VERSION "dbc-export 1 2025.20.8"

NS_ :

BS_:

BU_: ADSP APB APP APS APSB BB BMS CC CMP CMPD CP DAS DI DIF DIR DPB EPAS3P EPAS3S EPASTP EPASTS EPBL EPBR ESP EVSE FC GTW HCML HCMR HVP IBST ICR IDB LS OCS1P ODIN PARK PCS PLG PM PMF PMR PNCD PTC RADC RCM RCM2 RCM3 RCU SCCM SCM SCS SDCR TAS TCU TPMS TRCM UDS UI UIS UMC USM VC VCFRONT VCLEFT VCRIGHT VCSEC VEH

BO_ 1471 RCU_alertLog: 8 RCU
 SG_ RCU_alertID M : 0|6@1+ (1,0) [0|63] "" Vector__XXX
 SG_ RCU_alertState : 15|1@1+ (1,0) [0|1] "" Vector__XXX
 SG_ RCU_a010_sensorPowerSupply m10 : 16|1@1+ (1,0) [0|1] "" Vector__XXX
 SG_ RCU_a010_sensorHardware m10 : 17|1@1+ (1,0) [0|1] "" Vector__XXX
 SG_ RCU_a010_sensorSignal m10 : 18|1@1+ (1,0) [0|1] "" Vector__XXX
 SG_ RCU_a023_validityOnChassisBus m23 : 16|1@1+ (1,0) [0|1] "" Vector__XXX
 SG_ RCU_a023_validityOnPartyBus m23 : 17|1@1+ (1,0) [0|1] "" Vector__XXX
 SG_ RCU_a024_validityOnChassisBus m24 : 16|1@1+ (1,0) [0|1] "" Vector__XXX
 SG_ RCU_a024_validityOnPartyBus m24 : 17|1@1+ (1,0) [0|1] "" Vector__XXX
 SG_ RCU_a025_validityOnChassisBus m25 : 16|1@1+ (1,0) [0|1] "" Vector__XXX
 SG_ RCU_a025_validityOnPartyBus m25 : 17|1@1+ (1,0) [0|1] "" Vector__XXX
 SG_ RCU_a035_validityOnChassisBus m35 : 16|1@1+ (1,0) [0|1] "" Vector__XXX
 SG_ RCU_a035_validityOnPartyBus m35 : 17|1@1+ (1,0) [0|1] "" Vector__XXX
 SG_ RCU_a036_validityOnChassisBus m36 : 16|1@1+ (1,0) [0|1] "" Vector__XXX
 SG_ RCU_a036_validityOnPartyBus m36 : 17|1@1+ (1,0) [0|1] "" Vector__XXX

BO_ 998 RCU_alertMatrix: 8 RCU
 SG_ RCU_matrixIndex M : 0|4@1+ (1,0) [0|15] "" Vector__XXX
 SG_ RCU_a001_valveDriverFault m0 : 4|1@1+ (1,0) [0|1] "" Vector__XXX
 SG_ RCU_a002_solenoidValveFault m0 : 5|1@1+ (1,0) [0|1] "" Vector__XXX
 SG_ RCU_a003_pumpMotorFault m0 : 6|1@1+ (1,0) [0|1] "" Vector__XXX
 SG_ RCU_a004_supplyOvervoltage m0 : 7|1@1+ (1,0) [0|1] "" Vector__XXX
 SG_ RCU_a005_supplyUndervoltage m0 : 8|1@1+ (1,0) [0|1] "" Vector__XXX
 SG_ RCU_a006_wakeLineOpen m0 : 9|1@1+ (1,0) [0|1] "" Vector__XXX
 SG_ RCU_a007_pressureSensorFault m0 : 10|1@1+ (1,0) [0|1] "" Vector__XXX
 SG_ RCU_a008_pressureNotCalibrated m0 : 11|1@1+ (1,0) [0|1] "" Vector__XXX
 SG_ RCU_a009_brakeFluidLow m0 : 12|1@1+ (1,0) [0|1] "" Vector__XXX
 SG_ RCU_a010_pedalSensorFault m0 : 13|1@1+ (1,0) [0|1] "" Vector__XXX
 SG_ RCU_a011_idbPedalTravelMismatch m0 : 14|1@1+ (1,0) [0|1] "" Vector__XXX
 SG_ RCU_a012_pedalSensorNotCal m0 : 15|1@1+ (1,0) [0|1] "" Vector__XXX
 SG_ RCU_a013_mcuGenericFault m0 : 16|1@1+ (1,0) [0|1] "" Vector__XXX
 SG_ RCU_a014_asicTempHigh m0 : 17|1@1+ (1,0) [0|1] "" Vector__XXX
 SG_ RCU_a015_fluidLeakDetected m0 : 18|1@1+ (1,0) [0|1] "" Vector__XXX
 SG_ RCU_a016_partyBusOff m0 : 19|1@1+ (1,0) [0|1] "" Vector__XXX
 SG_ RCU_a017_chassisBusOff m0 : 20|1@1+ (1,0) [0|1] "" Vector__XXX
 SG_ RCU_a018_DItorquePathFaulted m0 : 21|1@1+ (1,0) [0|1] "" Vector__XXX
 SG_ RCU_a019_DItorquePathActive m0 : 22|1@1+ (1,0) [0|1] "" Vector__XXX
 SG_ RCU_a020_BBstatusDLC m0 : 23|1@1+ (1,0) [0|1] "" Vector__XXX
 SG_ RCU_a021_BBstatusChecksum m0 : 24|1@1+ (1,0) [0|1] "" Vector__XXX
 SG_ RCU_a022_BBstatusCounter m0 : 25|1@1+ (1,0) [0|1] "" Vector__XXX
 SG_ RCU_a023_IDBstatusDLC m0 : 26|1@1+ (1,0) [0|1] "" Vector__XXX
 SG_ RCU_a024_IDBstatusChecksum m0 : 27|1@1+ (1,0) [0|1] "" Vector__XXX
 SG_ RCU_a025_IDBstatusCounter m0 : 28|1@1+ (1,0) [0|1] "" Vector__XXX
 SG_ RCU_a026_DIchassisControlDLC m0 : 29|1@1+ (1,0) [0|1] "" Vector__XXX
 SG_ RCU_a027_DIchassisCtrlChecksum m0 : 30|1@1+ (1,0) [0|1] "" Vector__XXX
 SG_ RCU_a028_DIchassisControlCounter m0 : 31|1@1+ (1,0) [0|1] "" Vector__XXX
 SG_ RCU_a029_PMstate2DLC m0 : 32|1@1+ (1,0) [0|1] "" Vector__XXX
 SG_ RCU_a030_PMstate2Checksum m0 : 33|1@1+ (1,0) [0|1] "" Vector__XXX
 SG_ RCU_a031_PMstate2Counter m0 : 34|1@1+ (1,0) [0|1] "" Vector__XXX
 SG_ RCU_a032_VCFRONTLVPowerStateDLC m0 : 35|1@1+ (1,0) [0|1] "" Vector__XXX
 SG_ RCU_a033_VCFRONTLVPowerStateChec m0 : 36|1@1+ (1,0) [0|1] "" Vector__XXX
 SG_ RCU_a034_VCFRONTLVPowerStateCoun m0 : 37|1@1+ (1,0) [0|1] "" Vector__XXX
 SG_ RCU_a035_IDBpcpInvalid m0 : 38|1@1+ (1,0) [0|1] "" Vector__XXX
 SG_ RCU_a036_IDBpspInvalid m0 : 39|1@1+ (1,0) [0|1] "" Vector__XXX
 SG_ RCU_a037_IDBinputRodStrokeInvali m0 : 40|1@1+ (1,0) [0|1] "" Vector__XXX
 SG_ RCU_a038_DIsystemStatusDLC m0 : 41|1@1+ (1,0) [0|1] "" Vector__XXX
 SG_ RCU_a039_DIaccelPosInvalid m0 : 42|1@1+ (1,0) [0|1] "" Vector__XXX
 SG_ RCU_a040_DIgearInvalid m0 : 43|1@1+ (1,0) [0|1] "" Vector__XXX
 SG_ RCU_a041_DIsystemStatusCounter m0 : 44|1@1+ (1,0) [0|1] "" Vector__XXX
 SG_ RCU_a042_DIsystemStatusChecksum m0 : 45|1@1+ (1,0) [0|1] "" Vector__XXX
 SG_ RCU_a043_VCFRONTiBoosterLvStateI m0 : 46|1@1+ (1,0) [0|1] "" Vector__XXX
 SG_ RCU_a044_VCFRONTsensorsMIA m0 : 47|1@1+ (1,0) [0|1] "" Vector__XXX
 SG_ RCU_a045_VCFRONTtempInvalid m0 : 48|1@1+ (1,0) [0|1] "" Vector__XXX
 SG_ RCU_a046_brakeFluidLevelSNA m0 : 49|1@1+ (1,0) [0|1] "" Vector__XXX
 SG_ RCU_a047_ESPwheelSpeedsDLC m0 : 50|1@1+ (1,0) [0|1] "" Vector__XXX
 SG_ RCU_a048_ESPFrLWSSLInvalid m0 : 51|1@1+ (1,0) [0|1] "" Vector__XXX
 SG_ RCU_a049_ESPFrRWSSLInvalid m0 : 52|1@1+ (1,0) [0|1] "" Vector__XXX
 SG_ RCU_a050_ESPReLWSSLInvalid m0 : 53|1@1+ (1,0) [0|1] "" Vector__XXX
 SG_ RCU_a051_ESPReRWSSLInvalid m0 : 54|1@1+ (1,0) [0|1] "" Vector__XXX
 SG_ RCU_a052_ESPwheelSpeedsCounter m0 : 55|1@1+ (1,0) [0|1] "" Vector__XXX
 SG_ RCU_a053_ESPwheelSpeedsChecksum m0 : 56|1@1+ (1,0) [0|1] "" Vector__XXX
 SG_ RCU_a054_IDBcircuitPressFaulted m0 : 57|1@1+ (1,0) [0|1] "" Vector__XXX
 SG_ RCU_a055_IDBsimulatorPressFaulte m0 : 58|1@1+ (1,0) [0|1] "" Vector__XXX
 SG_ RCU_a056_redundantControllerIsMa m0 : 59|1@1+ (1,0) [0|1] "" Vector__XXX
 SG_ RCU_a057_PMebrCmdStateInvalid m0 : 60|1@1+ (1,0) [0|1] "" Vector__XXX
 SG_ RCU_a058_DIbrakeTorqueCommandAnd m0 : 61|1@1+ (1,0) [0|1] "" Vector__XXX

BO_ 831 RCU_info: 8 RCU
 SG_ RCU_infoIndex M : 0|8@1+ (1,0) [0|255] "" Vector__XXX
 SG_ RCU_infoPcbaID m11 : 16|8@1+ (1,0) [0|255] "" Vector__XXX
 SG_ RCU_infoAssemblyID m11 : 24|8@1+ (1,0) [0|255] "" Vector__XXX
 SG_ RCU_infoUsageID m11 : 32|16@1+ (1,0) [0|65535] "" Vector__XXX
 SG_ RCU_infoSubUsageID m11 : 48|16@1+ (1,0) [0|65535] "" Vector__XXX

BO_ 1344 SCCM_alertLog: 8 SCCM
 SG_ SCCM_alertID M : 0|15@1+ (1,0) [0|32767] "" Vector__XXX
 SG_ SCCM_alertState : 15|1@1+ (1,0) [0|1] "" Vector__XXX
 SG_ SCCM_a003_debouncePosition m3 : 16|8@1+ (1,0) [0|255] "-" Vector__XXX
 SG_ SCCM_a003_rawPosition m3 : 24|8@1+ (1,0) [0|255] "-" Vector__XXX
 SG_ SCCM_a003_errorPosition m3 : 32|8@1+ (1,0) [0|255] "-" Vector__XXX
 SG_ SCCM_a003_adcValue m3 : 40|8@1+ (1,0) [0|255] "-" Vector__XXX
 SG_ SCCM_a004_debouncePosition m4 : 16|8@1+ (1,0) [0|255] "-" Vector__XXX
 SG_ SCCM_a004_rawPosition m4 : 24|8@1+ (1,0) [0|255] "-" Vector__XXX
 SG_ SCCM_a004_errorPosition m4 : 32|8@1+ (1,0) [0|255] "-" Vector__XXX
 SG_ SCCM_a004_adcValue m4 : 40|8@1+ (1,0) [0|255] "-" Vector__XXX
 SG_ SCCM_a005_debouncePosition m5 : 16|8@1+ (1,0) [0|255] "-" Vector__XXX
 SG_ SCCM_a005_rawPosition m5 : 24|8@1+ (1,0) [0|255] "-" Vector__XXX
 SG_ SCCM_a005_errorPosition m5 : 32|8@1+ (1,0) [0|255] "-" Vector__XXX
 SG_ SCCM_a005_adcValue m5 : 40|8@1+ (1,0) [0|255] "-" Vector__XXX
 SG_ SCCM_a006_debouncePosition m6 : 16|8@1+ (1,0) [0|255] "-" Vector__XXX
 SG_ SCCM_a006_rawPosition m6 : 24|8@1+ (1,0) [0|255] "-" Vector__XXX
 SG_ SCCM_a006_errorPosition m6 : 32|8@1+ (1,0) [0|255] "-" Vector__XXX
 SG_ SCCM_a006_adcValue m6 : 40|8@1+ (1,0) [0|255] "-" Vector__XXX
 SG_ SCCM_a007_debouncePosition m7 : 16|8@1+ (1,0) [0|255] "-" Vector__XXX
 SG_ SCCM_a007_rawPosition m7 : 24|8@1+ (1,0) [0|255] "-" Vector__XXX
 SG_ SCCM_a007_errorPosition m7 : 32|8@1+ (1,0) [0|255] "-" Vector__XXX
 SG_ SCCM_a007_adcValue1 m7 : 40|8@1+ (1,0) [0|255] "-" Vector__XXX
 SG_ SCCM_a007_adcValue2 m7 : 48|8@1+ (1,0) [0|255] "-" Vector__XXX
 SG_ SCCM_a008_debouncePosition m8 : 16|8@1+ (1,0) [0|255] "-" Vector__XXX
 SG_ SCCM_a008_rawPosition m8 : 24|8@1+ (1,0) [0|255] "-" Vector__XXX
 SG_ SCCM_a008_errorPosition m8 : 32|8@1+ (1,0) [0|255] "-" Vector__XXX
 SG_ SCCM_a008_adcValue1 m8 : 40|8@1+ (1,0) [0|255] "-" Vector__XXX
 SG_ SCCM_a008_adcValue2 m8 : 48|8@1+ (1,0) [0|255] "-" Vector__XXX
 SG_ SCCM_a009_debouncePosition m9 : 16|8@1+ (1,0) [0|255] "-" Vector__XXX
 SG_ SCCM_a009_rawPosition m9 : 24|8@1+ (1,0) [0|255] "-" Vector__XXX
 SG_ SCCM_a009_errorPosition m9 : 32|8@1+ (1,0) [0|255] "-" Vector__XXX
 SG_ SCCM_a009_adcValue1 m9 : 40|8@1+ (1,0) [0|255] "-" Vector__XXX
 SG_ SCCM_a009_adcValue2 m9 : 48|8@1+ (1,0) [0|255] "-" Vector__XXX
 SG_ SCCM_a010_debouncePosition m10 : 16|8@1+ (1,0) [0|255] "-" Vector__XXX
 SG_ SCCM_a010_rawPosition m10 : 24|8@1+ (1,0) [0|255] "-" Vector__XXX
 SG_ SCCM_a010_errorPosition m10 : 32|8@1+ (1,0) [0|255] "-" Vector__XXX
 SG_ SCCM_a010_adcValue1 m10 : 40|8@1+ (1,0) [0|255] "-" Vector__XXX
 SG_ SCCM_a010_adcValue2 m10 : 48|8@1+ (1,0) [0|255] "-" Vector__XXX
 SG_ SCCM_a011_debouncePosition m11 : 16|8@1+ (1,0) [0|255] "-" Vector__XXX
 SG_ SCCM_a011_rawPosition m11 : 24|8@1+ (1,0) [0|255] "-" Vector__XXX
 SG_ SCCM_a011_errorPosition m11 : 32|8@1+ (1,0) [0|255] "-" Vector__XXX
 SG_ SCCM_a011_adcValue1 m11 : 40|8@1+ (1,0) [0|255] "-" Vector__XXX
 SG_ SCCM_a011_adcValue2 m11 : 48|8@1+ (1,0) [0|255] "-" Vector__XXX
 SG_ SCCM_a012_debouncePosition m12 : 16|8@1+ (1,0) [0|255] "-" Vector__XXX
 SG_ SCCM_a012_rawPosition m12 : 24|8@1+ (1,0) [0|255] "-" Vector__XXX
 SG_ SCCM_a012_errorPosition m12 : 32|8@1+ (1,0) [0|255] "-" Vector__XXX
 SG_ SCCM_a012_adcValue1 m12 : 40|8@1+ (1,0) [0|255] "-" Vector__XXX
 SG_ SCCM_a012_adcValue2 m12 : 48|8@1+ (1,0) [0|255] "-" Vector__XXX
 SG_ SCCM_a013_voltage m13 : 16|8@1+ (1,0) [0|255] "-" Vector__XXX
 SG_ SCCM_a014_voltage m14 : 16|8@1+ (1,0) [0|255] "-" Vector__XXX
 SG_ SCCM_a015_intMainIndex m15 : 16|8@1+ (1,0) [0|255] "-" Vector__XXX
 SG_ SCCM_a015_intSubIndex m15 : 24|8@1+ (1,0) [0|255] "-" Vector__XXX
 SG_ SCCM_a015_intMemIndex m15 : 32|8@1+ (1,0) [0|255] "-" Vector__XXX
 SG_ SCCM_a016_mainAdcTest m16 : 16|4@1+ (1,0) [0|15] "-" Vector__XXX
 SG_ SCCM_a016_mainCpuTest m16 : 20|4@1+ (1,0) [0|15] "-" Vector__XXX
 SG_ SCCM_a016_wdtTest m16 : 24|4@1+ (1,0) [0|15] "-" Vector__XXX
 SG_ SCCM_a016_subCpuTest m16 : 28|4@1+ (1,0) [0|15] "-" Vector__XXX
 SG_ SCCM_a016_subAdcTest m16 : 32|4@1+ (1,0) [0|15] "-" Vector__XXX
 SG_ SCCM_a017_mainRamTest m17 : 16|4@1+ (1,0) [0|15] "-" Vector__XXX
 SG_ SCCM_a017_mainRomTest m17 : 20|4@1+ (1,0) [0|15] "-" Vector__XXX
 SG_ SCCM_a017_stackHardLimitTest m17 : 24|4@1+ (1,0) [0|15] "-" Vector__XXX
 SG_ SCCM_a017_mainDataFlashTest m17 : 28|4@1+ (1,0) [0|15] "-" Vector__XXX
 SG_ SCCM_a017_subRamTest m17 : 32|4@1+ (1,0) [0|15] "-" Vector__XXX
 SG_ SCCM_a017_subRomTest m17 : 36|4@1+ (1,0) [0|15] "-" Vector__XXX
 SG_ SCCM_a017_subStackHardLimitTest m17 : 40|4@1+ (1,0) [0|15] "-" Vector__XXX
 SG_ SCCM_a017_svError m17 : 44|16@1+ (1,0) [0|65535] "-" Vector__XXX
 SG_ SCCM_a018_internalSASState m18 : 16|8@1+ (1,0) [0|255] "-" Vector__XXX
 SG_ SCCM_a019_internalSASState m19 : 16|8@1+ (1,0) [0|255] "-" Vector__XXX
 SG_ SCCM_a020_internalSASState m20 : 16|8@1+ (1,0) [0|255] "-" Vector__XXX
 SG_ SCCM_a021_adcValue1 m21 : 16|8@1+ (1,0) [0|255] "-" Vector__XXX
 SG_ SCCM_a021_adcValue2 m21 : 24|8@1+ (1,0) [0|255] "-" Vector__XXX
 SG_ SCCM_a021_adcValue3 m21 : 32|8@1+ (1,0) [0|255] "-" Vector__XXX
 SG_ SCCM_a021_adcValue4 m21 : 40|8@1+ (1,0) [0|255] "-" Vector__XXX
 SG_ SCCM_a021_adcValue5 m21 : 48|8@1+ (1,0) [0|255] "-" Vector__XXX
 SG_ SCCM_a021_adcValue6 m21 : 56|8@1+ (1,0) [0|255] "-" Vector__XXX
 SG_ SCCM_a022_adcValue1 m22 : 16|8@1+ (1,0) [0|255] "-" Vector__XXX
 SG_ SCCM_a022_adcValue2 m22 : 24|8@1+ (1,0) [0|255] "-" Vector__XXX
 SG_ SCCM_a022_adcValue3 m22 : 32|8@1+ (1,0) [0|255] "-" Vector__XXX
 SG_ SCCM_a022_adcValue4 m22 : 40|8@1+ (1,0) [0|255] "-" Vector__XXX
 SG_ SCCM_a022_adcValue5 m22 : 48|8@1+ (1,0) [0|255] "-" Vector__XXX
 SG_ SCCM_a022_adcValue6 m22 : 56|8@1+ (1,0) [0|255] "-" Vector__XXX
 SG_ SCCM_a023_adcValue1 m23 : 16|8@1+ (1,0) [0|255] "-" Vector__XXX
 SG_ SCCM_a023_adcValue2 m23 : 24|8@1+ (1,0) [0|255] "-" Vector__XXX
 SG_ SCCM_a023_adcValue3 m23 : 32|8@1+ (1,0) [0|255] "-" Vector__XXX
 SG_ SCCM_a023_adcValue4 m23 : 40|8@1+ (1,0) [0|255] "-" Vector__XXX
 SG_ SCCM_a023_adcValue5 m23 : 48|8@1+ (1,0) [0|255] "-" Vector__XXX
 SG_ SCCM_a023_adcValue6 m23 : 56|8@1+ (1,0) [0|255] "-" Vector__XXX
 SG_ SCCM_a024_adcValue1 m24 : 16|8@1+ (1,0) [0|255] "-" Vector__XXX
 SG_ SCCM_a024_adcValue2 m24 : 24|8@1+ (1,0) [0|255] "-" Vector__XXX
 SG_ SCCM_a024_adcValue3 m24 : 32|8@1+ (1,0) [0|255] "-" Vector__XXX
 SG_ SCCM_a024_adcValue4 m24 : 40|8@1+ (1,0) [0|255] "-" Vector__XXX
 SG_ SCCM_a024_adcValue5 m24 : 48|8@1+ (1,0) [0|255] "-" Vector__XXX
 SG_ SCCM_a024_adcValue6 m24 : 56|8@1+ (1,0) [0|255] "-" Vector__XXX
 SG_ SCCM_a025_taskState m25 : 16|16@1+ (1,0) [0|65535] "-" Vector__XXX
 SG_ SCCM_a026_debouncePosition m26 : 16|8@1+ (1,0) [0|255] "-" Vector__XXX
 SG_ SCCM_a026_rawPosition m26 : 24|8@1+ (1,0) [0|255] "-" Vector__XXX
 SG_ SCCM_a026_errorPosition m26 : 32|8@1+ (1,0) [0|255] "-" Vector__XXX
 SG_ SCCM_a026_adcValue1 m26 : 40|8@1+ (1,0) [0|255] "-" Vector__XXX
 SG_ SCCM_a026_adcValue2 m26 : 48|8@1+ (1,0) [0|255] "-" Vector__XXX
 SG_ SCCM_a027_debouncePosition m27 : 16|8@1+ (1,0) [0|255] "-" Vector__XXX
 SG_ SCCM_a027_rawPosition m27 : 24|8@1+ (1,0) [0|255] "-" Vector__XXX
 SG_ SCCM_a027_errorPosition m27 : 32|8@1+ (1,0) [0|255] "-" Vector__XXX
 SG_ SCCM_a027_adcValue1 m27 : 40|8@1+ (1,0) [0|255] "-" Vector__XXX
 SG_ SCCM_a027_adcValue2 m27 : 48|8@1+ (1,0) [0|255] "-" Vector__XXX
 SG_ SCCM_a028_debouncePosition m28 : 16|8@1+ (1,0) [0|255] "-" Vector__XXX
 SG_ SCCM_a028_rawPosition m28 : 24|8@1+ (1,0) [0|255] "-" Vector__XXX
 SG_ SCCM_a028_errorPosition m28 : 32|8@1+ (1,0) [0|255] "-" Vector__XXX
 SG_ SCCM_a028_adcValue1 m28 : 40|8@1+ (1,0) [0|255] "-" Vector__XXX
 SG_ SCCM_a028_adcValue2 m28 : 48|8@1+ (1,0) [0|255] "-" Vector__XXX
 SG_ SCCM_a029_debouncePosition m29 : 16|8@1+ (1,0) [0|255] "-" Vector__XXX
 SG_ SCCM_a029_rawPosition m29 : 24|8@1+ (1,0) [0|255] "-" Vector__XXX
 SG_ SCCM_a029_errorPosition m29 : 32|8@1+ (1,0) [0|255] "-" Vector__XXX
 SG_ SCCM_a029_adcValue1 m29 : 40|8@1+ (1,0) [0|255] "-" Vector__XXX
 SG_ SCCM_a029_adcValue2 m29 : 48|8@1+ (1,0) [0|255] "-" Vector__XXX
 SG_ SCCM_a061_voltage m61 : 16|8@1+ (0.1,0) [0|25.5] "V" Vector__XXX
 SG_ SCCM_a062_voltage m62 : 16|8@1+ (0.1,0) [0|25.5] "V" Vector__XXX
 SG_ SCCM_a063_UntrimmedAngle m63 : 16|16@1+ (0.1,-819.2) [-819.2|5734.3] "deg" Vector__XXX
 SG_ SCCM_a064_Speed m64 : 16|16@1+ (0.5,-4096) [-4096|28671.5] "deg/s" Vector__XXX
 SG_ SCCM_a065_M1RawAngleCurrent m65 : 16|12@1+ (0.08791209,0) [0|360.00000855] "deg" Vector__XXX
 SG_ SCCM_a065_M1RawAnglePrevious m65 : 28|12@1+ (0.08791209,0) [0|360.00000855] "deg" Vector__XXX
 SG_ SCCM_a065_M2RawAngleCurrent m65 : 40|12@1+ (0.08791209,0) [0|360.00000855] "deg" Vector__XXX
 SG_ SCCM_a065_M2RawAnglePrevious m65 : 52|12@1+ (0.08791209,0) [0|360.00000855] "deg" Vector__XXX
 SG_ SCCM_a066_M1RawAngleCurrent m66 : 16|12@1+ (0.08791209,0) [0|360.00000855] "deg" Vector__XXX
 SG_ SCCM_a066_M1RawAnglePrevious m66 : 28|12@1+ (0.08791209,0) [0|360.00000855] "deg" Vector__XXX
 SG_ SCCM_a066_M2RawAngleCurrent m66 : 40|12@1+ (0.08791209,0) [0|360.00000855] "deg" Vector__XXX
 SG_ SCCM_a066_M2RawAnglePrevious m66 : 52|12@1+ (0.08791209,0) [0|360.00000855] "deg" Vector__XXX
 SG_ SCCM_a071_M1LogicBISTFailed m71 : 16|1@1+ (1,0) [0|1] "" Vector__XXX
 SG_ SCCM_a071_M1PowerOnReset m71 : 17|1@1+ (1,0) [0|1] "" Vector__XXX
 SG_ SCCM_a071_M1UnderVoltage m71 : 18|1@1+ (1,0) [0|1] "" Vector__XXX
 SG_ SCCM_a071_M1OverVoltage m71 : 19|1@1+ (1,0) [0|1] "" Vector__XXX
 SG_ SCCM_a071_M1DualBitError m71 : 20|1@1+ (1,0) [0|1] "" Vector__XXX
 SG_ SCCM_a071_M1RefVoltageOutOfRange m71 : 21|1@1+ (1,0) [0|1] "" Vector__XXX
 SG_ SCCM_a071_M1RegisterParityError m71 : 22|1@1+ (1,0) [0|1] "" Vector__XXX
 SG_ SCCM_a071_M1OscillatorFreqError m71 : 23|1@1+ (1,0) [0|1] "" Vector__XXX
 SG_ SCCM_a071_M1SignalOutOfRange m71 : 24|1@1+ (1,0) [0|1] "" Vector__XXX
 SG_ SCCM_a071_M1TempOutOfRange m71 : 25|1@1+ (1,0) [0|1] "" Vector__XXX
 SG_ SCCM_a071_M1AngleMismatch m71 : 26|1@1+ (1,0) [0|1] "" Vector__XXX
 SG_ SCCM_a071_M1RadiusOutOfRange m71 : 27|1@1+ (1,0) [0|1] "" Vector__XXX
 SG_ SCCM_a071_M2LogicBISTFailed m71 : 28|1@1+ (1,0) [0|1] "" Vector__XXX
 SG_ SCCM_a071_M2PowerOnReset m71 : 29|1@1+ (1,0) [0|1] "" Vector__XXX
 SG_ SCCM_a071_M2UnderVoltage m71 : 30|1@1+ (1,0) [0|1] "" Vector__XXX
 SG_ SCCM_a071_M2OverVoltage m71 : 31|1@1+ (1,0) [0|1] "" Vector__XXX
 SG_ SCCM_a071_M2DualBitError m71 : 32|1@1+ (1,0) [0|1] "" Vector__XXX
 SG_ SCCM_a071_M2RefVoltageOutOfRange m71 : 33|1@1+ (1,0) [0|1] "" Vector__XXX
 SG_ SCCM_a071_M2RegisterParityError m71 : 34|1@1+ (1,0) [0|1] "" Vector__XXX
 SG_ SCCM_a071_M2OscillatorFreqError m71 : 35|1@1+ (1,0) [0|1] "" Vector__XXX
 SG_ SCCM_a071_M2SignalOutOfRange m71 : 36|1@1+ (1,0) [0|1] "" Vector__XXX
 SG_ SCCM_a071_M2TempOutOfRange m71 : 37|1@1+ (1,0) [0|1] "" Vector__XXX
 SG_ SCCM_a071_M2AngleMismatch m71 : 38|1@1+ (1,0) [0|1] "" Vector__XXX
 SG_ SCCM_a071_M2RadiusOutOfRange m71 : 39|1@1+ (1,0) [0|1] "" Vector__XXX
 SG_ SCCM_a071_M1ProcessLogicFailed m71 : 40|1@1+ (1,0) [0|1] "" Vector__XXX
 SG_ SCCM_a071_M2ProcessLogicFailed m71 : 41|1@1+ (1,0) [0|1] "" Vector__XXX
 SG_ SCCM_a071_TSOSCHighFreqError m71 : 42|1@1+ (1,0) [0|1] "" Vector__XXX
 SG_ SCCM_a071_TSOSCLowFreqError m71 : 43|1@1+ (1,0) [0|1] "" Vector__XXX
 SG_ SCCM_a071_TSOPRStatMismatch m71 : 44|1@1+ (1,0) [0|1] "" Vector__XXX
 SG_ SCCM_a071_TSCRCStatError m71 : 45|1@1+ (1,0) [0|1] "" Vector__XXX
 SG_ SCCM_a071_TSFrameStatError m71 : 46|1@1+ (1,0) [0|1] "" Vector__XXX
 SG_ SCCM_a071_TSOverVoltage m71 : 47|1@1+ (1,0) [0|1] "" Vector__XXX
 SG_ SCCM_a071_TSUnderVoltage m71 : 48|1@1+ (1,0) [0|1] "" Vector__XXX
 SG_ SCCM_a071_TSPowerOnReset m71 : 49|1@1+ (1,0) [0|1] "" Vector__XXX
 SG_ SCCM_a071_TSLDOStatError m71 : 50|1@1+ (1,0) [0|1] "" Vector__XXX
 SG_ SCCM_a071_TSTempOutOfRange m71 : 51|1@1+ (1,0) [0|1] "" Vector__XXX
 SG_ SCCM_a071_TSAlertIntegrityCheck m71 : 52|1@1+ (1,0) [0|1] "" Vector__XXX
 SG_ SCCM_a071_TSMemoryCRCError m71 : 53|1@1+ (1,0) [0|1] "" Vector__XXX
 SG_ SCCM_a071_TSAFECheck m71 : 54|1@1+ (1,0) [0|1] "" Vector__XXX
 SG_ SCCM_a071_TSADCCheck m71 : 55|1@1+ (1,0) [0|1] "" Vector__XXX
 SG_ SCCM_a071_TSConfigFault m71 : 56|1@1+ (1,0) [0|1] "" Vector__XXX
 SG_ SCCM_a072_M1CRCCalculated m72 : 16|4@1+ (1,0) [0|15] "" Vector__XXX
 SG_ SCCM_a072_M1CRCReceived m72 : 20|4@1+ (1,0) [0|15] "" Vector__XXX
 SG_ SCCM_a072_M2CRCCalculated m72 : 24|4@1+ (1,0) [0|15] "" Vector__XXX
 SG_ SCCM_a072_M2CRCReceived m72 : 28|4@1+ (1,0) [0|15] "" Vector__XXX
 SG_ SCCM_a072_TSCRCCalculated m72 : 32|4@1+ (1,0) [0|15] "" Vector__XXX
 SG_ SCCM_a072_TSCRCReceived m72 : 36|4@1+ (1,0) [0|15] "" Vector__XXX
 SG_ SCCM_a075_ClockOutOfRange m75 : 16|1@1+ (1,0) [0|1] "" Vector__XXX
 SG_ SCCM_a075_ExtWatchdogTestFailed m75 : 17|1@1+ (1,0) [0|1] "" Vector__XXX
 SG_ SCCM_a075_InterruptMonitorError m75 : 18|1@1+ (1,0) [0|1] "" Vector__XXX
 SG_ SCCM_a076_RAMTestFailed m76 : 16|1@1+ (1,0) [0|1] "" Vector__XXX
 SG_ SCCM_a076_NVMTestFailed m76 : 17|1@1+ (1,0) [0|1] "" Vector__XXX
 SG_ SCCM_a077_M1ExpectAngleCurrent m77 : 16|12@1+ (0.08791209,0) [0|360.00000855] "deg" Vector__XXX
 SG_ SCCM_a077_M1ExpectAnglePrevious m77 : 28|12@1+ (0.08791209,0) [0|360.00000855] "deg" Vector__XXX
 SG_ SCCM_a077_M1AngleCurrent m77 : 40|12@1+ (0.08791209,0) [0|360.00000855] "deg" Vector__XXX
 SG_ SCCM_a077_M1AnglePrevious m77 : 52|12@1+ (0.08791209,0) [0|360.00000855] "deg" Vector__XXX
 SG_ SCCM_a079_ChipTemperature m79 : 16|11@1+ (0.1,-50) [-50|154.7] "degC" Vector__XXX
 SG_ SCCM_a081_StartupTestStatus m81 : 16|3@1+ (1,0) [0|7] "" Vector__XXX
 SG_ SCCM_a081_sCheckTestFailedData m81 : 19|8@1+ (1,0) [0|255] "" Vector__XXX
 SG_ SCCM_a081_sBootTestFailedData m81 : 27|16@1+ (1,0) [0|65535] "" Vector__XXX
 SG_ SCCM_a081_BISTTestFailedData m81 : 43|16@1+ (1,0) [0|65535] "" Vector__XXX
 SG_ SCCM_a082_RuntimeTestStatus m82 : 16|2@1+ (1,0) [0|3] "" Vector__XXX
 SG_ SCCM_a082_sCheckTestFailedData m82 : 18|8@1+ (1,0) [0|255] "" Vector__XXX
 SG_ SCCM_a082_ArrayIntegrFailedData m82 : 26|8@1+ (1,0) [0|255] "" Vector__XXX
 SG_ SCCM_a121_turnIndicatorStalkAngl m121 : 16|12@1+ (0.1,-180) [-180|229.5] "deg" Vector__XXX
 SG_ SCCM_a121_turnIndicatorHallAngle m121 : 28|12@1+ (0.1,-180) [-180|229.5] "deg" Vector__XXX
 SG_ SCCM_a122_turnIndicatorSpeed m122 : 16|12@1+ (0.02,-36) [-36|45.9] "deg/ms" Vector__XXX
 SG_ SCCM_a123_turnIndicatorStalkAngl m123 : 16|12@1+ (0.1,-180) [-180|229.5] "deg" Vector__XXX
 SG_ SCCM_a124_turnIndicatorStalkAngl m124 : 16|12@1+ (0.1,-180) [-180|229.5] "deg" Vector__XXX
 SG_ SCCM_a125_turnIndicatorHallAngle m125 : 16|12@1+ (0.1,-180) [-180|229.5] "deg" Vector__XXX
 SG_ SCCM_a125_turnIndicatorVectorAng m125 : 28|12@1+ (0.1,-180) [-180|229.5] "deg" Vector__XXX
 SG_ SCCM_a126_turnIndicatorXVectorOu m126 : 16|1@1+ (1,0) [0|1] "" Vector__XXX
 SG_ SCCM_a126_turnIndicatorYVectorOu m126 : 17|1@1+ (1,0) [0|1] "" Vector__XXX
 SG_ SCCM_a126_turnIndicatorZVectorOu m126 : 18|1@1+ (1,0) [0|1] "" Vector__XXX
 SG_ SCCM_a126_turnIndicatorResu_0001 m126 : 19|1@1+ (1,0) [0|1] "" Vector__XXX
 SG_ SCCM_a126_turnIndicatorXMagnitud m126 : 24|8@1+ (1,0) [0|255] "mT" Vector__XXX
 SG_ SCCM_a126_turnIndicatorYMagnitud m126 : 32|8@1+ (1,0) [0|255] "mT" Vector__XXX
 SG_ SCCM_a126_turnIndicatorZMagnitud m126 : 40|8@1+ (1,0) [0|255] "mT" Vector__XXX
 SG_ SCCM_a126_turnIndicatorResultant m126 : 48|8@1+ (1,0) [0|255] "mT" Vector__XXX

BO_ 1359 SCCM_alertMatrix: 8 SCCM
 SG_ SCCM_matrixIndex M : 0|4@1+ (1,0) [0|15] "" Vector__XXX
 SG_ SCCM_a001_CANBusOff m0 : 4|1@1+ (1,0) [0|1] "" Vector__XXX
 SG_ SCCM_a002_CANTOut m0 : 5|1@1+ (1,0) [0|1] "" Vector__XXX
 SG_ SCCM_a003_highBeamOpen m0 : 6|1@1+ (1,0) [0|1] "" Vector__XXX
 SG_ SCCM_a004_highBeamShortToGND m0 : 7|1@1+ (1,0) [0|1] "" Vector__XXX
 SG_ SCCM_a005_tipWipeOpen m0 : 8|1@1+ (1,0) [0|1] "" Vector__XXX
 SG_ SCCM_a006_tipWipeShortToGND m0 : 9|1@1+ (1,0) [0|1] "" Vector__XXX
 SG_ SCCM_a007_turnIndComInfo m0 : 10|1@1+ (1,0) [0|1] "" Vector__XXX
 SG_ SCCM_a008_turnIndInvalidTrans m0 : 11|1@1+ (1,0) [0|1] "" Vector__XXX
 SG_ SCCM_a009_turnIndOpen m0 : 12|1@1+ (1,0) [0|1] "" Vector__XXX
 SG_ SCCM_a010_turnIndShortToGnd m0 : 13|1@1+ (1,0) [0|1] "" Vector__XXX
 SG_ SCCM_a011_turnIndHWErr m0 : 14|1@1+ (1,0) [0|1] "" Vector__XXX
 SG_ SCCM_a012_turnGenErr m0 : 15|1@1+ (1,0) [0|1] "" Vector__XXX
 SG_ SCCM_a013_voltageHigh m0 : 16|1@1+ (1,0) [0|1] "" Vector__XXX
 SG_ SCCM_a014_voltageLow m0 : 17|1@1+ (1,0) [0|1] "" Vector__XXX
 SG_ SCCM_a015_softwareError m0 : 18|1@1+ (1,0) [0|1] "" Vector__XXX
 SG_ SCCM_a016_hardwareError m0 : 19|1@1+ (1,0) [0|1] "" Vector__XXX
 SG_ SCCM_a017_memoryError m0 : 20|1@1+ (1,0) [0|1] "" Vector__XXX
 SG_ SCCM_a018_angleSpeedOutOfRange m0 : 21|1@1+ (1,0) [0|1] "" Vector__XXX
 SG_ SCCM_a019_angleOutOfRange m0 : 22|1@1+ (1,0) [0|1] "" Vector__XXX
 SG_ SCCM_a020_angleInternalError m0 : 23|1@1+ (1,0) [0|1] "" Vector__XXX
 SG_ SCCM_a021_gearStalkSignalInvalid m0 : 24|1@1+ (1,0) [0|1] "" Vector__XXX
 SG_ SCCM_a022_gearStalkOpenCircuit m0 : 25|1@1+ (1,0) [0|1] "" Vector__XXX
 SG_ SCCM_a023_gearStalkShortCircuit m0 : 26|1@1+ (1,0) [0|1] "" Vector__XXX
 SG_ SCCM_a024_gearStalkGenErr m0 : 27|1@1+ (1,0) [0|1] "" Vector__XXX
 SG_ SCCM_a025_runTimeError m0 : 28|1@1+ (1,0) [0|1] "" Vector__XXX
 SG_ SCCM_a026_parkButtonInvalidSigna m0 : 29|1@1+ (1,0) [0|1] "" Vector__XXX
 SG_ SCCM_a027_parkButtonOpenCircuit m0 : 30|1@1+ (1,0) [0|1] "" Vector__XXX
 SG_ SCCM_a028_parkButtonShortToGroun m0 : 31|1@1+ (1,0) [0|1] "" Vector__XXX
 SG_ SCCM_a029_parkButtonMalfunction m0 : 32|1@1+ (1,0) [0|1] "" Vector__XXX
 SG_ SCCM_a061_voltageHigh_2 m1 : 4|1@1+ (1,0) [0|1] "" Vector__XXX
 SG_ SCCM_a062_voltageLow_2 m1 : 5|1@1+ (1,0) [0|1] "" Vector__XXX
 SG_ SCCM_a063_angleOutOfRange_2 m1 : 6|1@1+ (1,0) [0|1] "" Vector__XXX
 SG_ SCCM_a064_angleSpeedOutOfRange_2 m1 : 7|1@1+ (1,0) [0|1] "" Vector__XXX
 SG_ SCCM_a065_angleNotPlausible m1 : 8|1@1+ (1,0) [0|1] "" Vector__XXX
 SG_ SCCM_a066_angleSpeedNotPlausible m1 : 9|1@1+ (1,0) [0|1] "" Vector__XXX
 SG_ SCCM_a067_CANBusOff_2 m1 : 10|1@1+ (1,0) [0|1] "" Vector__XXX
 SG_ SCCM_a068_CANLVPowerState_LOC m1 : 11|1@1+ (1,0) [0|1] "" Vector__XXX
 SG_ SCCM_a069_calibrationMismatch m1 : 12|1@1+ (1,0) [0|1] "" Vector__XXX
 SG_ SCCM_a070_angleTrimMismatch m1 : 13|1@1+ (1,0) [0|1] "" Vector__XXX
 SG_ SCCM_a071_angleHallSensorError m1 : 14|1@1+ (1,0) [0|1] "" Vector__XXX
 SG_ SCCM_a072_spiBitErrors m1 : 15|1@1+ (1,0) [0|1] "" Vector__XXX
 SG_ SCCM_a073_watchdogReset m1 : 16|1@1+ (1,0) [0|1] "" Vector__XXX
 SG_ SCCM_a074_PLLLossOfLock m1 : 17|1@1+ (1,0) [0|1] "" Vector__XXX
 SG_ SCCM_a075_hardwareError_2 m1 : 18|1@1+ (1,0) [0|1] "" Vector__XXX
 SG_ SCCM_a076_memoryError_2 m1 : 19|1@1+ (1,0) [0|1] "" Vector__XXX
 SG_ SCCM_a077_gearAngleNotPlausible m1 : 20|1@1+ (1,0) [0|1] "" Vector__XXX
 SG_ SCCM_a078_ADCCalibrationError m1 : 21|1@1+ (1,0) [0|1] "" Vector__XXX
 SG_ SCCM_a079_chipTempOutOfRange m1 : 22|1@1+ (1,0) [0|1] "" Vector__XXX
 SG_ SCCM_a080_ADCSelfTestFailed m1 : 23|1@1+ (1,0) [0|1] "" Vector__XXX
 SG_ SCCM_a081_startupTestFailed m1 : 24|1@1+ (1,0) [0|1] "" Vector__XXX
 SG_ SCCM_a082_runtimeTestFailed m1 : 25|1@1+ (1,0) [0|1] "" Vector__XXX
 SG_ SCCM_a121_turnIndicatorAngleInva m2 : 4|1@1+ (1,0) [0|1] "" Vector__XXX
 SG_ SCCM_a122_turnIndicatorSpeedInva m2 : 5|1@1+ (1,0) [0|1] "" Vector__XXX
 SG_ SCCM_a123_turnIndicatorStuckActi m2 : 6|1@1+ (1,0) [0|1] "" Vector__XXX
 SG_ SCCM_a124_turnIndicatorIdleInval m2 : 7|1@1+ (1,0) [0|1] "" Vector__XXX
 SG_ SCCM_a125_turnIndicatorHallAngle m2 : 8|1@1+ (1,0) [0|1] "" Vector__XXX
 SG_ SCCM_a126_turnIndicatorHallMagOu m2 : 9|1@1+ (1,0) [0|1] "" Vector__XXX

BO_ 816 SCCM_info: 8 SCCM
 SG_ SCCM_infoIndex M : 0|8@1+ (1,0) [0|255] "" Vector__XXX
 SG_ SCCM_infoBuildType m10 : 8|8@1+ (1,0) [0|255] "" Vector__XXX
 SG_ SCCM_infoBuildConfigId m10 : 16|16@1+ (1,0) [0|65535] "" Vector__XXX
 SG_ SCCM_infoHardwareId m10 : 32|16@1+ (1,0) [0|65535] "" Vector__XXX
 SG_ SCCM_infoComponentId m10 : 48|16@1+ (1,0) [0|65535] "" Vector__XXX
 SG_ SCCM_infoPcbaId m11 : 16|8@1+ (1,0) [0|255] "" Vector__XXX
 SG_ SCCM_infoAssemblyId m11 : 24|8@1+ (1,0) [0|255] "" Vector__XXX
 SG_ SCCM_infoUsageId m11 : 32|16@1+ (1,0) [0|65535] "" Vector__XXX
 SG_ SCCM_infoSubUsageId m11 : 48|16@1+ (1,0) [0|65535] "" Vector__XXX
 SG_ SCCM_infoPlatformType m13 : 8|8@1+ (1,0) [0|255] "" Vector__XXX
 SG_ SCCM_infoAppCrc m13 : 39|32@0+ (1,0) [0|4294967295] "" Vector__XXX
 SG_ SCCM_infoBootSvnRev m14 : 8|24@1+ (1,0) [0|16777215] "" Vector__XXX
 SG_ SCCM_infoBootSvnUrlHash m14 : 32|32@1+ (1,0) [0|4294967295] "" Vector__XXX
 SG_ SCCM_infoSubcomponent1Version m16 : 16|32@1+ (1,0) [0|4294967295] "" Vector__XXX
 SG_ SCCM_infoAppSvnHash m17 : 8|56@1+ (1,0) [0|7.20575940379e+16] "" Vector__XXX
 SG_ SCCM_infoBootSvnHash m18 : 8|56@1+ (1,0) [0|7.20575940379e+16] "" Vector__XXX
 SG_ SCCM_infoUdsProtoVersion m20 : 8|8@1+ (1,0) [0|255] "" Vector__XXX
 SG_ SCCM_infoBootCrc m20 : 32|32@1+ (1,0) [0|4294967295] "" Vector__XXX

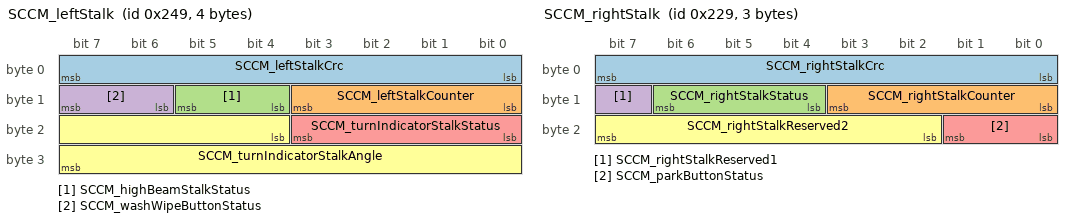
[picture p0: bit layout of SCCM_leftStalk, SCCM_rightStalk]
BO_ 585 SCCM_leftStalk: 4 SCCM
 SG_ SCCM_leftStalkCrc : 0|8@1+ (1,0) [0|255] "" Vector__XXX
 SG_ SCCM_leftStalkCounter : 8|4@1+ (1,0) [0|15] "" Vector__XXX
 SG_ SCCM_highBeamStalkStatus : 12|2@1+ (1,0) [0|2] "" Vector__XXX
 SG_ SCCM_washWipeButtonStatus : 14|2@1+ (1,0) [0|2] "" Vector__XXX
 SG_ SCCM_turnIndicatorStalkStatus : 16|4@1+ (1,0) [0|15] "" Vector__XXX
 SG_ SCCM_turnIndicatorStalkAngle : 20|12@1+ (0.1,-180) [-180|180] "deg" Vector__XXX

BO_ 553 SCCM_rightStalk: 3 SCCM
 SG_ SCCM_rightStalkCrc : 0|8@1+ (1,0) [0|255] "" Vector__XXX
 SG_ SCCM_rightStalkCounter : 8|4@1+ (1,0) [0|15] "" Vector__XXX
 SG_ SCCM_rightStalkStatus : 12|3@1+ (1,0) [0|7] "" Vector__XXX
 SG_ SCCM_rightStalkReserved1 : 15|1@1+ (1,0) [0|1] "" Vector__XXX
 SG_ SCCM_parkButtonStatus : 16|2@1+ (1,0) [0|2] "" Vector__XXX
 SG_ SCCM_rightStalkReserved2 : 18|6@1+ (1,0) [0|63] "" Vector__XXX

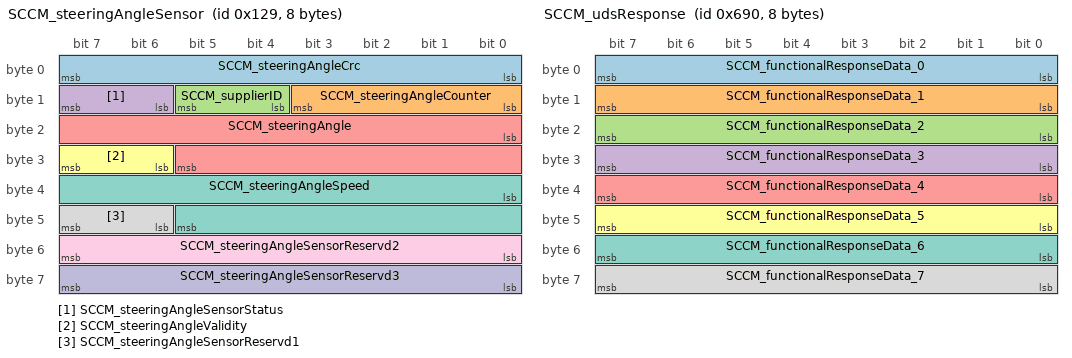
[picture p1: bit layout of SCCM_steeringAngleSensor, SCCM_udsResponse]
BO_ 297 SCCM_steeringAngleSensor: 8 SCCM
 SG_ SCCM_steeringAngleCrc : 0|8@1+ (1,0) [0|255] "" Vector__XXX
 SG_ SCCM_steeringAngleCounter : 8|4@1+ (1,0) [0|15] "" Vector__XXX
 SG_ SCCM_supplierID : 12|2@1+ (1,0) [0|3] "" Vector__XXX
 SG_ SCCM_steeringAngleSensorStatus : 14|2@1+ (1,0) [0|3] "" Vector__XXX
 SG_ SCCM_steeringAngle : 16|14@1+ (0.1,-819.2) [-819.2|819] "deg" Vector__XXX
 SG_ SCCM_steeringAngleValidity : 30|2@1+ (1,0) [0|2] "" Vector__XXX
 SG_ SCCM_steeringAngleSpeed : 32|14@1+ (0.5,-4096) [-4096|4095.5] "deg/s" Vector__XXX
 SG_ SCCM_steeringAngleSensorReservd1 : 46|2@1+ (1,0) [0|3] "" Vector__XXX
 SG_ SCCM_steeringAngleSensorReservd2 : 48|8@1+ (1,0) [0|255] "" Vector__XXX
 SG_ SCCM_steeringAngleSensorReservd3 : 56|8@1+ (1,0) [0|255] "" Vector__XXX

BO_ 1680 SCCM_udsResponse: 8 SCCM
 SG_ SCCM_functionalResponseData_0 : 7|8@0+ (1,0) [0|255] "" Vector__XXX
 SG_ SCCM_functionalResponseData_1 : 15|8@0+ (1,0) [0|255] "" Vector__XXX
 SG_ SCCM_functionalResponseData_2 : 23|8@0+ (1,0) [0|255] "" Vector__XXX
 SG_ SCCM_functionalResponseData_3 : 31|8@0+ (1,0) [0|255] "" Vector__XXX
 SG_ SCCM_functionalResponseData_4 : 39|8@0+ (1,0) [0|255] "" Vector__XXX
 SG_ SCCM_functionalResponseData_5 : 47|8@0+ (1,0) [0|255] "" Vector__XXX
 SG_ SCCM_functionalResponseData_6 : 55|8@0+ (1,0) [0|255] "" Vector__XXX
 SG_ SCCM_functionalResponseData_7 : 63|8@0+ (1,0) [0|255] "" Vector__XXX

BO_ 1356 SCM_alertLog: 8 SCM
 SG_ SCM_alertID M : 0|15@1+ (1,0) [0|32767] "" Vector__XXX
 SG_ SCM_alertType : 15|1@1+ (1,0) [0|1] "" Vector__XXX
 SG_ SCM_a074_voltageWithRo m74 : 16|12@1+ (1,0) [0|4095] "" Vector__XXX
 SG_ SCM_a074_voltageWithoutRo m74 : 28|12@1+ (1,0) [0|4095] "" Vector__XXX

BO_ 815 SCM_alertMatrix1: 8 SCM
 SG_ SCM_a027_externalIsolationLow : 26|1@1+ (1,0) [0|1] "" Vector__XXX
 SG_ SCM_a044_proximityRationality : 43|1@1+ (1,0) [0|1] "" Vector__XXX

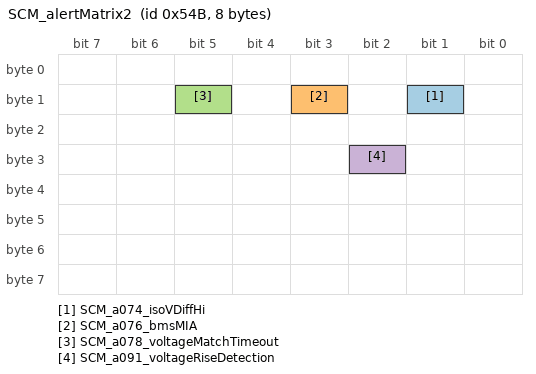
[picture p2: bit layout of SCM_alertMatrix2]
BO_ 1355 SCM_alertMatrix2: 8 SCM
 SG_ SCM_a074_isoVDiffHi : 9|1@1+ (1,0) [0|1] "" Vector__XXX
 SG_ SCM_a076_bmsMIA : 11|1@1+ (1,0) [0|1] "" Vector__XXX
 SG_ SCM_a078_voltageMatchTimeout : 13|1@1+ (1,0) [0|1] "" Vector__XXX
 SG_ SCM_a091_voltageRiseDetection : 26|1@1+ (1,0) [0|1] "" Vector__XXX

BO_ 1354 SCS_alertLog: 8 SCS
 SG_ SCS_alertID M : 0|15@1+ (1,0) [0|32767] "" Vector__XXX
 SG_ SCS_alertType : 15|1@1+ (1,0) [0|1] "" Vector__XXX
 SG_ SCS_a044_proximityV m44 : 16|16@1+ (0.0001,0) [0|6.5535] "V" Vector__XXX
 SG_ SCS_a074_voltageWithRo m74 : 16|12@1+ (0.146520152688,0) [0|600.000025257] "V" Vector__XXX
 SG_ SCS_a074_voltageWithoutRo m74 : 28|12@1+ (0.146520152688,0) [0|600.000025257] "V" Vector__XXX

BO_ 869 SCS_alertMatrix1: 8 SCS
 SG_ SCS_a001_hwDSPfault : 0|1@1+ (1,0) [0|1] "" Vector__XXX
 SG_ SCS_a002_hwIbatOC : 1|1@1+ (1,0) [0|1] "" Vector__XXX
 SG_ SCS_a003_hwCordOT : 2|1@1+ (1,0) [0|1] "" Vector__XXX
 SG_ SCS_a004_hwVbusOV : 3|1@1+ (1,0) [0|1] "" Vector__XXX
 SG_ SCS_a005_hwHVIL : 4|1@1+ (1,0) [0|1] "" Vector__XXX
 SG_ SCS_a006_hwWeld_V1 : 5|1@1+ (1,0) [0|1] "" Vector__XXX
 SG_ SCS_a007_hwWeld_V2 : 6|1@1+ (1,0) [0|1] "" Vector__XXX
 SG_ SCS_a008_hwIllegalCntrShoot : 7|1@1+ (1,0) [0|1] "" Vector__XXX
 SG_ SCS_a009_hwOpen_V1 : 8|1@1+ (1,0) [0|1] "" Vector__XXX
 SG_ SCS_a010_hwOpen_V2 : 9|1@1+ (1,0) [0|1] "" Vector__XXX
 SG_ SCS_a011_hwIllegalCntrCmdV1 : 10|1@1+ (1,0) [0|1] "" Vector__XXX
 SG_ SCS_a012_hwIllegalCntrCmdV2 : 11|1@1+ (1,0) [0|1] "" Vector__XXX
 SG_ SCS_a013_cordTempHiFoldBk : 12|1@1+ (1,0) [0|1] "" Vector__XXX
 SG_ SCS_a014_coolantTempHiFoldBk : 13|1@1+ (1,0) [0|1] "" Vector__XXX
 SG_ SCS_a015_cpldRationality : 14|1@1+ (1,0) [0|1] "" Vector__XXX
 SG_ SCS_a016_unusedHW16 : 15|1@1+ (1,0) [0|1] "" Vector__XXX
 SG_ SCS_a017_unusedHW17 : 16|1@1+ (1,0) [0|1] "" Vector__XXX
 SG_ SCS_a018_unusedHW18 : 17|1@1+ (1,0) [0|1] "" Vector__XXX
 SG_ SCS_a019_unusedHW19 : 18|1@1+ (1,0) [0|1] "" Vector__XXX
 SG_ SCS_a020_unusedHW20 : 19|1@1+ (1,0) [0|1] "" Vector__XXX
 SG_ SCS_a021_unusedHW21 : 20|1@1+ (1,0) [0|1] "" Vector__XXX
 SG_ SCS_a024_emergencyShutdown : 23|1@1+ (1,0) [0|1] "" Vector__XXX
 SG_ SCS_a025_internalIsolationFault : 24|1@1+ (1,0) [0|1] "" Vector__XXX
 SG_ SCS_a026_internalIsolationLow : 25|1@1+ (1,0) [0|1] "" Vector__XXX
 SG_ SCS_a027_externalIsolationLow : 26|1@1+ (1,0) [0|1] "" Vector__XXX
 SG_ SCS_a028_isolationRationality : 27|1@1+ (1,0) [0|1] "" Vector__XXX
 SG_ SCS_a029_VbatOV : 28|1@1+ (1,0) [0|1] "" Vector__XXX
 SG_ SCS_a030_VbusOV : 29|1@1+ (1,0) [0|1] "" Vector__XXX
 SG_ SCS_a031_IbatOC : 30|1@1+ (1,0) [0|1] "" Vector__XXX
 SG_ SCS_a032_VBatRationality : 31|1@1+ (1,0) [0|1] "" Vector__XXX
 SG_ SCS_a033_VBusRationality : 32|1@1+ (1,0) [0|1] "" Vector__XXX
 SG_ SCS_a034_IBatRationality : 33|1@1+ (1,0) [0|1] "" Vector__XXX
 SG_ SCS_a035_unexpectedVbusBehavior : 34|1@1+ (1,0) [0|1] "" Vector__XXX
 SG_ SCS_a036_internalContactorWelded : 35|1@1+ (1,0) [0|1] "" Vector__XXX
 SG_ SCS_a037_outputContactorWelded : 36|1@1+ (1,0) [0|1] "" Vector__XXX
 SG_ SCS_a038_contactorFailedOpen : 37|1@1+ (1,0) [0|1] "" Vector__XXX
 SG_ SCS_a039_ibatRegulation : 38|1@1+ (1,0) [0|1] "" Vector__XXX
 SG_ SCS_a040_plus12VOutOfRange : 39|1@1+ (1,0) [0|1] "" Vector__XXX
 SG_ SCS_a041_minus12VOutOfRange : 40|1@1+ (1,0) [0|1] "" Vector__XXX
 SG_ SCS_a042_pilotOutOfRange : 41|1@1+ (1,0) [0|1] "" Vector__XXX
 SG_ SCS_a043_pilotRationality : 42|1@1+ (1,0) [0|1] "" Vector__XXX
 SG_ SCS_a044_proximityRationality : 43|1@1+ (1,0) [0|1] "" Vector__XXX
 SG_ SCS_a045_pcbaOT : 44|1@1+ (1,0) [0|1] "" Vector__XXX
 SG_ SCS_a046_coolantOT : 45|1@1+ (1,0) [0|1] "" Vector__XXX
 SG_ SCS_a047_cordOT : 46|1@1+ (1,0) [0|1] "" Vector__XXX
 SG_ SCS_a048_ambientOT : 47|1@1+ (1,0) [0|1] "" Vector__XXX
 SG_ SCS_a049_pcbaTempRationality : 48|1@1+ (1,0) [0|1] "" Vector__XXX
 SG_ SCS_a050_coolantTempRationality : 49|1@1+ (1,0) [0|1] "" Vector__XXX
 SG_ SCS_a051_cordTempRationality : 50|1@1+ (1,0) [0|1] "" Vector__XXX
 SG_ SCS_a052_ambientTempRationality : 51|1@1+ (1,0) [0|1] "" Vector__XXX
 SG_ SCS_a053_unexpectedThermalBehavi : 52|1@1+ (1,0) [0|1] "" Vector__XXX
 SG_ SCS_a054_pumpRegulation : 53|1@1+ (1,0) [0|1] "" Vector__XXX
 SG_ SCS_a055_coolantLevelLow : 54|1@1+ (1,0) [0|1] "" Vector__XXX
 SG_ SCS_a056_stateTransitionDenied : 55|1@1+ (1,0) [0|1] "" Vector__XXX
 SG_ SCS_a057_watchdogReset : 56|1@1+ (1,0) [0|1] "" Vector__XXX
 SG_ SCS_a058_adcRef : 57|1@1+ (1,0) [0|1] "" Vector__XXX
 SG_ SCS_a059_memoryError : 58|1@1+ (1,0) [0|1] "" Vector__XXX
 SG_ SCS_a060_swHVIL : 59|1@1+ (1,0) [0|1] "" Vector__XXX
 SG_ SCS_a061_postOutOfService : 60|1@1+ (1,0) [0|1] "" Vector__XXX
 SG_ SCS_a062_unused : 61|1@1+ (1,0) [0|1] "" Vector__XXX
 SG_ SCS_a063_canRationality : 62|1@1+ (1,0) [0|1] "" Vector__XXX
 SG_ SCS_a064_vehicleCommandTimeout : 63|1@1+ (1,0) [0|1] "" Vector__XXX

BO_ 880 SCS_alertMatrix2: 8 SCS
 SG_ SCS_a065_vBatRationalityStage1 : 0|1@1+ (1,0) [0|1] "" Vector__XXX
 SG_ SCS_a066_vBatRationalityStage2 : 1|1@1+ (1,0) [0|1] "" Vector__XXX
 SG_ SCS_a067_vBatRationalityStage3 : 2|1@1+ (1,0) [0|1] "" Vector__XXX
 SG_ SCS_a068_vBatRationalityStage4 : 3|1@1+ (1,0) [0|1] "" Vector__XXX
 SG_ SCS_a069_vStageRationalityV1 : 4|1@1+ (1,0) [0|1] "" Vector__XXX
 SG_ SCS_a070_vStageRationalityV2 : 5|1@1+ (1,0) [0|1] "" Vector__XXX
 SG_ SCS_a071_chargerMIA : 6|1@1+ (1,0) [0|1] "" Vector__XXX
 SG_ SCS_a072_gtwMIA : 7|1@1+ (1,0) [0|1] "" Vector__XXX
 SG_ SCS_a073_lccMIA : 8|1@1+ (1,0) [0|1] "" Vector__XXX
 SG_ SCS_a074_isoVDiffHi : 9|1@1+ (1,0) [0|1] "" Vector__XXX
 SG_ SCS_a075_unused75 : 10|1@1+ (1,0) [0|1] "" Vector__XXX
 SG_ SCS_a076_bmsMIA : 11|1@1+ (1,0) [0|1] "" Vector__XXX
 SG_ SCS_a077_unexpectedVbatBehavior : 12|1@1+ (1,0) [0|1] "" Vector__XXX
 SG_ SCS_a078_voltageMatchTimeout : 13|1@1+ (1,0) [0|1] "" Vector__XXX
 SG_ SCS_a079_unexpectedVbat : 14|1@1+ (1,0) [0|1] "" Vector__XXX
 SG_ SCS_a080_lccFaulted : 15|1@1+ (1,0) [0|1] "" Vector__XXX
 SG_ SCS_a081_rmsInputVoltageHigh : 16|1@1+ (1,0) [0|1] "" Vector__XXX
 SG_ SCS_a082_VbatUV : 17|1@1+ (1,0) [0|1] "" Vector__XXX
 SG_ SCS_a083_chargeCurrentLimited : 18|1@1+ (1,0) [0|1] "" Vector__XXX
 SG_ SCS_a084_unused84 : 19|1@1+ (1,0) [0|1] "" Vector__XXX
 SG_ SCS_a085_unused85 : 20|1@1+ (1,0) [0|1] "" Vector__XXX
 SG_ SCS_a086_lccResetDetected : 21|1@1+ (1,0) [0|1] "" Vector__XXX
 SG_ SCS_a087_posCordTempRationality : 22|1@1+ (1,0) [0|1] "" Vector__XXX
 SG_ SCS_a088_negCordTempRationality : 23|1@1+ (1,0) [0|1] "" Vector__XXX
 SG_ SCS_a089_posCordOT : 24|1@1+ (1,0) [0|1] "" Vector__XXX
 SG_ SCS_a090_negCordOT : 25|1@1+ (1,0) [0|1] "" Vector__XXX
 SG_ SCS_a091_voltageRiseDetection : 26|1@1+ (1,0) [0|1] "" Vector__XXX
 SG_ SCS_a092_cabEnableDeasserted : 27|1@1+ (1,0) [0|1] "" Vector__XXX
 SG_ SCS_a093_unused93 : 28|1@1+ (1,0) [0|1] "" Vector__XXX
 SG_ SCS_a094_unused94 : 29|1@1+ (1,0) [0|1] "" Vector__XXX
 SG_ SCS_a095_unused95 : 30|1@1+ (1,0) [0|1] "" Vector__XXX
 SG_ SCS_a096_unused96 : 31|1@1+ (1,0) [0|1] "" Vector__XXX
 SG_ SCS_a097_unused97 : 32|1@1+ (1,0) [0|1] "" Vector__XXX
 SG_ SCS_a098_unused98 : 33|1@1+ (1,0) [0|1] "" Vector__XXX
 SG_ SCS_a099_unused99 : 34|1@1+ (1,0) [0|1] "" Vector__XXX
 SG_ SCS_a100_unused100 : 35|1@1+ (1,0) [0|1] "" Vector__XXX
 SG_ SCS_a101_unused101 : 36|1@1+ (1,0) [0|1] "" Vector__XXX
 SG_ SCS_a102_unused102 : 37|1@1+ (1,0) [0|1] "" Vector__XXX
 SG_ SCS_a103_unused103 : 38|1@1+ (1,0) [0|1] "" Vector__XXX
 SG_ SCS_a104_unused104 : 39|1@1+ (1,0) [0|1] "" Vector__XXX
 SG_ SCS_a105_unused105 : 40|1@1+ (1,0) [0|1] "" Vector__XXX
 SG_ SCS_a106_unused106 : 41|1@1+ (1,0) [0|1] "" Vector__XXX
 SG_ SCS_a107_unused107 : 42|1@1+ (1,0) [0|1] "" Vector__XXX
 SG_ SCS_a108_unused108 : 43|1@1+ (1,0) [0|1] "" Vector__XXX
 SG_ SCS_a109_unused109 : 44|1@1+ (1,0) [0|1] "" Vector__XXX
 SG_ SCS_a110_unused110 : 45|1@1+ (1,0) [0|1] "" Vector__XXX
 SG_ SCS_a111_unused111 : 46|1@1+ (1,0) [0|1] "" Vector__XXX
 SG_ SCS_a112_unused112 : 47|1@1+ (1,0) [0|1] "" Vector__XXX
 SG_ SCS_a113_unused113 : 48|1@1+ (1,0) [0|1] "" Vector__XXX
 SG_ SCS_a114_unused114 : 49|1@1+ (1,0) [0|1] "" Vector__XXX
 SG_ SCS_a115_unused115 : 50|1@1+ (1,0) [0|1] "" Vector__XXX
 SG_ SCS_a116_unused116 : 51|1@1+ (1,0) [0|1] "" Vector__XXX
 SG_ SCS_a117_unused117 : 52|1@1+ (1,0) [0|1] "" Vector__XXX
 SG_ SCS_a118_unused118 : 53|1@1+ (1,0) [0|1] "" Vector__XXX
 SG_ SCS_a119_unused119 : 54|1@1+ (1,0) [0|1] "" Vector__XXX
 SG_ SCS_a120_unused120 : 55|1@1+ (1,0) [0|1] "" Vector__XXX
 SG_ SCS_a121_unused121 : 56|1@1+ (1,0) [0|1] "" Vector__XXX
 SG_ SCS_a122_unused122 : 57|1@1+ (1,0) [0|1] "" Vector__XXX
 SG_ SCS_a123_unused123 : 58|1@1+ (1,0) [0|1] "" Vector__XXX
 SG_ SCS_a124_unused124 : 59|1@1+ (1,0) [0|1] "" Vector__XXX
 SG_ SCS_a125_unused125 : 60|1@1+ (1,0) [0|1] "" Vector__XXX
 SG_ SCS_a126_unused126 : 61|1@1+ (1,0) [0|1] "" Vector__XXX
 SG_ SCS_a127_unused127 : 62|1@1+ (1,0) [0|1] "" Vector__XXX
 SG_ SCS_a128_unused128 : 63|1@1+ (1,0) [0|1] "" Vector__XXX

BO_ 1531 SDCR_alertLog: 8 SDCR
 SG_ SDCR_alertID M : 0|6@1+ (1,0) [0|63] "" Vector__XXX
 SG_ SDCR_alertState : 15|1@1+ (1,0) [0|1] "" Vector__XXX
 SG_ SDCR_a001_pyroSenseV m1 : 16|8@1+ (0.02,0) [0|5.1] "V" Vector__XXX
 SG_ SDCR_a001_HVBackupSupplyV m1 : 24|8@1+ (0.15,0) [0|38.25] "V" Vector__XXX
 SG_ SDCR_a001_boostRailV m1 : 32|8@1+ (0.15,0) [0|38.25] "V" Vector__XXX
 SG_ SDCR_a001_expectedPyroV_max m1 : 40|8@1+ (0.02,0) [0|5.1] "V" Vector__XXX
 SG_ SDCR_a001_expectedPyroV_min m1 : 48|8@1+ (0.02,0) [0|5.1] "V" Vector__XXX
 SG_ SDCR_a001_fromState m1 : 56|3@1+ (1,0) [0|7] "" Vector__XXX
 SG_ SDCR_a004_HVBackupSupplyV m4 : 16|8@1+ (0.15,0) [0|38.25] "V" Vector__XXX
 SG_ SDCR_a004_boostRailV m4 : 24|8@1+ (0.15,0) [0|38.25] "V" Vector__XXX
 SG_ SDCR_a004_diPresent m4 : 32|1@1+ (1,0) [0|1] "" Vector__XXX
 SG_ SDCR_a004_pmRunningPin m4 : 33|1@1+ (1,0) [0|1] "" Vector__XXX
 SG_ SDCR_a006_pyroArmed m6 : 16|1@1+ (1,0) [0|1] "" Vector__XXX
 SG_ SDCR_a006_triggerReason_faultCur m6 : 17|1@1+ (1,0) [0|1] "" Vector__XXX
 SG_ SDCR_a006_triggerReason_hvBadAtS m6 : 18|1@1+ (1,0) [0|1] "" Vector__XXX
 SG_ SDCR_a006_triggerReason_highBack m6 : 19|1@1+ (1,0) [0|1] "" Vector__XXX
 SG_ SDCR_a006_faultCurrentsDetected m6 : 20|1@1+ (1,0) [0|1] "" Vector__XXX
 SG_ SDCR_a006_diUartMIA m6 : 21|1@1+ (1,0) [0|1] "" Vector__XXX
 SG_ SDCR_a006_pmRunningPin m6 : 22|1@1+ (1,0) [0|1] "" Vector__XXX
 SG_ SDCR_a006_hvPowerGood m6 : 23|1@1+ (1,0) [0|1] "" Vector__XXX
 SG_ SDCR_a006_hvbkupPGoodPin m6 : 24|1@1+ (1,0) [0|1] "" Vector__XXX
 SG_ SDCR_a006_hvPowerNotGoodQualifie m6 : 25|1@1+ (1,0) [0|1] "" Vector__XXX
 SG_ SDCR_a006_speedValid m6 : 26|1@1+ (1,0) [0|1] "" Vector__XXX
 SG_ SDCR_a006_speedFromVoltage m6 : 27|1@1+ (1,0) [0|1] "" Vector__XXX
 SG_ SDCR_a006_HVBackupSupplyV m6 : 28|7@1+ (0.3,0) [0|38.1] "V" Vector__XXX
 SG_ SDCR_a006_boostRailV m6 : 35|7@1+ (0.3,0) [0|38.1] "V" Vector__XXX
 SG_ SDCR_a006_maxAbsSpeed m6 : 42|12@1- (1,0) [-2048|2047] "Hz" Vector__XXX
 SG_ SDCR_a006_vBat m6 : 54|7@1+ (8,0) [0|1016] "V" Vector__XXX
 SG_ SDCR_a007_faultReason_faultCurre m7 : 16|1@1+ (1,0) [0|1] "" Vector__XXX
 SG_ SDCR_a007_faultReason_unmitigate m7 : 17|1@1+ (1,0) [0|1] "" Vector__XXX
 SG_ SDCR_a007_faultReason_propagatin m7 : 18|1@1+ (1,0) [0|1] "" Vector__XXX
 SG_ SDCR_a007_speedWasValid m7 : 19|1@1+ (1,0) [0|1] "" Vector__XXX
 SG_ SDCR_a007_imbalanceSeen m7 : 20|1@1+ (1,0) [0|1] "" Vector__XXX
 SG_ SDCR_a007_ucrSeen m7 : 21|1@1+ (1,0) [0|1] "" Vector__XXX
 SG_ SDCR_a007_phaseVoltagePresent m7 : 22|1@1+ (1,0) [0|1] "" Vector__XXX
 SG_ SDCR_a007_speedFromVoltage m7 : 23|1@1+ (1,0) [0|1] "" Vector__XXX
 SG_ SDCR_a007_transientHandling m7 : 24|2@1+ (1,0) [0|3] "" Vector__XXX
 SG_ SDCR_a007_maxAbsElcSpeed m7 : 26|9@1+ (4,0) [0|2044] "Hz" Vector__XXX
 SG_ SDCR_a007_avgIa m7 : 35|10@1- (4,0) [-2048|2044] "A" Vector__XXX
 SG_ SDCR_a007_avgIb m7 : 45|10@1- (4,0) [-2048|2044] "A" Vector__XXX
 SG_ SDCR_a007_maxAbsCurrents m7 : 55|9@1+ (4,0) [0|2044] "A" Vector__XXX
 SG_ SDCR_a008_dcLinkInfo m8 : 16|1@1+ (1,0) [0|1] "" Vector__XXX
 SG_ SDCR_a009_diVersion m9 : 16|2@1+ (1,0) [0|3] "" Vector__XXX
 SG_ SDCR_a009_sdcVersion m9 : 18|2@1+ (1,0) [0|3] "" Vector__XXX
 SG_ SDCR_a010_pgood m10 : 16|1@1+ (1,0) [0|1] "" Vector__XXX
 SG_ SDCR_a010_boostRailV m10 : 24|8@1+ (0.15,0) [0|38.25] "V" Vector__XXX
 SG_ SDCR_a010_Vref m10 : 32|8@1+ (0.02,0) [0|5.1] "V" Vector__XXX
 SG_ SDCR_a011_IaAvg m11 : 16|16@1- (0.1,0) [-3276.8|3276.7] "A" Vector__XXX
 SG_ SDCR_a011_IbAvg m11 : 32|16@1- (0.1,0) [-3276.8|3276.7] "A" Vector__XXX
 SG_ SDCR_a012_boostRailV m12 : 16|8@1+ (0.15,0) [0|38.25] "V" Vector__XXX
 SG_ SDCR_a012_HVBackupSupplyV m12 : 24|8@1+ (0.15,0) [0|38.25] "V" Vector__XXX
 SG_ SDCR_a012_vBat m12 : 32|10@1+ (2,0) [0|2046] "V" Vector__XXX
 SG_ SDCR_a012_vbkupGoodFdbk m12 : 42|1@1+ (1,0) [0|1] "" Vector__XXX
 SG_ SDCR_a013_boostRailV m13 : 16|8@1+ (0.15,0) [0|38.25] "V" Vector__XXX
 SG_ SDCR_a013_HVBackupSupplyV m13 : 24|8@1+ (0.15,0) [0|38.25] "V" Vector__XXX
 SG_ SDCR_a013_vBat m13 : 32|10@1+ (2,0) [0|2046] "V" Vector__XXX
 SG_ SDCR_a013_vbkupGoodFdbk m13 : 42|1@1+ (1,0) [0|1] "" Vector__XXX
 SG_ SDCR_a014_reason_vBusShortedLow m14 : 16|1@1+ (1,0) [0|1] "" Vector__XXX
 SG_ SDCR_a014_reason_vBusShortedHigh m14 : 17|1@1+ (1,0) [0|1] "" Vector__XXX
 SG_ SDCR_a014_boostRailV m14 : 24|8@1+ (0.15,0) [0|38.25] "V" Vector__XXX
 SG_ SDCR_a014_HVBackupSupplyV m14 : 32|8@1+ (0.15,0) [0|38.25] "V" Vector__XXX
 SG_ SDCR_a014_vBat m14 : 40|10@1+ (2,0) [0|2046] "V" Vector__XXX
 SG_ SDCR_a014_vbkupGoodFdbk m14 : 50|1@1+ (1,0) [0|1] "" Vector__XXX
 SG_ SDCR_a015_reason_vPhaseShortedLo m15 : 16|1@1+ (1,0) [0|1] "" Vector__XXX
 SG_ SDCR_a015_reason_vPhaseShortedHi m15 : 17|1@1+ (1,0) [0|1] "" Vector__XXX
 SG_ SDCR_a015_diSwitchingPin m15 : 18|1@1+ (1,0) [0|1] "" Vector__XXX
 SG_ SDCR_a015_vBat m15 : 19|10@1+ (2,0) [0|2046] "V" Vector__XXX
 SG_ SDCR_a015_va m15 : 29|10@1+ (2,0) [0|2046] "V" Vector__XXX
 SG_ SDCR_a015_vb m15 : 40|10@1+ (2,0) [0|2046] "V" Vector__XXX
 SG_ SDCR_a015_vc m15 : 50|10@1+ (2,0) [0|2046] "V" Vector__XXX
 SG_ SDCR_a017_expectedConfigWord m17 : 16|16@1+ (1,0) [0|65535] "" Vector__XXX
 SG_ SDCR_a017_receivedConfigWord m17 : 32|16@1+ (1,0) [0|65535] "" Vector__XXX
 SG_ SDCR_a018_pyroArmed m18 : 16|1@1+ (1,0) [0|1] "" Vector__XXX
 SG_ SDCR_a018_triggerReason_faultCur m18 : 17|1@1+ (1,0) [0|1] "" Vector__XXX
 SG_ SDCR_a018_triggerReason_hvBadAtS m18 : 18|1@1+ (1,0) [0|1] "" Vector__XXX
 SG_ SDCR_a018_triggerReason_highBack m18 : 19|1@1+ (1,0) [0|1] "" Vector__XXX
 SG_ SDCR_a018_faultCurrentsDetected m18 : 20|1@1+ (1,0) [0|1] "" Vector__XXX
 SG_ SDCR_a018_diUartMIA m18 : 21|1@1+ (1,0) [0|1] "" Vector__XXX
 SG_ SDCR_a018_pmRunningPin m18 : 22|1@1+ (1,0) [0|1] "" Vector__XXX
 SG_ SDCR_a018_hvPowerGood m18 : 23|1@1+ (1,0) [0|1] "" Vector__XXX
 SG_ SDCR_a018_hvbkupPGoodPin m18 : 24|1@1+ (1,0) [0|1] "" Vector__XXX
 SG_ SDCR_a018_hvPowerNotGoodQualifie m18 : 25|1@1+ (1,0) [0|1] "" Vector__XXX
 SG_ SDCR_a018_speedValid m18 : 26|1@1+ (1,0) [0|1] "" Vector__XXX
 SG_ SDCR_a018_speedFromVoltage m18 : 27|1@1+ (1,0) [0|1] "" Vector__XXX
 SG_ SDCR_a018_HVBackupSupplyV m18 : 28|7@1+ (0.3,0) [0|38.1] "V" Vector__XXX
 SG_ SDCR_a018_boostRailV m18 : 35|7@1+ (0.3,0) [0|38.1] "V" Vector__XXX
 SG_ SDCR_a018_maxAbsSpeed m18 : 42|12@1- (1,0) [-2048|2047] "Hz" Vector__XXX
 SG_ SDCR_a018_vBat m18 : 54|7@1+ (8,0) [0|1016] "V" Vector__XXX
 SG_ SDCR_a019_faultReason_faultCurre m19 : 16|1@1+ (1,0) [0|1] "" Vector__XXX
 SG_ SDCR_a019_faultReason_unmitigate m19 : 17|1@1+ (1,0) [0|1] "" Vector__XXX
 SG_ SDCR_a019_faultReason_propagatin m19 : 18|1@1+ (1,0) [0|1] "" Vector__XXX
 SG_ SDCR_a019_speedWasValid m19 : 19|1@1+ (1,0) [0|1] "" Vector__XXX
 SG_ SDCR_a019_imbalanceSeen m19 : 20|1@1+ (1,0) [0|1] "" Vector__XXX
 SG_ SDCR_a019_ucrSeen m19 : 21|1@1+ (1,0) [0|1] "" Vector__XXX
 SG_ SDCR_a019_phaseVoltagePresent m19 : 22|1@1+ (1,0) [0|1] "" Vector__XXX
 SG_ SDCR_a019_speedFromVoltage m19 : 23|1@1+ (1,0) [0|1] "" Vector__XXX
 SG_ SDCR_a019_transientHandling m19 : 24|2@1+ (1,0) [0|3] "" Vector__XXX
 SG_ SDCR_a019_maxAbsElcSpeed m19 : 26|9@1+ (4,0) [0|2044] "Hz" Vector__XXX
 SG_ SDCR_a019_avgIa m19 : 35|10@1- (4,0) [-2048|2044] "A" Vector__XXX
 SG_ SDCR_a019_avgIb m19 : 45|10@1- (4,0) [-2048|2044] "A" Vector__XXX
 SG_ SDCR_a019_maxAbsCurrents m19 : 55|9@1+ (4,0) [0|2044] "A" Vector__XXX
 SG_ SDCR_a020_errorCode m20 : 16|8@1+ (1,0) [0|255] "" Vector__XXX
 SG_ SDCR_a020_rxData0 m20 : 24|8@1+ (1,0) [0|255] "" Vector__XXX
 SG_ SDCR_a020_rxData1 m20 : 32|8@1+ (1,0) [0|255] "" Vector__XXX
 SG_ SDCR_a020_rxData2 m20 : 40|8@1+ (1,0) [0|255] "" Vector__XXX
 SG_ SDCR_a020_rxData3 m20 : 48|8@1+ (1,0) [0|255] "" Vector__XXX
 SG_ SDCR_a020_rxData4 m20 : 56|8@1+ (1,0) [0|255] "" Vector__XXX
 SG_ SDCR_a021_busBarTempC m21 : 16|8@1+ (1,-40) [-39|215] "DegC" Vector__XXX
 SG_ SDCR_a021_busBarTempA m21 : 24|8@1+ (1,-40) [-39|215] "DegC" Vector__XXX
 SG_ SDCR_a021_tempCVoltage m21 : 32|8@1+ (0.02,0) [0|5.1] "V" Vector__XXX
 SG_ SDCR_a021_tempAVoltage m21 : 40|8@1+ (0.02,0) [0|5.1] "V" Vector__XXX
 SG_ SDCR_a024_time m24 : 16|1@1+ (1,0) [0|1] "" Vector__XXX
 SG_ SDCR_a025_diSwitchingFromUart m25 : 16|1@1+ (1,0) [0|1] "" Vector__XXX
 SG_ SDCR_a025_diSwitchingPin m25 : 17|1@1+ (1,0) [0|1] "" Vector__XXX
 SG_ SDCR_a025_pmRunningPin m25 : 18|1@1+ (1,0) [0|1] "" Vector__XXX
 SG_ SDCR_a025_diUartMIA m25 : 19|1@1+ (1,0) [0|1] "" Vector__XXX
 SG_ SDCR_a025_HVBackupSupplyV m25 : 24|8@1+ (0.15,0) [0|38.25] "V" Vector__XXX
 SG_ SDCR_a025_boostRailV m25 : 32|8@1+ (0.15,0) [0|38.25] "V" Vector__XXX
 SG_ SDCR_a028_LVPowerState m28 : 16|1@1+ (1,0) [0|1] "" Vector__XXX
 SG_ SDCR_a029_uartCommsMissing m29 : 16|1@1+ (1,0) [0|1] "" Vector__XXX
 SG_ SDCR_a029_canCommsMissing m29 : 17|1@1+ (1,0) [0|1] "" Vector__XXX
 SG_ SDCR_a029_lvState m29 : 18|2@1+ (1,0) [0|3] "" Vector__XXX
 SG_ SDCR_a034_Ia m34 : 16|16@1- (0.1,0) [-3276.8|3276.7] "A" Vector__XXX
 SG_ SDCR_a034_Ib m34 : 32|16@1- (0.1,0) [-3276.8|3276.7] "A" Vector__XXX

BO_ 1467 SDCR_alertMatrix: 8 SDCR
 SG_ SDCR_matrixIndex M : 0|4@1+ (1,0) [0|15] "" Vector__XXX
 SG_ SDCR_a001_powerOnSelfTestFailed m0 : 4|1@1+ (1,0) [0|1] "" Vector__XXX
 SG_ SDCR_a002_diPstSkipped m0 : 5|1@1+ (1,0) [0|1] "" Vector__XXX
 SG_ SDCR_a003_diUartMIA m0 : 6|1@1+ (1,0) [0|1] "" Vector__XXX
 SG_ SDCR_a004_pmRunningFdbkIrrationa m0 : 7|1@1+ (1,0) [0|1] "" Vector__XXX
 SG_ SDCR_a005_motorSpeedIrrational m0 : 8|1@1+ (1,0) [0|1] "" Vector__XXX
 SG_ SDCR_a006_pyroTriggered m0 : 9|1@1+ (1,0) [0|1] "" Vector__XXX
 SG_ SDCR_a007_faultCurrentsDetected m0 : 10|1@1+ (1,0) [0|1] "" Vector__XXX
 SG_ SDCR_a008_hvlinkMIA m0 : 11|1@1+ (1,0) [0|1] "" Vector__XXX
 SG_ SDCR_a009_uartVersionMismatch m0 : 12|1@1+ (1,0) [0|1] "" Vector__XXX
 SG_ SDCR_a010_vrefIrrational m0 : 13|1@1+ (1,0) [0|1] "" Vector__XXX
 SG_ SDCR_a011_phaseCurrentOffset m0 : 14|1@1+ (1,0) [0|1] "" Vector__XXX
 SG_ SDCR_a012_vBoostSecIrrational m0 : 15|1@1+ (1,0) [0|1] "" Vector__XXX
 SG_ SDCR_a013_vBkupIrrational m0 : 16|1@1+ (1,0) [0|1] "" Vector__XXX
 SG_ SDCR_a014_vBusIrrational m0 : 17|1@1+ (1,0) [0|1] "" Vector__XXX
 SG_ SDCR_a015_phaseVIrrational m0 : 18|1@1+ (1,0) [0|1] "" Vector__XXX
 SG_ SDCR_a016_systemReset m0 : 19|1@1+ (1,0) [0|1] "" Vector__XXX
 SG_ SDCR_a017_adcSPIError m0 : 20|1@1+ (1,0) [0|1] "" Vector__XXX
 SG_ SDCR_a018_historicalPyroTrigger m0 : 21|1@1+ (1,0) [0|1] "" Vector__XXX
 SG_ SDCR_a019_historicalFaultCurrent m0 : 22|1@1+ (1,0) [0|1] "" Vector__XXX
 SG_ SDCR_a020_eepromSPIError m0 : 23|1@1+ (1,0) [0|1] "" Vector__XXX
 SG_ SDCR_a021_busBarTempIrrational m0 : 24|1@1+ (1,0) [0|1] "" Vector__XXX
 SG_ SDCR_a022_TaskInitError m0 : 25|1@1+ (1,0) [0|1] "" Vector__XXX
 SG_ SDCR_a023_ecuLogAvailable m0 : 26|1@1+ (1,0) [0|1] "" Vector__XXX
 SG_ SDCR_a024_gtwMIA m0 : 27|1@1+ (1,0) [0|1] "" Vector__XXX
 SG_ SDCR_a025_diSwitchingFdbkIrratio m0 : 28|1@1+ (1,0) [0|1] "" Vector__XXX
 SG_ SDCR_a026_faultCurrentMonitoring m0 : 29|1@1+ (1,0) [0|1] "" Vector__XXX
 SG_ SDCR_a027_diCanMIA m0 : 30|1@1+ (1,0) [0|1] "" Vector__XXX
 SG_ SDCR_a028_vcLVStateMIA m0 : 31|1@1+ (1,0) [0|1] "" Vector__XXX
 SG_ SDCR_a029_diMIA m0 : 32|1@1+ (1,0) [0|1] "" Vector__XXX
 SG_ SDCR_a030_placeholder30 m0 : 33|1@1+ (1,0) [0|1] "" Vector__XXX
 SG_ SDCR_a031_placeholder31 m0 : 34|1@1+ (1,0) [0|1] "" Vector__XXX
 SG_ SDCR_a032_placeholder32 m0 : 35|1@1+ (1,0) [0|1] "" Vector__XXX
 SG_ SDCR_a033_placeholder33 m0 : 36|1@1+ (1,0) [0|1] "" Vector__XXX
 SG_ SDCR_a034_phaseCurrentIrrational m0 : 37|1@1+ (1,0) [0|1] "" Vector__XXX

BO_ 1597 SDCR_info: 8 SDCR
 SG_ SDCR_infoIndex M : 0|8@1+ (1,0) [0|255] "" Vector__XXX
 SG_ SDCR_infoBuildType m10 : 13|3@1+ (1,0) [0|7] "" Vector__XXX
 SG_ SDCR_infoBuildConfigId m10 : 16|16@1+ (1,0) [0|65535] "" Vector__XXX
 SG_ SDCR_infoHardwareId m10 : 32|16@1+ (1,0) [0|65535] "" Vector__XXX
 SG_ SDCR_infoComponentId m10 : 55|16@0+ (1,0) [0|65535] "" Vector__XXX
 SG_ SDCR_infoPcbaId m11 : 8|8@1+ (1,0) [0|255] "" Vector__XXX
 SG_ SDCR_infoAssemblyId m11 : 16|8@1+ (1,0) [0|255] "" Vector__XXX
 SG_ SDCR_infoUsageId m11 : 31|16@0+ (1,0) [0|65535] "" Vector__XXX
 SG_ SDCR_infoSubUsageId m11 : 40|16@1+ (1,0) [0|65535] "" Vector__XXX
 SG_ SDCR_infoAppCrc m13 : 15|32@0+ (1,0) [0|4294967295] "" Vector__XXX
 SG_ SDCR_infoBootGitHash m18 : 8|56@1+ (1,0) [0|7.20575940379e+16] "" Vector__XXX

BO_ 1787 SDCR_udsResponse: 8 SDCR
 SG_ SDCR_udsResponseData : 7|64@0+ (1,0) [0|1.84467440737e+19] "" Vector__XXX

BO_TX_BU_ 1471 : RCU;
BO_TX_BU_ 998 : RCU;
BO_TX_BU_ 831 : RCU;
BO_TX_BU_ 1344 : SCCM;
BO_TX_BU_ 1359 : SCCM;
BO_TX_BU_ 816 : SCCM;
BO_TX_BU_ 585 : SCCM;
BO_TX_BU_ 553 : SCCM;
BO_TX_BU_ 297 : SCCM;
BO_TX_BU_ 1680 : SCCM;
BO_TX_BU_ 1356 : SCM;
BO_TX_BU_ 815 : SCM;
BO_TX_BU_ 1355 : SCM;
BO_TX_BU_ 1354 : SCS;
BO_TX_BU_ 869 : SCS;
BO_TX_BU_ 880 : SCS;
BO_TX_BU_ 1531 : SDCR;
BO_TX_BU_ 1467 : SDCR;
BO_TX_BU_ 1597 : SDCR;
BO_TX_BU_ 1787 : SDCR;
CM_ BO_ 1471 "RCU ECU message: alert log";
CM_ SG_ 1471 RCU_alertID "RCU ECU: alert ID";
CM_ SG_ 1471 RCU_alertState "RCU ECU: alert state";
CM_ SG_ 1471 RCU_a010_sensorPowerSupply "RCU ECU: a010 sensor power supply";
CM_ SG_ 1471 RCU_a010_sensorHardware "RCU ECU: a010 sensor hardware";
CM_ SG_ 1471 RCU_a010_sensorSignal "RCU ECU: a010 sensor signal";
CM_ SG_ 1471 RCU_a023_validityOnChassisBus "RCU ECU: a023 validity on chassis bus";
CM_ SG_ 1471 RCU_a023_validityOnPartyBus "RCU ECU: a023 validity on party bus";
CM_ SG_ 1471 RCU_a024_validityOnChassisBus "RCU ECU: a024 validity on chassis bus";
CM_ SG_ 1471 RCU_a024_validityOnPartyBus "RCU ECU: a024 validity on party bus";
CM_ SG_ 1471 RCU_a025_validityOnChassisBus "RCU ECU: a025 validity on chassis bus";
CM_ SG_ 1471 RCU_a025_validityOnPartyBus "RCU ECU: a025 validity on party bus";
CM_ SG_ 1471 RCU_a035_validityOnChassisBus "RCU ECU: a035 validity on chassis bus";
CM_ SG_ 1471 RCU_a035_validityOnPartyBus "RCU ECU: a035 validity on party bus";
CM_ SG_ 1471 RCU_a036_validityOnChassisBus "RCU ECU: a036 validity on chassis bus";
CM_ SG_ 1471 RCU_a036_validityOnPartyBus "RCU ECU: a036 validity on party bus";
CM_ BO_ 998 "RCU ECU message: alert matrix";
CM_ SG_ 998 RCU_matrixIndex "RCU ECU: matrix index";
CM_ SG_ 998 RCU_a001_valveDriverFault "RCU ECU: a001 valve driver fault";
CM_ SG_ 998 RCU_a002_solenoidValveFault "RCU ECU: a002 solenoid valve fault";
CM_ SG_ 998 RCU_a003_pumpMotorFault "RCU ECU: a003 pump motor fault";
CM_ SG_ 998 RCU_a004_supplyOvervoltage "RCU ECU: a004 supply overvoltage";
CM_ SG_ 998 RCU_a005_supplyUndervoltage "RCU ECU: a005 supply undervoltage";
CM_ SG_ 998 RCU_a006_wakeLineOpen "RCU ECU: a006 wake line open";
CM_ SG_ 998 RCU_a007_pressureSensorFault "RCU ECU: a007 pressure sensor fault";
CM_ SG_ 998 RCU_a008_pressureNotCalibrated "RCU ECU: a008 pressure not calibrated";
CM_ SG_ 998 RCU_a009_brakeFluidLow "RCU ECU: a009 brake fluid low";
CM_ SG_ 998 RCU_a010_pedalSensorFault "RCU ECU: a010 pedal sensor fault";
CM_ SG_ 998 RCU_a011_idbPedalTravelMismatch "RCU ECU: a011 idb pedal travel mismatch";
CM_ SG_ 998 RCU_a012_pedalSensorNotCal "RCU ECU: a012 pedal sensor not cal";
CM_ SG_ 998 RCU_a013_mcuGenericFault "RCU ECU: a013 mcu generic fault";
CM_ SG_ 998 RCU_a014_asicTempHigh "RCU ECU: a014 asic temp high";
CM_ SG_ 998 RCU_a015_fluidLeakDetected "RCU ECU: a015 fluid leak detected";
CM_ SG_ 998 RCU_a016_partyBusOff "RCU ECU: a016 party bus off";
CM_ SG_ 998 RCU_a017_chassisBusOff "RCU ECU: a017 chassis bus off";
CM_ SG_ 998 RCU_a018_DItorquePathFaulted "RCU ECU: a018 d itorque path faulted";
CM_ SG_ 998 RCU_a019_DItorquePathActive "RCU ECU: a019 d itorque path active";
CM_ SG_ 998 RCU_a020_BBstatusDLC "RCU ECU: a020 b bstatus DLC";
CM_ SG_ 998 RCU_a021_BBstatusChecksum "RCU ECU: a021 b bstatus checksum";
CM_ SG_ 998 RCU_a022_BBstatusCounter "RCU ECU: a022 b bstatus counter";
CM_ SG_ 998 RCU_a023_IDBstatusDLC "RCU ECU: a023 ID bstatus DLC";
CM_ SG_ 998 RCU_a024_IDBstatusChecksum "RCU ECU: a024 ID bstatus checksum";
CM_ SG_ 998 RCU_a025_IDBstatusCounter "RCU ECU: a025 ID bstatus counter";
CM_ SG_ 998 RCU_a026_DIchassisControlDLC "RCU ECU: a026 d ichassis control DLC";
CM_ SG_ 998 RCU_a027_DIchassisCtrlChecksum "RCU ECU: a027 d ichassis ctrl checksum";
CM_ SG_ 998 RCU_a028_DIchassisControlCounter "RCU ECU: a028 d ichassis control counter";
CM_ SG_ 998 RCU_a029_PMstate2DLC "RCU ECU: a029 p mstate2 DLC";
CM_ SG_ 998 RCU_a030_PMstate2Checksum "RCU ECU: a030 p mstate2 checksum";
CM_ SG_ 998 RCU_a031_PMstate2Counter "RCU ECU: a031 p mstate2 counter";
CM_ SG_ 998 RCU_a032_VCFRONTLVPowerStateDLC "RCU ECU: a032 VCFRONTLV power state DLC";
CM_ SG_ 998 RCU_a033_VCFRONTLVPowerStateChec "RCU ECU: a033 VCFRONTLV power state checksum";
CM_ SG_ 998 RCU_a034_VCFRONTLVPowerStateCoun "RCU ECU: a034 VCFRONTLV power state counter";
CM_ SG_ 998 RCU_a035_IDBpcpInvalid "RCU ECU: a035 ID bpcp invalid";
CM_ SG_ 998 RCU_a036_IDBpspInvalid "RCU ECU: a036 ID bpsp invalid";
CM_ SG_ 998 RCU_a037_IDBinputRodStrokeInvali "RCU ECU: a037 ID binput rod stroke invalid";
CM_ SG_ 998 RCU_a038_DIsystemStatusDLC "RCU ECU: a038 d isystem status DLC";
CM_ SG_ 998 RCU_a039_DIaccelPosInvalid "RCU ECU: a039 d iaccel pos invalid";
CM_ SG_ 998 RCU_a040_DIgearInvalid "RCU ECU: a040 d igear invalid";
CM_ SG_ 998 RCU_a041_DIsystemStatusCounter "RCU ECU: a041 d isystem status counter";
CM_ SG_ 998 RCU_a042_DIsystemStatusChecksum "RCU ECU: a042 d isystem status checksum";
CM_ SG_ 998 RCU_a043_VCFRONTiBoosterLvStateI "RCU ECU: a043 VCFRON ti booster lv state invalid";
CM_ SG_ 998 RCU_a044_VCFRONTsensorsMIA "RCU ECU: a044 VCFRON tsensors MIA";
CM_ SG_ 998 RCU_a045_VCFRONTtempInvalid "RCU ECU: a045 VCFRON ttemp invalid";
CM_ SG_ 998 RCU_a046_brakeFluidLevelSNA "RCU ECU: a046 brake fluid level SNA";
CM_ SG_ 998 RCU_a047_ESPwheelSpeedsDLC "RCU ECU: a047 ES pwheel speeds DLC";
CM_ SG_ 998 RCU_a048_ESPFrLWSSLInvalid "RCU ECU: a048 ESP fr LWSSL invalid";
CM_ SG_ 998 RCU_a049_ESPFrRWSSLInvalid "RCU ECU: a049 ESP fr RWSSL invalid";
CM_ SG_ 998 RCU_a050_ESPReLWSSLInvalid "RCU ECU: a050 ESP re LWSSL invalid";
CM_ SG_ 998 RCU_a051_ESPReRWSSLInvalid "RCU ECU: a051 ESP re RWSSL invalid";
CM_ SG_ 998 RCU_a052_ESPwheelSpeedsCounter "RCU ECU: a052 ES pwheel speeds counter";
CM_ SG_ 998 RCU_a053_ESPwheelSpeedsChecksum "RCU ECU: a053 ES pwheel speeds checksum";
CM_ SG_ 998 RCU_a054_IDBcircuitPressFaulted "RCU ECU: a054 ID bcircuit press faulted";
CM_ SG_ 998 RCU_a055_IDBsimulatorPressFaulte "RCU ECU: a055 ID bsimulator press faulted";
CM_ SG_ 998 RCU_a056_redundantControllerIsMa "RCU ECU: a056 redundant controller is master";
CM_ SG_ 998 RCU_a057_PMebrCmdStateInvalid "RCU ECU: a057 p mebr cmd state invalid";
CM_ SG_ 998 RCU_a058_DIbrakeTorqueCommandAnd "RCU ECU: a058 d ibrake torque command and flag mismatch";
CM_ BO_ 831 "RCU ECU message: info";
CM_ SG_ 831 RCU_infoIndex "RCU ECU: info index";
CM_ SG_ 831 RCU_infoPcbaID "RCU ECU: info pcba ID";
CM_ SG_ 831 RCU_infoAssemblyID "RCU ECU: info assembly ID";
CM_ SG_ 831 RCU_infoUsageID "RCU ECU: info usage ID";
CM_ SG_ 831 RCU_infoSubUsageID "RCU ECU: info sub usage ID";
CM_ BO_ 1344 "Steering column control module message: alert log";
CM_ SG_ 1344 SCCM_alertID "Steering column control module: alert ID";
CM_ SG_ 1344 SCCM_alertState "Steering column control module: alert state";
CM_ SG_ 1344 SCCM_a003_debouncePosition "Steering column control module: a003 debounce position";
CM_ SG_ 1344 SCCM_a003_rawPosition "Steering column control module: a003 raw position";
CM_ SG_ 1344 SCCM_a003_errorPosition "Steering column control module: a003 error position";
CM_ SG_ 1344 SCCM_a003_adcValue "Steering column control module: a003 adc value";
CM_ SG_ 1344 SCCM_a004_debouncePosition "Steering column control module: a004 debounce position";
CM_ SG_ 1344 SCCM_a004_rawPosition "Steering column control module: a004 raw position";
CM_ SG_ 1344 SCCM_a004_errorPosition "Steering column control module: a004 error position";
CM_ SG_ 1344 SCCM_a004_adcValue "Steering column control module: a004 adc value";
CM_ SG_ 1344 SCCM_a005_debouncePosition "Steering column control module: a005 debounce position";
CM_ SG_ 1344 SCCM_a005_rawPosition "Steering column control module: a005 raw position";
CM_ SG_ 1344 SCCM_a005_errorPosition "Steering column control module: a005 error position";
CM_ SG_ 1344 SCCM_a005_adcValue "Steering column control module: a005 adc value";
CM_ SG_ 1344 SCCM_a006_debouncePosition "Steering column control module: a006 debounce position";
CM_ SG_ 1344 SCCM_a006_rawPosition "Steering column control module: a006 raw position";
CM_ SG_ 1344 SCCM_a006_errorPosition "Steering column control module: a006 error position";
CM_ SG_ 1344 SCCM_a006_adcValue "Steering column control module: a006 adc value";
CM_ SG_ 1344 SCCM_a007_debouncePosition "Steering column control module: a007 debounce position";
CM_ SG_ 1344 SCCM_a007_rawPosition "Steering column control module: a007 raw position";
CM_ SG_ 1344 SCCM_a007_errorPosition "Steering column control module: a007 error position";
CM_ SG_ 1344 SCCM_a007_adcValue1 "Steering column control module: a007 adc value1";
CM_ SG_ 1344 SCCM_a007_adcValue2 "Steering column control module: a007 adc value2";
CM_ SG_ 1344 SCCM_a008_debouncePosition "Steering column control module: a008 debounce position";
CM_ SG_ 1344 SCCM_a008_rawPosition "Steering column control module: a008 raw position";
CM_ SG_ 1344 SCCM_a008_errorPosition "Steering column control module: a008 error position";
CM_ SG_ 1344 SCCM_a008_adcValue1 "Steering column control module: a008 adc value1";
CM_ SG_ 1344 SCCM_a008_adcValue2 "Steering column control module: a008 adc value2";
CM_ SG_ 1344 SCCM_a009_debouncePosition "Steering column control module: a009 debounce position";
CM_ SG_ 1344 SCCM_a009_rawPosition "Steering column control module: a009 raw position";
CM_ SG_ 1344 SCCM_a009_errorPosition "Steering column control module: a009 error position";
CM_ SG_ 1344 SCCM_a009_adcValue1 "Steering column control module: a009 adc value1";
CM_ SG_ 1344 SCCM_a009_adcValue2 "Steering column control module: a009 adc value2";
CM_ SG_ 1344 SCCM_a010_debouncePosition "Steering column control module: a010 debounce position";
CM_ SG_ 1344 SCCM_a010_rawPosition "Steering column control module: a010 raw position";
CM_ SG_ 1344 SCCM_a010_errorPosition "Steering column control module: a010 error position";
CM_ SG_ 1344 SCCM_a010_adcValue1 "Steering column control module: a010 adc value1";
CM_ SG_ 1344 SCCM_a010_adcValue2 "Steering column control module: a010 adc value2";
CM_ SG_ 1344 SCCM_a011_debouncePosition "Steering column control module: a011 debounce position";
CM_ SG_ 1344 SCCM_a011_rawPosition "Steering column control module: a011 raw position";
CM_ SG_ 1344 SCCM_a011_errorPosition "Steering column control module: a011 error position";
CM_ SG_ 1344 SCCM_a011_adcValue1 "Steering column control module: a011 adc value1";
CM_ SG_ 1344 SCCM_a011_adcValue2 "Steering column control module: a011 adc value2";
CM_ SG_ 1344 SCCM_a012_debouncePosition "Steering column control module: a012 debounce position";
CM_ SG_ 1344 SCCM_a012_rawPosition "Steering column control module: a012 raw position";
CM_ SG_ 1344 SCCM_a012_errorPosition "Steering column control module: a012 error position";
CM_ SG_ 1344 SCCM_a012_adcValue1 "Steering column control module: a012 adc value1";
CM_ SG_ 1344 SCCM_a012_adcValue2 "Steering column control module: a012 adc value2";
CM_ SG_ 1344 SCCM_a013_voltage "Steering column control module: a013 voltage";
CM_ SG_ 1344 SCCM_a014_voltage "Steering column control module: a014 voltage";
CM_ SG_ 1344 SCCM_a015_intMainIndex "Steering column control module: a015 int main index";
CM_ SG_ 1344 SCCM_a015_intSubIndex "Steering column control module: a015 int sub index";
CM_ SG_ 1344 SCCM_a015_intMemIndex "Steering column control module: a015 int mem index";
CM_ SG_ 1344 SCCM_a016_mainAdcTest "Steering column control module: a016 main adc test";
CM_ SG_ 1344 SCCM_a016_mainCpuTest "Steering column control module: a016 main cpu test";
CM_ SG_ 1344 SCCM_a016_wdtTest "Steering column control module: a016 wdt test";
CM_ SG_ 1344 SCCM_a016_subCpuTest "Steering column control module: a016 sub cpu test";
CM_ SG_ 1344 SCCM_a016_subAdcTest "Steering column control module: a016 sub adc test";
CM_ SG_ 1344 SCCM_a017_mainRamTest "Steering column control module: a017 main ram test";
CM_ SG_ 1344 SCCM_a017_mainRomTest "Steering column control module: a017 main rom test";
CM_ SG_ 1344 SCCM_a017_stackHardLimitTest "Steering column control module: a017 stack hard limit test";
CM_ SG_ 1344 SCCM_a017_mainDataFlashTest "Steering column control module: a017 main data flash test";
CM_ SG_ 1344 SCCM_a017_subRamTest "Steering column control module: a017 sub ram test";
CM_ SG_ 1344 SCCM_a017_subRomTest "Steering column control module: a017 sub rom test";
CM_ SG_ 1344 SCCM_a017_subStackHardLimitTest "Steering column control module: a017 sub stack hard limit test";
CM_ SG_ 1344 SCCM_a017_svError "Steering column control module: a017 sv error";
CM_ SG_ 1344 SCCM_a018_internalSASState "Steering column control module: a018 internal SAS state";
CM_ SG_ 1344 SCCM_a019_internalSASState "Steering column control module: a019 internal SAS state";
CM_ SG_ 1344 SCCM_a020_internalSASState "Steering column control module: a020 internal SAS state";
CM_ SG_ 1344 SCCM_a021_adcValue1 "Steering column control module: a021 adc value1";
CM_ SG_ 1344 SCCM_a021_adcValue2 "Steering column control module: a021 adc value2";
CM_ SG_ 1344 SCCM_a021_adcValue3 "Steering column control module: a021 adc value3";
CM_ SG_ 1344 SCCM_a021_adcValue4 "Steering column control module: a021 adc value4";
CM_ SG_ 1344 SCCM_a021_adcValue5 "Steering column control module: a021 adc value5";
CM_ SG_ 1344 SCCM_a021_adcValue6 "Steering column control module: a021 adc value6";
CM_ SG_ 1344 SCCM_a022_adcValue1 "Steering column control module: a022 adc value1";
CM_ SG_ 1344 SCCM_a022_adcValue2 "Steering column control module: a022 adc value2";
CM_ SG_ 1344 SCCM_a022_adcValue3 "Steering column control module: a022 adc value3";
CM_ SG_ 1344 SCCM_a022_adcValue4 "Steering column control module: a022 adc value4";
CM_ SG_ 1344 SCCM_a022_adcValue5 "Steering column control module: a022 adc value5";
CM_ SG_ 1344 SCCM_a022_adcValue6 "Steering column control module: a022 adc value6";
CM_ SG_ 1344 SCCM_a023_adcValue1 "Steering column control module: a023 adc value1";
CM_ SG_ 1344 SCCM_a023_adcValue2 "Steering column control module: a023 adc value2";
CM_ SG_ 1344 SCCM_a023_adcValue3 "Steering column control module: a023 adc value3";
CM_ SG_ 1344 SCCM_a023_adcValue4 "Steering column control module: a023 adc value4";
CM_ SG_ 1344 SCCM_a023_adcValue5 "Steering column control module: a023 adc value5";
CM_ SG_ 1344 SCCM_a023_adcValue6 "Steering column control module: a023 adc value6";
CM_ SG_ 1344 SCCM_a024_adcValue1 "Steering column control module: a024 adc value1";
CM_ SG_ 1344 SCCM_a024_adcValue2 "Steering column control module: a024 adc value2";
CM_ SG_ 1344 SCCM_a024_adcValue3 "Steering column control module: a024 adc value3";
CM_ SG_ 1344 SCCM_a024_adcValue4 "Steering column control module: a024 adc value4";
CM_ SG_ 1344 SCCM_a024_adcValue5 "Steering column control module: a024 adc value5";
CM_ SG_ 1344 SCCM_a024_adcValue6 "Steering column control module: a024 adc value6";
CM_ SG_ 1344 SCCM_a025_taskState "Steering column control module: a025 task state";
CM_ SG_ 1344 SCCM_a026_debouncePosition "Steering column control module: a026 debounce position";
CM_ SG_ 1344 SCCM_a026_rawPosition "Steering column control module: a026 raw position";
CM_ SG_ 1344 SCCM_a026_errorPosition "Steering column control module: a026 error position";
CM_ SG_ 1344 SCCM_a026_adcValue1 "Steering column control module: a026 adc value1";
CM_ SG_ 1344 SCCM_a026_adcValue2 "Steering column control module: a026 adc value2";
CM_ SG_ 1344 SCCM_a027_debouncePosition "Steering column control module: a027 debounce position";
CM_ SG_ 1344 SCCM_a027_rawPosition "Steering column control module: a027 raw position";
CM_ SG_ 1344 SCCM_a027_errorPosition "Steering column control module: a027 error position";
CM_ SG_ 1344 SCCM_a027_adcValue1 "Steering column control module: a027 adc value1";
CM_ SG_ 1344 SCCM_a027_adcValue2 "Steering column control module: a027 adc value2";
CM_ SG_ 1344 SCCM_a028_debouncePosition "Steering column control module: a028 debounce position";
CM_ SG_ 1344 SCCM_a028_rawPosition "Steering column control module: a028 raw position";
CM_ SG_ 1344 SCCM_a028_errorPosition "Steering column control module: a028 error position";
CM_ SG_ 1344 SCCM_a028_adcValue1 "Steering column control module: a028 adc value1";
CM_ SG_ 1344 SCCM_a028_adcValue2 "Steering column control module: a028 adc value2";
CM_ SG_ 1344 SCCM_a029_debouncePosition "Steering column control module: a029 debounce position";
CM_ SG_ 1344 SCCM_a029_rawPosition "Steering column control module: a029 raw position";
CM_ SG_ 1344 SCCM_a029_errorPosition "Steering column control module: a029 error position";
CM_ SG_ 1344 SCCM_a029_adcValue1 "Steering column control module: a029 adc value1";
CM_ SG_ 1344 SCCM_a029_adcValue2 "Steering column control module: a029 adc value2";
CM_ SG_ 1344 SCCM_a061_voltage "Steering column control module: a061 voltage";
CM_ SG_ 1344 SCCM_a062_voltage "Steering column control module: a062 voltage";
CM_ SG_ 1344 SCCM_a063_UntrimmedAngle "Steering column control module: a063 untrimmed angle; raw 16383 = signal not available (SNA)";
CM_ SG_ 1344 SCCM_a064_Speed "Steering column control module: a064 speed; raw 16383 = signal not available (SNA)";
CM_ SG_ 1344 SCCM_a065_M1RawAngleCurrent "Steering column control module: a065 M1 raw angle current";
CM_ SG_ 1344 SCCM_a065_M1RawAnglePrevious "Steering column control module: a065 M1 raw angle previous";
CM_ SG_ 1344 SCCM_a065_M2RawAngleCurrent "Steering column control module: a065 M2 raw angle current";
CM_ SG_ 1344 SCCM_a065_M2RawAnglePrevious "Steering column control module: a065 M2 raw angle previous";
CM_ SG_ 1344 SCCM_a066_M1RawAngleCurrent "Steering column control module: a066 M1 raw angle current";
CM_ SG_ 1344 SCCM_a066_M1RawAnglePrevious "Steering column control module: a066 M1 raw angle previous";
CM_ SG_ 1344 SCCM_a066_M2RawAngleCurrent "Steering column control module: a066 M2 raw angle current";
CM_ SG_ 1344 SCCM_a066_M2RawAnglePrevious "Steering column control module: a066 M2 raw angle previous";
CM_ SG_ 1344 SCCM_a071_M1LogicBISTFailed "Steering column control module: a071 M1 logic BIST failed";
CM_ SG_ 1344 SCCM_a071_M1PowerOnReset "Steering column control module: a071 M1 power on reset";
CM_ SG_ 1344 SCCM_a071_M1UnderVoltage "Steering column control module: a071 M1 under voltage";
CM_ SG_ 1344 SCCM_a071_M1OverVoltage "Steering column control module: a071 M1 over voltage";
CM_ SG_ 1344 SCCM_a071_M1DualBitError "Steering column control module: a071 M1 dual bit error";
CM_ SG_ 1344 SCCM_a071_M1RefVoltageOutOfRange "Steering column control module: a071 M1 ref voltage out of range";
CM_ SG_ 1344 SCCM_a071_M1RegisterParityError "Steering column control module: a071 M1 register parity error";
CM_ SG_ 1344 SCCM_a071_M1OscillatorFreqError "Steering column control module: a071 M1 oscillator freq error";
CM_ SG_ 1344 SCCM_a071_M1SignalOutOfRange "Steering column control module: a071 M1 signal out of range";
CM_ SG_ 1344 SCCM_a071_M1TempOutOfRange "Steering column control module: a071 M1 temp out of range";
CM_ SG_ 1344 SCCM_a071_M1AngleMismatch "Steering column control module: a071 M1 angle mismatch";
CM_ SG_ 1344 SCCM_a071_M1RadiusOutOfRange "Steering column control module: a071 M1 radius out of range";
CM_ SG_ 1344 SCCM_a071_M2LogicBISTFailed "Steering column control module: a071 M2 logic BIST failed";
CM_ SG_ 1344 SCCM_a071_M2PowerOnReset "Steering column control module: a071 M2 power on reset";
CM_ SG_ 1344 SCCM_a071_M2UnderVoltage "Steering column control module: a071 M2 under voltage";
CM_ SG_ 1344 SCCM_a071_M2OverVoltage "Steering column control module: a071 M2 over voltage";
CM_ SG_ 1344 SCCM_a071_M2DualBitError "Steering column control module: a071 M2 dual bit error";
CM_ SG_ 1344 SCCM_a071_M2RefVoltageOutOfRange "Steering column control module: a071 M2 ref voltage out of range";
CM_ SG_ 1344 SCCM_a071_M2RegisterParityError "Steering column control module: a071 M2 register parity error";
CM_ SG_ 1344 SCCM_a071_M2OscillatorFreqError "Steering column control module: a071 M2 oscillator freq error";
CM_ SG_ 1344 SCCM_a071_M2SignalOutOfRange "Steering column control module: a071 M2 signal out of range";
CM_ SG_ 1344 SCCM_a071_M2TempOutOfRange "Steering column control module: a071 M2 temp out of range";
CM_ SG_ 1344 SCCM_a071_M2AngleMismatch "Steering column control module: a071 M2 angle mismatch";
CM_ SG_ 1344 SCCM_a071_M2RadiusOutOfRange "Steering column control module: a071 M2 radius out of range";
CM_ SG_ 1344 SCCM_a071_M1ProcessLogicFailed "Steering column control module: a071 M1 process logic failed";
CM_ SG_ 1344 SCCM_a071_M2ProcessLogicFailed "Steering column control module: a071 M2 process logic failed";
CM_ SG_ 1344 SCCM_a071_TSOSCHighFreqError "Steering column control module: a071 TSOSC high freq error";
CM_ SG_ 1344 SCCM_a071_TSOSCLowFreqError "Steering column control module: a071 TSOSC low freq error";
CM_ SG_ 1344 SCCM_a071_TSOPRStatMismatch "Steering column control module: a071 TSOPR stat mismatch";
CM_ SG_ 1344 SCCM_a071_TSCRCStatError "Steering column control module: a071 TSCRC stat error";
CM_ SG_ 1344 SCCM_a071_TSFrameStatError "Steering column control module: a071 TS frame stat error";
CM_ SG_ 1344 SCCM_a071_TSOverVoltage "Steering column control module: a071 TS over voltage";
CM_ SG_ 1344 SCCM_a071_TSUnderVoltage "Steering column control module: a071 TS under voltage";
CM_ SG_ 1344 SCCM_a071_TSPowerOnReset "Steering column control module: a071 TS power on reset";
CM_ SG_ 1344 SCCM_a071_TSLDOStatError "Steering column control module: a071 TSLDO stat error";
CM_ SG_ 1344 SCCM_a071_TSTempOutOfRange "Steering column control module: a071 TS temp out of range";
CM_ SG_ 1344 SCCM_a071_TSAlertIntegrityCheck "Steering column control module: a071 TS alert integrity check";
CM_ SG_ 1344 SCCM_a071_TSMemoryCRCError "Steering column control module: a071 TS memory CRC error";
CM_ SG_ 1344 SCCM_a071_TSAFECheck "Steering column control module: a071 TSAFE check";
CM_ SG_ 1344 SCCM_a071_TSADCCheck "Steering column control module: a071 TSADC check";
CM_ SG_ 1344 SCCM_a071_TSConfigFault "Steering column control module: a071 TS config fault";
CM_ SG_ 1344 SCCM_a072_M1CRCCalculated "Steering column control module: a072 M1 CRC calculated";
CM_ SG_ 1344 SCCM_a072_M1CRCReceived "Steering column control module: a072 M1 CRC received";
CM_ SG_ 1344 SCCM_a072_M2CRCCalculated "Steering column control module: a072 M2 CRC calculated";
CM_ SG_ 1344 SCCM_a072_M2CRCReceived "Steering column control module: a072 M2 CRC received";
CM_ SG_ 1344 SCCM_a072_TSCRCCalculated "Steering column control module: a072 TSCRC calculated";
CM_ SG_ 1344 SCCM_a072_TSCRCReceived "Steering column control module: a072 TSCRC received";
CM_ SG_ 1344 SCCM_a075_ClockOutOfRange "Steering column control module: a075 clock out of range";
CM_ SG_ 1344 SCCM_a075_ExtWatchdogTestFailed "Steering column control module: a075 ext watchdog test failed";
CM_ SG_ 1344 SCCM_a075_InterruptMonitorError "Steering column control module: a075 interrupt monitor error";
CM_ SG_ 1344 SCCM_a076_RAMTestFailed "Steering column control module: a076 RAM test failed";
CM_ SG_ 1344 SCCM_a076_NVMTestFailed "Steering column control module: a076 NVM test failed";
CM_ SG_ 1344 SCCM_a077_M1ExpectAngleCurrent "Steering column control module: a077 M1 expect angle current";
CM_ SG_ 1344 SCCM_a077_M1ExpectAnglePrevious "Steering column control module: a077 M1 expect angle previous";
CM_ SG_ 1344 SCCM_a077_M1AngleCurrent "Steering column control module: a077 M1 angle current";
CM_ SG_ 1344 SCCM_a077_M1AnglePrevious "Steering column control module: a077 M1 angle previous";
CM_ SG_ 1344 SCCM_a079_ChipTemperature "Steering column control module: a079 chip temperature";
CM_ SG_ 1344 SCCM_a081_StartupTestStatus "Steering column control module: a081 startup test status";
CM_ SG_ 1344 SCCM_a081_sCheckTestFailedData "Steering column control module: a081 s check test failed data";
CM_ SG_ 1344 SCCM_a081_sBootTestFailedData "Steering column control module: a081 s boot test failed data";
CM_ SG_ 1344 SCCM_a081_BISTTestFailedData "Steering column control module: a081 BIST test failed data";
CM_ SG_ 1344 SCCM_a082_RuntimeTestStatus "Steering column control module: a082 runtime test status";
CM_ SG_ 1344 SCCM_a082_sCheckTestFailedData "Steering column control module: a082 s check test failed data";
CM_ SG_ 1344 SCCM_a082_ArrayIntegrFailedData "Steering column control module: a082 array integr failed data";
CM_ SG_ 1344 SCCM_a121_turnIndicatorStalkAngl "Steering column control module: a121 turn indicator stalk angle";
CM_ SG_ 1344 SCCM_a121_turnIndicatorHallAngle "Steering column control module: a121 turn indicator hall angle";
CM_ SG_ 1344 SCCM_a122_turnIndicatorSpeed "Steering column control module: a122 turn indicator speed";
CM_ SG_ 1344 SCCM_a123_turnIndicatorStalkAngl "Steering column control module: a123 turn indicator stalk angle";
CM_ SG_ 1344 SCCM_a124_turnIndicatorStalkAngl "Steering column control module: a124 turn indicator stalk angle";
CM_ SG_ 1344 SCCM_a125_turnIndicatorHallAngle "Steering column control module: a125 turn indicator hall angle";
CM_ SG_ 1344 SCCM_a125_turnIndicatorVectorAng "Steering column control module: a125 turn indicator vector angle";
CM_ SG_ 1344 SCCM_a126_turnIndicatorXVectorOu "Steering column control module: a126 turn indicator x vector out of range";
CM_ SG_ 1344 SCCM_a126_turnIndicatorYVectorOu "Steering column control module: a126 turn indicator y vector out of range";
CM_ SG_ 1344 SCCM_a126_turnIndicatorZVectorOu "Steering column control module: a126 turn indicator z vector out of range";
CM_ SG_ 1344 SCCM_a126_turnIndicatorResu_0001 "Steering column control module: a126 turn indicator resultant out of range";
CM_ SG_ 1344 SCCM_a126_turnIndicatorXMagnitud "Steering column control module: a126 turn indicator x magnitude";
CM_ SG_ 1344 SCCM_a126_turnIndicatorYMagnitud "Steering column control module: a126 turn indicator y magnitude";
CM_ SG_ 1344 SCCM_a126_turnIndicatorZMagnitud "Steering column control module: a126 turn indicator z magnitude";
CM_ SG_ 1344 SCCM_a126_turnIndicatorResultant "Steering column control module: a126 turn indicator resultant magnitude";
CM_ BO_ 1359 "Steering column control module message: alert matrix";
CM_ SG_ 1359 SCCM_matrixIndex "Steering column control module: matrix index";
CM_ SG_ 1359 SCCM_a001_CANBusOff "Steering column control module: a001 CAN bus off";
CM_ SG_ 1359 SCCM_a002_CANTOut "Steering column control module: a002 CANT out";
CM_ SG_ 1359 SCCM_a003_highBeamOpen "Steering column control module: a003 high beam open";
CM_ SG_ 1359 SCCM_a004_highBeamShortToGND "Steering column control module: a004 high beam short to GND";
CM_ SG_ 1359 SCCM_a005_tipWipeOpen "Steering column control module: a005 tip wipe open";
CM_ SG_ 1359 SCCM_a006_tipWipeShortToGND "Steering column control module: a006 tip wipe short to GND";
CM_ SG_ 1359 SCCM_a007_turnIndComInfo "Steering column control module: a007 turn ind com info";
CM_ SG_ 1359 SCCM_a008_turnIndInvalidTrans "Steering column control module: a008 turn ind invalid trans";
CM_ SG_ 1359 SCCM_a009_turnIndOpen "Steering column control module: a009 turn ind open";
CM_ SG_ 1359 SCCM_a010_turnIndShortToGnd "Steering column control module: a010 turn ind short to gnd";
CM_ SG_ 1359 SCCM_a011_turnIndHWErr "Steering column control module: a011 turn ind HW err";
CM_ SG_ 1359 SCCM_a012_turnGenErr "Steering column control module: a012 turn gen err";
CM_ SG_ 1359 SCCM_a013_voltageHigh "Steering column control module: a013 voltage high";
CM_ SG_ 1359 SCCM_a014_voltageLow "Steering column control module: a014 voltage low";
CM_ SG_ 1359 SCCM_a015_softwareError "Steering column control module: a015 software error";
CM_ SG_ 1359 SCCM_a016_hardwareError "Steering column control module: a016 hardware error";
CM_ SG_ 1359 SCCM_a017_memoryError "Steering column control module: a017 memory error";
CM_ SG_ 1359 SCCM_a018_angleSpeedOutOfRange "Steering column control module: a018 angle speed out of range";
CM_ SG_ 1359 SCCM_a019_angleOutOfRange "Steering column control module: a019 angle out of range";
CM_ SG_ 1359 SCCM_a020_angleInternalError "Steering column control module: a020 angle internal error";
CM_ SG_ 1359 SCCM_a021_gearStalkSignalInvalid "Steering column control module: a021 gear stalk signal invalid";
CM_ SG_ 1359 SCCM_a022_gearStalkOpenCircuit "Steering column control module: a022 gear stalk open circuit";
CM_ SG_ 1359 SCCM_a023_gearStalkShortCircuit "Steering column control module: a023 gear stalk short circuit";
CM_ SG_ 1359 SCCM_a024_gearStalkGenErr "Steering column control module: a024 gear stalk gen err";
CM_ SG_ 1359 SCCM_a025_runTimeError "Steering column control module: a025 run time error";
CM_ SG_ 1359 SCCM_a026_parkButtonInvalidSigna "Steering column control module: a026 park button invalid signal";
CM_ SG_ 1359 SCCM_a027_parkButtonOpenCircuit "Steering column control module: a027 park button open circuit";
CM_ SG_ 1359 SCCM_a028_parkButtonShortToGroun "Steering column control module: a028 park button short to ground";
CM_ SG_ 1359 SCCM_a029_parkButtonMalfunction "Steering column control module: a029 park button malfunction";
CM_ SG_ 1359 SCCM_a061_voltageHigh_2 "Steering column control module: a061 voltage high 2";
CM_ SG_ 1359 SCCM_a062_voltageLow_2 "Steering column control module: a062 voltage low 2";
CM_ SG_ 1359 SCCM_a063_angleOutOfRange_2 "Steering column control module: a063 angle out of range 2";
CM_ SG_ 1359 SCCM_a064_angleSpeedOutOfRange_2 "Steering column control module: a064 angle speed out of range 2";
CM_ SG_ 1359 SCCM_a065_angleNotPlausible "Steering column control module: a065 angle not plausible";
CM_ SG_ 1359 SCCM_a066_angleSpeedNotPlausible "Steering column control module: a066 angle speed not plausible";
CM_ SG_ 1359 SCCM_a067_CANBusOff_2 "Steering column control module: a067 CAN bus off 2";
CM_ SG_ 1359 SCCM_a068_CANLVPowerState_LOC "Steering column control module: a068 CANLV power state LOC";
CM_ SG_ 1359 SCCM_a069_calibrationMismatch "Steering column control module: a069 calibration mismatch";
CM_ SG_ 1359 SCCM_a070_angleTrimMismatch "Steering column control module: a070 angle trim mismatch";
CM_ SG_ 1359 SCCM_a071_angleHallSensorError "Steering column control module: a071 angle hall sensor error";
CM_ SG_ 1359 SCCM_a072_spiBitErrors "Steering column control module: a072 spi bit errors";
CM_ SG_ 1359 SCCM_a073_watchdogReset "Steering column control module: a073 watchdog reset";
CM_ SG_ 1359 SCCM_a074_PLLLossOfLock "Steering column control module: a074 PLL loss of lock";
CM_ SG_ 1359 SCCM_a075_hardwareError_2 "Steering column control module: a075 hardware error 2";
CM_ SG_ 1359 SCCM_a076_memoryError_2 "Steering column control module: a076 memory error 2";
CM_ SG_ 1359 SCCM_a077_gearAngleNotPlausible "Steering column control module: a077 gear angle not plausible";
CM_ SG_ 1359 SCCM_a078_ADCCalibrationError "Steering column control module: a078 ADC calibration error";
CM_ SG_ 1359 SCCM_a079_chipTempOutOfRange "Steering column control module: a079 chip temp out of range";
CM_ SG_ 1359 SCCM_a080_ADCSelfTestFailed "Steering column control module: a080 ADC self test failed";
CM_ SG_ 1359 SCCM_a081_startupTestFailed "Steering column control module: a081 startup test failed";
CM_ SG_ 1359 SCCM_a082_runtimeTestFailed "Steering column control module: a082 runtime test failed";
CM_ SG_ 1359 SCCM_a121_turnIndicatorAngleInva "Steering column control module: a121 turn indicator angle invalid";
CM_ SG_ 1359 SCCM_a122_turnIndicatorSpeedInva "Steering column control module: a122 turn indicator speed invalid";
CM_ SG_ 1359 SCCM_a123_turnIndicatorStuckActi "Steering column control module: a123 turn indicator stuck active";
CM_ SG_ 1359 SCCM_a124_turnIndicatorIdleInval "Steering column control module: a124 turn indicator idle invalid";
CM_ SG_ 1359 SCCM_a125_turnIndicatorHallAngle "Steering column control module: a125 turn indicator hall angle mismatch";
CM_ SG_ 1359 SCCM_a126_turnIndicatorHallMagOu "Steering column control module: a126 turn indicator hall mag out of range";
CM_ BO_ 816 "Steering column control module message: info";
CM_ SG_ 816 SCCM_infoIndex "Steering column control module: info index";
CM_ SG_ 816 SCCM_infoBuildType "Steering column control module: info build type";
CM_ SG_ 816 SCCM_infoBuildConfigId "Steering column control module: info build config id";
CM_ SG_ 816 SCCM_infoHardwareId "Steering column control module: info hardware id";
CM_ SG_ 816 SCCM_infoComponentId "Steering column control module: info component id";
CM_ SG_ 816 SCCM_infoPcbaId "Steering column control module: info pcba id";
CM_ SG_ 816 SCCM_infoAssemblyId "Steering column control module: info assembly id";
CM_ SG_ 816 SCCM_infoUsageId "Steering column control module: info usage id";
CM_ SG_ 816 SCCM_infoSubUsageId "Steering column control module: info sub usage id";
CM_ SG_ 816 SCCM_infoPlatformType "Steering column control module: info platform type";
CM_ SG_ 816 SCCM_infoAppCrc "Steering column control module: info app crc";
CM_ SG_ 816 SCCM_infoBootSvnRev "Steering column control module: info boot svn rev";
CM_ SG_ 816 SCCM_infoBootSvnUrlHash "Steering column control module: info boot svn url hash";
CM_ SG_ 816 SCCM_infoSubcomponent1Version "Steering column control module: info subcomponent1 version";
CM_ SG_ 816 SCCM_infoAppSvnHash "Steering column control module: info app svn hash";
CM_ SG_ 816 SCCM_infoBootSvnHash "Steering column control module: info boot svn hash";
CM_ SG_ 816 SCCM_infoUdsProtoVersion "Steering column control module: info uds proto version";
CM_ SG_ 816 SCCM_infoBootCrc "Steering column control module: info boot crc";
CM_ BO_ 585 "Steering column control module message: left stalk";
CM_ SG_ 585 SCCM_leftStalkCrc "Steering column control module: left stalk crc";
CM_ SG_ 585 SCCM_leftStalkCounter "Steering column control module: left stalk counter";
CM_ SG_ 585 SCCM_highBeamStalkStatus "Active state of high beam push/pull stalk position; raw 3 = signal not available (SNA)";
CM_ SG_ 585 SCCM_washWipeButtonStatus "Active state of wash/wipe button on the turn signal stalk; raw 3 = signal not available (SNA)";
CM_ SG_ 585 SCCM_turnIndicatorStalkStatus "Active state of turn indicator stalk position; raw 9 = signal not available (SNA)";
CM_ SG_ 585 SCCM_turnIndicatorStalkAngle "Measured angle of the turn signal stalk; raw 4095 = signal not available (SNA)";
CM_ BO_ 553 "Steering column control module message: right stalk";
CM_ SG_ 553 SCCM_rightStalkCrc "Steering column control module: right stalk crc";
CM_ SG_ 553 SCCM_rightStalkCounter "Steering column control module: right stalk counter";
CM_ SG_ 553 SCCM_rightStalkStatus "Active state of drive stalk position, does not indicate active drive gear; raw 6 = signal not available (SNA)";
CM_ SG_ 553 SCCM_rightStalkReserved1 "Steering column control module: right stalk reserved1";
CM_ SG_ 553 SCCM_parkButtonStatus "Active state of park button on the drive stalk; raw 3 = signal not available (SNA)";
CM_ SG_ 553 SCCM_rightStalkReserved2 "Steering column control module: right stalk reserved2";
CM_ BO_ 297 "Steering column control module message: steering angle sensor";
CM_ SG_ 297 SCCM_steeringAngleCrc "Steering column control module: steering angle crc";
CM_ SG_ 297 SCCM_steeringAngleCounter "Message counter";
CM_ SG_ 297 SCCM_supplierID "Steering column control module: supplier ID";
CM_ SG_ 297 SCCM_steeringAngleSensorStatus "Reports steering angle sensor status and validity based on bootup checks";
CM_ SG_ 297 SCCM_steeringAngle "Measured ASAS sensor angle; raw 16383 = signal not available (SNA)";
CM_ SG_ 297 SCCM_steeringAngleValidity "Transitions to VALID when rotation of over 4 deg has occurred; raw 3 = signal not available (SNA)";
CM_ SG_ 297 SCCM_steeringAngleSpeed "Speed of steering angle rotation";
CM_ SG_ 297 SCCM_steeringAngleSensorReservd1 "Steering column control module: steering angle sensor reservd1";
CM_ SG_ 297 SCCM_steeringAngleSensorReservd2 "Steering column control module: steering angle sensor reservd2";
CM_ SG_ 297 SCCM_steeringAngleSensorReservd3 "Steering column control module: steering angle sensor reservd3";
CM_ BO_ 1680 "Steering column control module message: uds response";
CM_ SG_ 1680 SCCM_functionalResponseData_0 "Steering column control module: functional response data 0";
CM_ SG_ 1680 SCCM_functionalResponseData_1 "Steering column control module: functional response data 1";
CM_ SG_ 1680 SCCM_functionalResponseData_2 "Steering column control module: functional response data 2";
CM_ SG_ 1680 SCCM_functionalResponseData_3 "Steering column control module: functional response data 3";
CM_ SG_ 1680 SCCM_functionalResponseData_4 "Steering column control module: functional response data 4";
CM_ SG_ 1680 SCCM_functionalResponseData_5 "Steering column control module: functional response data 5";
CM_ SG_ 1680 SCCM_functionalResponseData_6 "Steering column control module: functional response data 6";
CM_ SG_ 1680 SCCM_functionalResponseData_7 "Steering column control module: functional response data 7";
CM_ BO_ 1356 "SCM ECU message: alert log";
CM_ SG_ 1356 SCM_alertID "SCM ECU: alert ID";
CM_ SG_ 1356 SCM_alertType "SCM ECU: alert type";
CM_ SG_ 1356 SCM_a074_voltageWithRo "SCM ECU: a074 voltage with ro";
CM_ SG_ 1356 SCM_a074_voltageWithoutRo "SCM ECU: a074 voltage without ro";
CM_ BO_ 815 "SCM ECU message: alert matrix1";
CM_ SG_ 815 SCM_a027_externalIsolationLow "SCM ECU: a027 external isolation low";
CM_ SG_ 815 SCM_a044_proximityRationality "SCM ECU: a044 proximity rationality";
CM_ BO_ 1355 "SCM ECU message: alert matrix2";
CM_ SG_ 1355 SCM_a074_isoVDiffHi "SCM ECU: a074 iso v diff hi";
CM_ SG_ 1355 SCM_a076_bmsMIA "SCM ECU: a076 bms MIA";
CM_ SG_ 1355 SCM_a078_voltageMatchTimeout "SCM ECU: a078 voltage match timeout";
CM_ SG_ 1355 SCM_a091_voltageRiseDetection "SCM ECU: a091 voltage rise detection";
CM_ BO_ 1354 "SCS ECU message: alert log";
CM_ SG_ 1354 SCS_alertID "SCS ECU: alert ID";
CM_ SG_ 1354 SCS_alertType "SCS ECU: alert type";
CM_ SG_ 1354 SCS_a044_proximityV "SCS ECU: a044 proximity v";
CM_ SG_ 1354 SCS_a074_voltageWithRo "SCS ECU: a074 voltage with ro";
CM_ SG_ 1354 SCS_a074_voltageWithoutRo "SCS ECU: a074 voltage without ro";
CM_ BO_ 869 "SCS ECU message: alert matrix1";
CM_ SG_ 869 SCS_a001_hwDSPfault "SCS ECU: a001 hw DS pfault";
CM_ SG_ 869 SCS_a002_hwIbatOC "SCS ECU: a002 hw ibat OC";
CM_ SG_ 869 SCS_a003_hwCordOT "SCS ECU: a003 hw cord OT";
CM_ SG_ 869 SCS_a004_hwVbusOV "SCS ECU: a004 hw vbus OV";
CM_ SG_ 869 SCS_a005_hwHVIL "SCS ECU: a005 hw HVIL";
CM_ SG_ 869 SCS_a006_hwWeld_V1 "SCS ECU: a006 hw weld V1";
CM_ SG_ 869 SCS_a007_hwWeld_V2 "SCS ECU: a007 hw weld V2";
CM_ SG_ 869 SCS_a008_hwIllegalCntrShoot "SCS ECU: a008 hw illegal cntr shoot";
CM_ SG_ 869 SCS_a009_hwOpen_V1 "SCS ECU: a009 hw open V1";
CM_ SG_ 869 SCS_a010_hwOpen_V2 "SCS ECU: a010 hw open V2";
CM_ SG_ 869 SCS_a011_hwIllegalCntrCmdV1 "SCS ECU: a011 hw illegal cntr cmd V1";
CM_ SG_ 869 SCS_a012_hwIllegalCntrCmdV2 "SCS ECU: a012 hw illegal cntr cmd V2";
CM_ SG_ 869 SCS_a013_cordTempHiFoldBk "SCS ECU: a013 cord temp hi fold bk";
CM_ SG_ 869 SCS_a014_coolantTempHiFoldBk "SCS ECU: a014 coolant temp hi fold bk";
CM_ SG_ 869 SCS_a015_cpldRationality "SCS ECU: a015 cpld rationality";
CM_ SG_ 869 SCS_a016_unusedHW16 "SCS ECU: a016 unused HW16";
CM_ SG_ 869 SCS_a017_unusedHW17 "SCS ECU: a017 unused HW17";
CM_ SG_ 869 SCS_a018_unusedHW18 "SCS ECU: a018 unused HW18";
CM_ SG_ 869 SCS_a019_unusedHW19 "SCS ECU: a019 unused HW19";
CM_ SG_ 869 SCS_a020_unusedHW20 "SCS ECU: a020 unused HW20";
CM_ SG_ 869 SCS_a021_unusedHW21 "SCS ECU: a021 unused HW21";
CM_ SG_ 869 SCS_a024_emergencyShutdown "SCS ECU: a024 emergency shutdown";
CM_ SG_ 869 SCS_a025_internalIsolationFault "SCS ECU: a025 internal isolation fault";
CM_ SG_ 869 SCS_a026_internalIsolationLow "SCS ECU: a026 internal isolation low";
CM_ SG_ 869 SCS_a027_externalIsolationLow "SCS ECU: a027 external isolation low";
CM_ SG_ 869 SCS_a028_isolationRationality "SCS ECU: a028 isolation rationality";
CM_ SG_ 869 SCS_a029_VbatOV "SCS ECU: a029 vbat OV";
CM_ SG_ 869 SCS_a030_VbusOV "SCS ECU: a030 vbus OV";
CM_ SG_ 869 SCS_a031_IbatOC "SCS ECU: a031 ibat OC";
CM_ SG_ 869 SCS_a032_VBatRationality "SCS ECU: a032 v bat rationality";
CM_ SG_ 869 SCS_a033_VBusRationality "SCS ECU: a033 v bus rationality";
CM_ SG_ 869 SCS_a034_IBatRationality "SCS ECU: a034 i bat rationality";
CM_ SG_ 869 SCS_a035_unexpectedVbusBehavior "SCS ECU: a035 unexpected vbus behavior";
CM_ SG_ 869 SCS_a036_internalContactorWelded "SCS ECU: a036 internal contactor welded";
CM_ SG_ 869 SCS_a037_outputContactorWelded "SCS ECU: a037 output contactor welded";
CM_ SG_ 869 SCS_a038_contactorFailedOpen "SCS ECU: a038 contactor failed open";
CM_ SG_ 869 SCS_a039_ibatRegulation "SCS ECU: a039 ibat regulation";
CM_ SG_ 869 SCS_a040_plus12VOutOfRange "SCS ECU: a040 plus12 v out of range";
CM_ SG_ 869 SCS_a041_minus12VOutOfRange "SCS ECU: a041 minus12 v out of range";
CM_ SG_ 869 SCS_a042_pilotOutOfRange "SCS ECU: a042 pilot out of range";
CM_ SG_ 869 SCS_a043_pilotRationality "SCS ECU: a043 pilot rationality";
CM_ SG_ 869 SCS_a044_proximityRationality "SCS ECU: a044 proximity rationality";
CM_ SG_ 869 SCS_a045_pcbaOT "SCS ECU: a045 pcba OT";
CM_ SG_ 869 SCS_a046_coolantOT "SCS ECU: a046 coolant OT";
CM_ SG_ 869 SCS_a047_cordOT "SCS ECU: a047 cord OT";
CM_ SG_ 869 SCS_a048_ambientOT "SCS ECU: a048 ambient OT";
CM_ SG_ 869 SCS_a049_pcbaTempRationality "SCS ECU: a049 pcba temp rationality";
CM_ SG_ 869 SCS_a050_coolantTempRationality "SCS ECU: a050 coolant temp rationality";
CM_ SG_ 869 SCS_a051_cordTempRationality "SCS ECU: a051 cord temp rationality";
CM_ SG_ 869 SCS_a052_ambientTempRationality "SCS ECU: a052 ambient temp rationality";
CM_ SG_ 869 SCS_a053_unexpectedThermalBehavi "SCS ECU: a053 unexpected thermal behavi";
CM_ SG_ 869 SCS_a054_pumpRegulation "SCS ECU: a054 pump regulation";
CM_ SG_ 869 SCS_a055_coolantLevelLow "SCS ECU: a055 coolant level low";
CM_ SG_ 869 SCS_a056_stateTransitionDenied "SCS ECU: a056 state transition denied";
CM_ SG_ 869 SCS_a057_watchdogReset "SCS ECU: a057 watchdog reset";
CM_ SG_ 869 SCS_a058_adcRef "SCS ECU: a058 adc ref";
CM_ SG_ 869 SCS_a059_memoryError "SCS ECU: a059 memory error";
CM_ SG_ 869 SCS_a060_swHVIL "SCS ECU: a060 sw HVIL";
CM_ SG_ 869 SCS_a061_postOutOfService "SCS ECU: a061 post out of service";
CM_ SG_ 869 SCS_a062_unused "SCS ECU: a062 unused";
CM_ SG_ 869 SCS_a063_canRationality "SCS ECU: a063 can rationality";
CM_ SG_ 869 SCS_a064_vehicleCommandTimeout "SCS ECU: a064 vehicle command timeout";
CM_ BO_ 880 "SCS ECU message: alert matrix2";
CM_ SG_ 880 SCS_a065_vBatRationalityStage1 "SCS ECU: a065 v bat rationality stage1";
CM_ SG_ 880 SCS_a066_vBatRationalityStage2 "SCS ECU: a066 v bat rationality stage2";
CM_ SG_ 880 SCS_a067_vBatRationalityStage3 "SCS ECU: a067 v bat rationality stage3";
CM_ SG_ 880 SCS_a068_vBatRationalityStage4 "SCS ECU: a068 v bat rationality stage4";
CM_ SG_ 880 SCS_a069_vStageRationalityV1 "SCS ECU: a069 v stage rationality V1";
CM_ SG_ 880 SCS_a070_vStageRationalityV2 "SCS ECU: a070 v stage rationality V2";
CM_ SG_ 880 SCS_a071_chargerMIA "SCS ECU: a071 charger MIA";
CM_ SG_ 880 SCS_a072_gtwMIA "SCS ECU: a072 gtw MIA";
CM_ SG_ 880 SCS_a073_lccMIA "SCS ECU: a073 lcc MIA";
CM_ SG_ 880 SCS_a074_isoVDiffHi "SCS ECU: a074 iso v diff hi";
CM_ SG_ 880 SCS_a075_unused75 "SCS ECU: a075 unused75";
CM_ SG_ 880 SCS_a076_bmsMIA "SCS ECU: a076 bms MIA";
CM_ SG_ 880 SCS_a077_unexpectedVbatBehavior "SCS ECU: a077 unexpected vbat behavior";
CM_ SG_ 880 SCS_a078_voltageMatchTimeout "SCS ECU: a078 voltage match timeout";
CM_ SG_ 880 SCS_a079_unexpectedVbat "SCS ECU: a079 unexpected vbat";
CM_ SG_ 880 SCS_a080_lccFaulted "SCS ECU: a080 lcc faulted";
CM_ SG_ 880 SCS_a081_rmsInputVoltageHigh "SCS ECU: a081 rms input voltage high";
CM_ SG_ 880 SCS_a082_VbatUV "SCS ECU: a082 vbat UV";
CM_ SG_ 880 SCS_a083_chargeCurrentLimited "SCS ECU: a083 charge current limited";
CM_ SG_ 880 SCS_a084_unused84 "SCS ECU: a084 unused84";
CM_ SG_ 880 SCS_a085_unused85 "SCS ECU: a085 unused85";
CM_ SG_ 880 SCS_a086_lccResetDetected "SCS ECU: a086 lcc reset detected";
CM_ SG_ 880 SCS_a087_posCordTempRationality "SCS ECU: a087 pos cord temp rationality";
CM_ SG_ 880 SCS_a088_negCordTempRationality "SCS ECU: a088 neg cord temp rationality";
CM_ SG_ 880 SCS_a089_posCordOT "SCS ECU: a089 pos cord OT";
CM_ SG_ 880 SCS_a090_negCordOT "SCS ECU: a090 neg cord OT";
CM_ SG_ 880 SCS_a091_voltageRiseDetection "SCS ECU: a091 voltage rise detection";
CM_ SG_ 880 SCS_a092_cabEnableDeasserted "SCS ECU: a092 cab enable deasserted";
CM_ SG_ 880 SCS_a093_unused93 "SCS ECU: a093 unused93";
CM_ SG_ 880 SCS_a094_unused94 "SCS ECU: a094 unused94";
CM_ SG_ 880 SCS_a095_unused95 "SCS ECU: a095 unused95";
CM_ SG_ 880 SCS_a096_unused96 "SCS ECU: a096 unused96";
CM_ SG_ 880 SCS_a097_unused97 "SCS ECU: a097 unused97";
CM_ SG_ 880 SCS_a098_unused98 "SCS ECU: a098 unused98";
CM_ SG_ 880 SCS_a099_unused99 "SCS ECU: a099 unused99";
CM_ SG_ 880 SCS_a100_unused100 "SCS ECU: a100 unused100";
CM_ SG_ 880 SCS_a101_unused101 "SCS ECU: a101 unused101";
CM_ SG_ 880 SCS_a102_unused102 "SCS ECU: a102 unused102";
CM_ SG_ 880 SCS_a103_unused103 "SCS ECU: a103 unused103";
CM_ SG_ 880 SCS_a104_unused104 "SCS ECU: a104 unused104";
CM_ SG_ 880 SCS_a105_unused105 "SCS ECU: a105 unused105";
CM_ SG_ 880 SCS_a106_unused106 "SCS ECU: a106 unused106";
CM_ SG_ 880 SCS_a107_unused107 "SCS ECU: a107 unused107";
CM_ SG_ 880 SCS_a108_unused108 "SCS ECU: a108 unused108";
CM_ SG_ 880 SCS_a109_unused109 "SCS ECU: a109 unused109";
CM_ SG_ 880 SCS_a110_unused110 "SCS ECU: a110 unused110";
CM_ SG_ 880 SCS_a111_unused111 "SCS ECU: a111 unused111";
CM_ SG_ 880 SCS_a112_unused112 "SCS ECU: a112 unused112";
CM_ SG_ 880 SCS_a113_unused113 "SCS ECU: a113 unused113";
CM_ SG_ 880 SCS_a114_unused114 "SCS ECU: a114 unused114";
CM_ SG_ 880 SCS_a115_unused115 "SCS ECU: a115 unused115";
CM_ SG_ 880 SCS_a116_unused116 "SCS ECU: a116 unused116";
CM_ SG_ 880 SCS_a117_unused117 "SCS ECU: a117 unused117";
CM_ SG_ 880 SCS_a118_unused118 "SCS ECU: a118 unused118";
CM_ SG_ 880 SCS_a119_unused119 "SCS ECU: a119 unused119";
CM_ SG_ 880 SCS_a120_unused120 "SCS ECU: a120 unused120";
CM_ SG_ 880 SCS_a121_unused121 "SCS ECU: a121 unused121";
CM_ SG_ 880 SCS_a122_unused122 "SCS ECU: a122 unused122";
CM_ SG_ 880 SCS_a123_unused123 "SCS ECU: a123 unused123";
CM_ SG_ 880 SCS_a124_unused124 "SCS ECU: a124 unused124";
CM_ SG_ 880 SCS_a125_unused125 "SCS ECU: a125 unused125";
CM_ SG_ 880 SCS_a126_unused126 "SCS ECU: a126 unused126";
CM_ SG_ 880 SCS_a127_unused127 "SCS ECU: a127 unused127";
CM_ SG_ 880 SCS_a128_unused128 "SCS ECU: a128 unused128";
CM_ BO_ 1531 "SDCR ECU message: alert log";
CM_ SG_ 1531 SDCR_alertID "SDCR ECU: alert ID";
CM_ SG_ 1531 SDCR_alertState "SDCR ECU: alert state";
CM_ SG_ 1531 SDCR_a001_pyroSenseV "SDCR ECU: a001 pyro sense v";
CM_ SG_ 1531 SDCR_a001_HVBackupSupplyV "SDCR ECU: a001 HV backup supply v";
CM_ SG_ 1531 SDCR_a001_boostRailV "SDCR ECU: a001 boost rail v";
CM_ SG_ 1531 SDCR_a001_expectedPyroV_max "SDCR ECU: a001 expected pyro v max";
CM_ SG_ 1531 SDCR_a001_expectedPyroV_min "SDCR ECU: a001 expected pyro v min";
CM_ SG_ 1531 SDCR_a001_fromState "SDCR ECU: a001 from state";
CM_ SG_ 1531 SDCR_a004_HVBackupSupplyV "SDCR ECU: a004 HV backup supply v";
CM_ SG_ 1531 SDCR_a004_boostRailV "SDCR ECU: a004 boost rail v";
CM_ SG_ 1531 SDCR_a004_diPresent "SDCR ECU: a004 di present";
CM_ SG_ 1531 SDCR_a004_pmRunningPin "SDCR ECU: a004 pm running pin";
CM_ SG_ 1531 SDCR_a006_pyroArmed "SDCR ECU: a006 pyro armed";
CM_ SG_ 1531 SDCR_a006_triggerReason_faultCur "SDCR ECU: a006 trigger reason fault currents";
CM_ SG_ 1531 SDCR_a006_triggerReason_hvBadAtS "SDCR ECU: a006 trigger reason hv bad at speed";
CM_ SG_ 1531 SDCR_a006_triggerReason_highBack "SDCR ECU: a006 trigger reason high back EMF";
CM_ SG_ 1531 SDCR_a006_faultCurrentsDetected "SDCR ECU: a006 fault currents detected";
CM_ SG_ 1531 SDCR_a006_diUartMIA "SDCR ECU: a006 di uart MIA";
CM_ SG_ 1531 SDCR_a006_pmRunningPin "SDCR ECU: a006 pm running pin";
CM_ SG_ 1531 SDCR_a006_hvPowerGood "SDCR ECU: a006 hv power good";
CM_ SG_ 1531 SDCR_a006_hvbkupPGoodPin "SDCR ECU: a006 hvbkup p good pin";
CM_ SG_ 1531 SDCR_a006_hvPowerNotGoodQualifie "SDCR ECU: a006 hv power not good qualified";
CM_ SG_ 1531 SDCR_a006_speedValid "SDCR ECU: a006 speed valid";
CM_ SG_ 1531 SDCR_a006_speedFromVoltage "SDCR ECU: a006 speed from voltage";
CM_ SG_ 1531 SDCR_a006_HVBackupSupplyV "SDCR ECU: a006 HV backup supply v";
CM_ SG_ 1531 SDCR_a006_boostRailV "SDCR ECU: a006 boost rail v";
CM_ SG_ 1531 SDCR_a006_maxAbsSpeed "SDCR ECU: a006 max abs speed";
CM_ SG_ 1531 SDCR_a006_vBat "SDCR ECU: a006 v bat";
CM_ SG_ 1531 SDCR_a007_faultReason_faultCurre "SDCR ECU: a007 fault reason fault currents at speed";
CM_ SG_ 1531 SDCR_a007_faultReason_unmitigate "SDCR ECU: a007 fault reason unmitigated UCR";
CM_ SG_ 1531 SDCR_a007_faultReason_propagatin "SDCR ECU: a007 fault reason propagating3 PS";
CM_ SG_ 1531 SDCR_a007_speedWasValid "SDCR ECU: a007 speed was valid";
CM_ SG_ 1531 SDCR_a007_imbalanceSeen "SDCR ECU: a007 imbalance seen";
CM_ SG_ 1531 SDCR_a007_ucrSeen "SDCR ECU: a007 ucr seen";
CM_ SG_ 1531 SDCR_a007_phaseVoltagePresent "SDCR ECU: a007 phase voltage present";
CM_ SG_ 1531 SDCR_a007_speedFromVoltage "SDCR ECU: a007 speed from voltage";
CM_ SG_ 1531 SDCR_a007_transientHandling "SDCR ECU: a007 transient handling";
CM_ SG_ 1531 SDCR_a007_maxAbsElcSpeed "SDCR ECU: a007 max abs elc speed";
CM_ SG_ 1531 SDCR_a007_avgIa "SDCR ECU: a007 avg ia";
CM_ SG_ 1531 SDCR_a007_avgIb "SDCR ECU: a007 avg ib";
CM_ SG_ 1531 SDCR_a007_maxAbsCurrents "SDCR ECU: a007 max abs currents";
CM_ SG_ 1531 SDCR_a008_dcLinkInfo "SDCR ECU: a008 dc link info";
CM_ SG_ 1531 SDCR_a009_diVersion "SDCR ECU: a009 di version";
CM_ SG_ 1531 SDCR_a009_sdcVersion "SDCR ECU: a009 sdc version";
CM_ SG_ 1531 SDCR_a010_pgood "SDCR ECU: a010 pgood";
CM_ SG_ 1531 SDCR_a010_boostRailV "SDCR ECU: a010 boost rail v";
CM_ SG_ 1531 SDCR_a010_Vref "SDCR ECU: a010 vref";
CM_ SG_ 1531 SDCR_a011_IaAvg "SDCR ECU: a011 ia avg";
CM_ SG_ 1531 SDCR_a011_IbAvg "SDCR ECU: a011 ib avg";
CM_ SG_ 1531 SDCR_a012_boostRailV "SDCR ECU: a012 boost rail v";
CM_ SG_ 1531 SDCR_a012_HVBackupSupplyV "SDCR ECU: a012 HV backup supply v";
CM_ SG_ 1531 SDCR_a012_vBat "SDCR ECU: a012 v bat";
CM_ SG_ 1531 SDCR_a012_vbkupGoodFdbk "SDCR ECU: a012 vbkup good fdbk";
CM_ SG_ 1531 SDCR_a013_boostRailV "SDCR ECU: a013 boost rail v";
CM_ SG_ 1531 SDCR_a013_HVBackupSupplyV "SDCR ECU: a013 HV backup supply v";
CM_ SG_ 1531 SDCR_a013_vBat "SDCR ECU: a013 v bat";
CM_ SG_ 1531 SDCR_a013_vbkupGoodFdbk "SDCR ECU: a013 vbkup good fdbk";
CM_ SG_ 1531 SDCR_a014_reason_vBusShortedLow "SDCR ECU: a014 reason v bus shorted low";
CM_ SG_ 1531 SDCR_a014_reason_vBusShortedHigh "SDCR ECU: a014 reason v bus shorted high";
CM_ SG_ 1531 SDCR_a014_boostRailV "SDCR ECU: a014 boost rail v";
CM_ SG_ 1531 SDCR_a014_HVBackupSupplyV "SDCR ECU: a014 HV backup supply v";
CM_ SG_ 1531 SDCR_a014_vBat "SDCR ECU: a014 v bat";
CM_ SG_ 1531 SDCR_a014_vbkupGoodFdbk "SDCR ECU: a014 vbkup good fdbk";
CM_ SG_ 1531 SDCR_a015_reason_vPhaseShortedLo "SDCR ECU: a015 reason v phase shorted low";
CM_ SG_ 1531 SDCR_a015_reason_vPhaseShortedHi "SDCR ECU: a015 reason v phase shorted high";
CM_ SG_ 1531 SDCR_a015_diSwitchingPin "SDCR ECU: a015 di switching pin";
CM_ SG_ 1531 SDCR_a015_vBat "SDCR ECU: a015 v bat";
CM_ SG_ 1531 SDCR_a015_va "SDCR ECU: a015 va";
CM_ SG_ 1531 SDCR_a015_vb "SDCR ECU: a015 vb";
CM_ SG_ 1531 SDCR_a015_vc "SDCR ECU: a015 vc";
CM_ SG_ 1531 SDCR_a017_expectedConfigWord "SDCR ECU: a017 expected config word";
CM_ SG_ 1531 SDCR_a017_receivedConfigWord "SDCR ECU: a017 received config word";
CM_ SG_ 1531 SDCR_a018_pyroArmed "SDCR ECU: a018 pyro armed";
CM_ SG_ 1531 SDCR_a018_triggerReason_faultCur "SDCR ECU: a018 trigger reason fault currents";
CM_ SG_ 1531 SDCR_a018_triggerReason_hvBadAtS "SDCR ECU: a018 trigger reason hv bad at speed";
CM_ SG_ 1531 SDCR_a018_triggerReason_highBack "SDCR ECU: a018 trigger reason high back EMF";
CM_ SG_ 1531 SDCR_a018_faultCurrentsDetected "SDCR ECU: a018 fault currents detected";
CM_ SG_ 1531 SDCR_a018_diUartMIA "SDCR ECU: a018 di uart MIA";
CM_ SG_ 1531 SDCR_a018_pmRunningPin "SDCR ECU: a018 pm running pin";
CM_ SG_ 1531 SDCR_a018_hvPowerGood "SDCR ECU: a018 hv power good";
CM_ SG_ 1531 SDCR_a018_hvbkupPGoodPin "SDCR ECU: a018 hvbkup p good pin";
CM_ SG_ 1531 SDCR_a018_hvPowerNotGoodQualifie "SDCR ECU: a018 hv power not good qualified";
CM_ SG_ 1531 SDCR_a018_speedValid "SDCR ECU: a018 speed valid";
CM_ SG_ 1531 SDCR_a018_speedFromVoltage "SDCR ECU: a018 speed from voltage";
CM_ SG_ 1531 SDCR_a018_HVBackupSupplyV "SDCR ECU: a018 HV backup supply v";
CM_ SG_ 1531 SDCR_a018_boostRailV "SDCR ECU: a018 boost rail v";
CM_ SG_ 1531 SDCR_a018_maxAbsSpeed "SDCR ECU: a018 max abs speed";
CM_ SG_ 1531 SDCR_a018_vBat "SDCR ECU: a018 v bat";
CM_ SG_ 1531 SDCR_a019_faultReason_faultCurre "SDCR ECU: a019 fault reason fault currents at speed";
CM_ SG_ 1531 SDCR_a019_faultReason_unmitigate "SDCR ECU: a019 fault reason unmitigated UCR";
CM_ SG_ 1531 SDCR_a019_faultReason_propagatin "SDCR ECU: a019 fault reason propagating3 PS";
CM_ SG_ 1531 SDCR_a019_speedWasValid "SDCR ECU: a019 speed was valid";
CM_ SG_ 1531 SDCR_a019_imbalanceSeen "SDCR ECU: a019 imbalance seen";
CM_ SG_ 1531 SDCR_a019_ucrSeen "SDCR ECU: a019 ucr seen";
CM_ SG_ 1531 SDCR_a019_phaseVoltagePresent "SDCR ECU: a019 phase voltage present";
CM_ SG_ 1531 SDCR_a019_speedFromVoltage "SDCR ECU: a019 speed from voltage";
CM_ SG_ 1531 SDCR_a019_transientHandling "SDCR ECU: a019 transient handling";
CM_ SG_ 1531 SDCR_a019_maxAbsElcSpeed "SDCR ECU: a019 max abs elc speed";
CM_ SG_ 1531 SDCR_a019_avgIa "SDCR ECU: a019 avg ia";
CM_ SG_ 1531 SDCR_a019_avgIb "SDCR ECU: a019 avg ib";
CM_ SG_ 1531 SDCR_a019_maxAbsCurrents "SDCR ECU: a019 max abs currents";
CM_ SG_ 1531 SDCR_a020_errorCode "SDCR ECU: a020 error code";
CM_ SG_ 1531 SDCR_a020_rxData0 "SDCR ECU: a020 rx data0";
CM_ SG_ 1531 SDCR_a020_rxData1 "SDCR ECU: a020 rx data1";
CM_ SG_ 1531 SDCR_a020_rxData2 "SDCR ECU: a020 rx data2";
CM_ SG_ 1531 SDCR_a020_rxData3 "SDCR ECU: a020 rx data3";
CM_ SG_ 1531 SDCR_a020_rxData4 "SDCR ECU: a020 rx data4";
CM_ SG_ 1531 SDCR_a021_busBarTempC "SDCR ECU: a021 bus bar temp c; raw 0 = signal not available (SNA)";
CM_ SG_ 1531 SDCR_a021_busBarTempA "SDCR ECU: a021 bus bar temp a; raw 0 = signal not available (SNA)";
CM_ SG_ 1531 SDCR_a021_tempCVoltage "SDCR ECU: a021 temp c voltage";
CM_ SG_ 1531 SDCR_a021_tempAVoltage "SDCR ECU: a021 temp a voltage";
CM_ SG_ 1531 SDCR_a024_time "SDCR ECU: a024 time";
CM_ SG_ 1531 SDCR_a025_diSwitchingFromUart "SDCR ECU: a025 di switching from uart";
CM_ SG_ 1531 SDCR_a025_diSwitchingPin "SDCR ECU: a025 di switching pin";
CM_ SG_ 1531 SDCR_a025_pmRunningPin "SDCR ECU: a025 pm running pin";
CM_ SG_ 1531 SDCR_a025_diUartMIA "SDCR ECU: a025 di uart MIA";
CM_ SG_ 1531 SDCR_a025_HVBackupSupplyV "SDCR ECU: a025 HV backup supply v";
CM_ SG_ 1531 SDCR_a025_boostRailV "SDCR ECU: a025 boost rail v";
CM_ SG_ 1531 SDCR_a028_LVPowerState "SDCR ECU: a028 LV power state";
CM_ SG_ 1531 SDCR_a029_uartCommsMissing "SDCR ECU: a029 uart comms missing";
CM_ SG_ 1531 SDCR_a029_canCommsMissing "SDCR ECU: a029 can comms missing";
CM_ SG_ 1531 SDCR_a029_lvState "SDCR ECU: a029 lv state";
CM_ SG_ 1531 SDCR_a034_Ia "SDCR ECU: a034 ia";
CM_ SG_ 1531 SDCR_a034_Ib "SDCR ECU: a034 ib";
CM_ BO_ 1467 "SDCR ECU message: alert matrix";
CM_ SG_ 1467 SDCR_matrixIndex "SDCR ECU: matrix index";
CM_ SG_ 1467 SDCR_a001_powerOnSelfTestFailed "SDCR ECU: a001 power on self test failed";
CM_ SG_ 1467 SDCR_a002_diPstSkipped "SDCR ECU: a002 di pst skipped";
CM_ SG_ 1467 SDCR_a003_diUartMIA "SDCR ECU: a003 di uart MIA";
CM_ SG_ 1467 SDCR_a004_pmRunningFdbkIrrationa "SDCR ECU: a004 pm running fdbk irrational";
CM_ SG_ 1467 SDCR_a005_motorSpeedIrrational "SDCR ECU: a005 motor speed irrational";
CM_ SG_ 1467 SDCR_a006_pyroTriggered "SDCR ECU: a006 pyro triggered";
CM_ SG_ 1467 SDCR_a007_faultCurrentsDetected "SDCR ECU: a007 fault currents detected";
CM_ SG_ 1467 SDCR_a008_hvlinkMIA "SDCR ECU: a008 hvlink MIA";
CM_ SG_ 1467 SDCR_a009_uartVersionMismatch "SDCR ECU: a009 uart version mismatch";
CM_ SG_ 1467 SDCR_a010_vrefIrrational "SDCR ECU: a010 vref irrational";
CM_ SG_ 1467 SDCR_a011_phaseCurrentOffset "SDCR ECU: a011 phase current offset";
CM_ SG_ 1467 SDCR_a012_vBoostSecIrrational "SDCR ECU: a012 v boost sec irrational";
CM_ SG_ 1467 SDCR_a013_vBkupIrrational "SDCR ECU: a013 v bkup irrational";
CM_ SG_ 1467 SDCR_a014_vBusIrrational "SDCR ECU: a014 v bus irrational";
CM_ SG_ 1467 SDCR_a015_phaseVIrrational "SDCR ECU: a015 phase v irrational";
CM_ SG_ 1467 SDCR_a016_systemReset "SDCR ECU: a016 system reset";
CM_ SG_ 1467 SDCR_a017_adcSPIError "SDCR ECU: a017 adc SPI error";
CM_ SG_ 1467 SDCR_a018_historicalPyroTrigger "SDCR ECU: a018 historical pyro trigger";
CM_ SG_ 1467 SDCR_a019_historicalFaultCurrent "SDCR ECU: a019 historical fault currents";
CM_ SG_ 1467 SDCR_a020_eepromSPIError "SDCR ECU: a020 eeprom SPI error";
CM_ SG_ 1467 SDCR_a021_busBarTempIrrational "SDCR ECU: a021 bus bar temp irrational";
CM_ SG_ 1467 SDCR_a022_TaskInitError "SDCR ECU: a022 task init error";
CM_ SG_ 1467 SDCR_a023_ecuLogAvailable "SDCR ECU: a023 ecu log available";
CM_ SG_ 1467 SDCR_a024_gtwMIA "SDCR ECU: a024 gtw MIA";
CM_ SG_ 1467 SDCR_a025_diSwitchingFdbkIrratio "SDCR ECU: a025 di switching fdbk irrational";
CM_ SG_ 1467 SDCR_a026_faultCurrentMonitoring "SDCR ECU: a026 fault current monitoring disabled";
CM_ SG_ 1467 SDCR_a027_diCanMIA "SDCR ECU: a027 di can MIA";
CM_ SG_ 1467 SDCR_a028_vcLVStateMIA "SDCR ECU: a028 vc LV state MIA";
CM_ SG_ 1467 SDCR_a029_diMIA "SDCR ECU: a029 di MIA";
CM_ SG_ 1467 SDCR_a030_placeholder30 "SDCR ECU: a030 placeholder30";
CM_ SG_ 1467 SDCR_a031_placeholder31 "SDCR ECU: a031 placeholder31";
CM_ SG_ 1467 SDCR_a032_placeholder32 "SDCR ECU: a032 placeholder32";
CM_ SG_ 1467 SDCR_a033_placeholder33 "SDCR ECU: a033 placeholder33";
CM_ SG_ 1467 SDCR_a034_phaseCurrentIrrational "SDCR ECU: a034 phase current irrational";
CM_ BO_ 1597 "SDCR ECU message: info";
CM_ SG_ 1597 SDCR_infoIndex "SDCR ECU: info index";
CM_ SG_ 1597 SDCR_infoBuildType "SDCR ECU: info build type";
CM_ SG_ 1597 SDCR_infoBuildConfigId "SDCR ECU: info build config id";
CM_ SG_ 1597 SDCR_infoHardwareId "SDCR ECU: info hardware id";
CM_ SG_ 1597 SDCR_infoComponentId "SDCR ECU: info component id";
CM_ SG_ 1597 SDCR_infoPcbaId "SDCR ECU: info pcba id";
CM_ SG_ 1597 SDCR_infoAssemblyId "SDCR ECU: info assembly id";
CM_ SG_ 1597 SDCR_infoUsageId "SDCR ECU: info usage id";
CM_ SG_ 1597 SDCR_infoSubUsageId "SDCR ECU: info sub usage id";
CM_ SG_ 1597 SDCR_infoAppCrc "SDCR ECU: info app crc";
CM_ SG_ 1597 SDCR_infoBootGitHash "SDCR ECU: info boot git hash";
CM_ BO_ 1787 "SDCR ECU message: uds response";
CM_ SG_ 1787 SDCR_udsResponseData "SDCR ECU: uds response data";
BA_DEF_ BO_ "GenMsgCycleTime" INT 0 3600000;
BA_DEF_ BO_ "GenMsgSendType" ENUM "Cyclic","NotUsed","NotUsed","NotUsed","NotUsed","NotUsed","NotUsed","IfActive","NoMsgSendType","NotUsed";
BA_DEF_ BO_ "VFrameFormat" ENUM "StandardCAN","ExtendedCAN","reserved","J1939PG","reserved","reserved","reserved","reserved","reserved","reserved","reserved","reserved","reserved","reserved","StandardCAN_FD","ExtendedCAN_FD";
BA_DEF_ BO_ "CANFD_BRS" ENUM "0","1";
BA_DEF_ SG_ "GenSigSNA" STRING;
BA_DEF_ SG_ "SystemSignalLongSymbol" STRING;
BA_DEF_ SG_ "Confidence" ENUM "validated","plausible","layout-only","contradicted";
BA_DEF_DEF_ "GenMsgCycleTime" 0;
BA_DEF_DEF_ "GenMsgSendType" "NoMsgSendType";
BA_DEF_DEF_ "VFrameFormat" "StandardCAN";
BA_DEF_DEF_ "CANFD_BRS" "1";
BA_DEF_DEF_ "GenSigSNA" "";
BA_DEF_DEF_ "SystemSignalLongSymbol" "";
BA_DEF_DEF_ "Confidence" "layout-only";
BA_ "GenMsgCycleTime" BO_ 998 1000;
BA_ "GenMsgSendType" BO_ 998 0;
BA_ "GenMsgCycleTime" BO_ 831 10000;
BA_ "GenMsgSendType" BO_ 831 0;
BA_ "GenMsgCycleTime" BO_ 1359 100;
BA_ "GenMsgSendType" BO_ 1359 0;
BA_ "GenMsgCycleTime" BO_ 816 1000;
BA_ "GenMsgSendType" BO_ 816 0;
BA_ "GenMsgCycleTime" BO_ 585 50;
BA_ "GenMsgSendType" BO_ 585 0;
BA_ "GenMsgCycleTime" BO_ 553 100;
BA_ "GenMsgSendType" BO_ 553 0;
BA_ "GenMsgCycleTime" BO_ 297 10;
BA_ "GenMsgSendType" BO_ 297 0;
BA_ "GenMsgCycleTime" BO_ 815 1000;
BA_ "GenMsgSendType" BO_ 815 0;
BA_ "GenMsgCycleTime" BO_ 1355 1000;
BA_ "GenMsgSendType" BO_ 1355 0;
BA_ "GenMsgCycleTime" BO_ 869 1000;
BA_ "GenMsgSendType" BO_ 869 0;
BA_ "GenMsgCycleTime" BO_ 880 1000;
BA_ "GenMsgSendType" BO_ 880 0;
BA_ "GenMsgCycleTime" BO_ 1467 1000;
BA_ "GenMsgSendType" BO_ 1467 0;
BA_ "GenMsgCycleTime" BO_ 1597 1000;
BA_ "GenMsgSendType" BO_ 1597 0;
BA_ "Confidence" SG_ 1471 RCU_alertID 1;
BA_ "Confidence" SG_ 1471 RCU_alertState 1;
BA_ "Confidence" SG_ 1471 RCU_a010_sensorPowerSupply 1;
BA_ "Confidence" SG_ 1471 RCU_a010_sensorHardware 1;
BA_ "Confidence" SG_ 1471 RCU_a010_sensorSignal 1;
BA_ "Confidence" SG_ 1471 RCU_a023_validityOnChassisBus 1;
BA_ "Confidence" SG_ 1471 RCU_a023_validityOnPartyBus 1;
BA_ "Confidence" SG_ 1471 RCU_a024_validityOnChassisBus 1;
BA_ "Confidence" SG_ 1471 RCU_a024_validityOnPartyBus 1;
BA_ "Confidence" SG_ 1471 RCU_a025_validityOnChassisBus 1;
BA_ "Confidence" SG_ 1471 RCU_a025_validityOnPartyBus 1;
BA_ "Confidence" SG_ 1471 RCU_a035_validityOnChassisBus 1;
BA_ "Confidence" SG_ 1471 RCU_a035_validityOnPartyBus 1;
BA_ "Confidence" SG_ 1471 RCU_a036_validityOnChassisBus 1;
BA_ "Confidence" SG_ 1471 RCU_a036_validityOnPartyBus 1;
BA_ "Confidence" SG_ 998 RCU_matrixIndex 1;
BA_ "SystemSignalLongSymbol" SG_ 998 RCU_a033_VCFRONTLVPowerStateChec "RCU_a033_VCFRONTLVPowerStateChecksum";
BA_ "SystemSignalLongSymbol" SG_ 998 RCU_a034_VCFRONTLVPowerStateCoun "RCU_a034_VCFRONTLVPowerStateCounter";
BA_ "SystemSignalLongSymbol" SG_ 998 RCU_a037_IDBinputRodStrokeInvali "RCU_a037_IDBinputRodStrokeInvalid";
BA_ "SystemSignalLongSymbol" SG_ 998 RCU_a043_VCFRONTiBoosterLvStateI "RCU_a043_VCFRONTiBoosterLvStateInvalid";
BA_ "SystemSignalLongSymbol" SG_ 998 RCU_a055_IDBsimulatorPressFaulte "RCU_a055_IDBsimulatorPressFaulted";
BA_ "SystemSignalLongSymbol" SG_ 998 RCU_a056_redundantControllerIsMa "RCU_a056_redundantControllerIsMaster";
BA_ "SystemSignalLongSymbol" SG_ 998 RCU_a058_DIbrakeTorqueCommandAnd "RCU_a058_DIbrakeTorqueCommandAndFlagMismatch";
BA_ "Confidence" SG_ 831 RCU_infoIndex 1;
BA_ "Confidence" SG_ 831 RCU_infoPcbaID 0;
BA_ "Confidence" SG_ 831 RCU_infoAssemblyID 0;
BA_ "Confidence" SG_ 831 RCU_infoUsageID 0;
BA_ "Confidence" SG_ 831 RCU_infoSubUsageID 0;
BA_ "Confidence" SG_ 1344 SCCM_alertID 1;
BA_ "Confidence" SG_ 1344 SCCM_alertState 1;
BA_ "Confidence" SG_ 1344 SCCM_a003_debouncePosition 1;
BA_ "Confidence" SG_ 1344 SCCM_a003_rawPosition 1;
BA_ "Confidence" SG_ 1344 SCCM_a003_errorPosition 1;
BA_ "Confidence" SG_ 1344 SCCM_a003_adcValue 1;
BA_ "Confidence" SG_ 1344 SCCM_a004_debouncePosition 1;
BA_ "Confidence" SG_ 1344 SCCM_a004_rawPosition 1;
BA_ "Confidence" SG_ 1344 SCCM_a004_errorPosition 1;
BA_ "Confidence" SG_ 1344 SCCM_a004_adcValue 1;
BA_ "Confidence" SG_ 1344 SCCM_a005_debouncePosition 1;
BA_ "Confidence" SG_ 1344 SCCM_a005_rawPosition 1;
BA_ "Confidence" SG_ 1344 SCCM_a005_errorPosition 1;
BA_ "Confidence" SG_ 1344 SCCM_a005_adcValue 1;
BA_ "Confidence" SG_ 1344 SCCM_a006_debouncePosition 1;
BA_ "Confidence" SG_ 1344 SCCM_a006_rawPosition 1;
BA_ "Confidence" SG_ 1344 SCCM_a006_errorPosition 1;
BA_ "Confidence" SG_ 1344 SCCM_a006_adcValue 1;
BA_ "Confidence" SG_ 1344 SCCM_a007_debouncePosition 1;
BA_ "Confidence" SG_ 1344 SCCM_a007_rawPosition 1;
BA_ "Confidence" SG_ 1344 SCCM_a007_errorPosition 1;
BA_ "Confidence" SG_ 1344 SCCM_a007_adcValue1 1;
BA_ "Confidence" SG_ 1344 SCCM_a007_adcValue2 1;
BA_ "Confidence" SG_ 1344 SCCM_a008_debouncePosition 1;
BA_ "Confidence" SG_ 1344 SCCM_a008_rawPosition 1;
BA_ "Confidence" SG_ 1344 SCCM_a008_errorPosition 1;
BA_ "Confidence" SG_ 1344 SCCM_a008_adcValue1 1;
BA_ "Confidence" SG_ 1344 SCCM_a008_adcValue2 1;
BA_ "Confidence" SG_ 1344 SCCM_a009_debouncePosition 1;
BA_ "Confidence" SG_ 1344 SCCM_a009_rawPosition 1;
BA_ "Confidence" SG_ 1344 SCCM_a009_errorPosition 1;
BA_ "Confidence" SG_ 1344 SCCM_a009_adcValue1 1;
BA_ "Confidence" SG_ 1344 SCCM_a009_adcValue2 1;
BA_ "Confidence" SG_ 1344 SCCM_a010_debouncePosition 1;
BA_ "Confidence" SG_ 1344 SCCM_a010_rawPosition 1;
BA_ "Confidence" SG_ 1344 SCCM_a010_errorPosition 1;
BA_ "Confidence" SG_ 1344 SCCM_a010_adcValue1 1;
BA_ "Confidence" SG_ 1344 SCCM_a010_adcValue2 1;
BA_ "Confidence" SG_ 1344 SCCM_a011_debouncePosition 1;
BA_ "Confidence" SG_ 1344 SCCM_a011_rawPosition 1;
BA_ "Confidence" SG_ 1344 SCCM_a011_errorPosition 1;
BA_ "Confidence" SG_ 1344 SCCM_a011_adcValue1 1;
BA_ "Confidence" SG_ 1344 SCCM_a011_adcValue2 1;
BA_ "Confidence" SG_ 1344 SCCM_a012_debouncePosition 1;
BA_ "Confidence" SG_ 1344 SCCM_a012_rawPosition 1;
BA_ "Confidence" SG_ 1344 SCCM_a012_errorPosition 1;
BA_ "Confidence" SG_ 1344 SCCM_a012_adcValue1 1;
BA_ "Confidence" SG_ 1344 SCCM_a012_adcValue2 1;
BA_ "Confidence" SG_ 1344 SCCM_a013_voltage 1;
BA_ "Confidence" SG_ 1344 SCCM_a014_voltage 1;
BA_ "Confidence" SG_ 1344 SCCM_a015_intMainIndex 1;
BA_ "Confidence" SG_ 1344 SCCM_a015_intSubIndex 1;
BA_ "Confidence" SG_ 1344 SCCM_a015_intMemIndex 1;
BA_ "Confidence" SG_ 1344 SCCM_a016_mainAdcTest 1;
BA_ "Confidence" SG_ 1344 SCCM_a016_mainCpuTest 1;
BA_ "Confidence" SG_ 1344 SCCM_a016_wdtTest 1;
BA_ "Confidence" SG_ 1344 SCCM_a016_subCpuTest 1;
BA_ "Confidence" SG_ 1344 SCCM_a016_subAdcTest 1;
BA_ "Confidence" SG_ 1344 SCCM_a017_mainRamTest 1;
BA_ "Confidence" SG_ 1344 SCCM_a017_mainRomTest 1;
BA_ "Confidence" SG_ 1344 SCCM_a017_stackHardLimitTest 1;
BA_ "Confidence" SG_ 1344 SCCM_a017_mainDataFlashTest 1;
BA_ "Confidence" SG_ 1344 SCCM_a017_subRamTest 1;
BA_ "Confidence" SG_ 1344 SCCM_a017_subRomTest 1;
BA_ "Confidence" SG_ 1344 SCCM_a017_subStackHardLimitTest 1;
BA_ "Confidence" SG_ 1344 SCCM_a017_svError 1;
BA_ "Confidence" SG_ 1344 SCCM_a018_internalSASState 1;
BA_ "Confidence" SG_ 1344 SCCM_a019_internalSASState 1;
BA_ "Confidence" SG_ 1344 SCCM_a020_internalSASState 1;
BA_ "Confidence" SG_ 1344 SCCM_a021_adcValue1 1;
BA_ "Confidence" SG_ 1344 SCCM_a021_adcValue2 1;
BA_ "Confidence" SG_ 1344 SCCM_a021_adcValue3 1;
BA_ "Confidence" SG_ 1344 SCCM_a021_adcValue4 1;
BA_ "Confidence" SG_ 1344 SCCM_a021_adcValue5 1;
BA_ "Confidence" SG_ 1344 SCCM_a021_adcValue6 1;
BA_ "Confidence" SG_ 1344 SCCM_a022_adcValue1 1;
BA_ "Confidence" SG_ 1344 SCCM_a022_adcValue2 1;
BA_ "Confidence" SG_ 1344 SCCM_a022_adcValue3 1;
BA_ "Confidence" SG_ 1344 SCCM_a022_adcValue4 1;
BA_ "Confidence" SG_ 1344 SCCM_a022_adcValue5 1;
BA_ "Confidence" SG_ 1344 SCCM_a022_adcValue6 1;
BA_ "Confidence" SG_ 1344 SCCM_a023_adcValue1 1;
BA_ "Confidence" SG_ 1344 SCCM_a023_adcValue2 1;
BA_ "Confidence" SG_ 1344 SCCM_a023_adcValue3 1;
BA_ "Confidence" SG_ 1344 SCCM_a023_adcValue4 1;
BA_ "Confidence" SG_ 1344 SCCM_a023_adcValue5 1;
BA_ "Confidence" SG_ 1344 SCCM_a023_adcValue6 1;
BA_ "Confidence" SG_ 1344 SCCM_a024_adcValue1 1;
BA_ "Confidence" SG_ 1344 SCCM_a024_adcValue2 1;
BA_ "Confidence" SG_ 1344 SCCM_a024_adcValue3 1;
BA_ "Confidence" SG_ 1344 SCCM_a024_adcValue4 1;
BA_ "Confidence" SG_ 1344 SCCM_a024_adcValue5 1;
BA_ "Confidence" SG_ 1344 SCCM_a024_adcValue6 1;
BA_ "Confidence" SG_ 1344 SCCM_a025_taskState 1;
BA_ "Confidence" SG_ 1344 SCCM_a026_debouncePosition 1;
BA_ "Confidence" SG_ 1344 SCCM_a026_rawPosition 1;
BA_ "Confidence" SG_ 1344 SCCM_a026_errorPosition 1;
BA_ "Confidence" SG_ 1344 SCCM_a026_adcValue1 1;
BA_ "Confidence" SG_ 1344 SCCM_a026_adcValue2 1;
BA_ "Confidence" SG_ 1344 SCCM_a027_debouncePosition 1;
BA_ "Confidence" SG_ 1344 SCCM_a027_rawPosition 1;
BA_ "Confidence" SG_ 1344 SCCM_a027_errorPosition 1;
BA_ "Confidence" SG_ 1344 SCCM_a027_adcValue1 1;
BA_ "Confidence" SG_ 1344 SCCM_a027_adcValue2 1;
BA_ "Confidence" SG_ 1344 SCCM_a028_debouncePosition 1;
BA_ "Confidence" SG_ 1344 SCCM_a028_rawPosition 1;
BA_ "Confidence" SG_ 1344 SCCM_a028_errorPosition 1;
BA_ "Confidence" SG_ 1344 SCCM_a028_adcValue1 1;
BA_ "Confidence" SG_ 1344 SCCM_a028_adcValue2 1;
BA_ "Confidence" SG_ 1344 SCCM_a029_debouncePosition 1;
BA_ "Confidence" SG_ 1344 SCCM_a029_rawPosition 1;
BA_ "Confidence" SG_ 1344 SCCM_a029_errorPosition 1;
BA_ "Confidence" SG_ 1344 SCCM_a029_adcValue1 1;
BA_ "Confidence" SG_ 1344 SCCM_a029_adcValue2 1;
BA_ "Confidence" SG_ 1344 SCCM_a061_voltage 1;
BA_ "Confidence" SG_ 1344 SCCM_a062_voltage 1;
BA_ "Confidence" SG_ 1344 SCCM_a063_UntrimmedAngle 1;
BA_ "GenSigSNA" SG_ 1344 SCCM_a063_UntrimmedAngle "16383";
BA_ "Confidence" SG_ 1344 SCCM_a064_Speed 1;
BA_ "GenSigSNA" SG_ 1344 SCCM_a064_Speed "16383";
BA_ "Confidence" SG_ 1344 SCCM_a065_M1RawAngleCurrent 1;
BA_ "Confidence" SG_ 1344 SCCM_a065_M1RawAnglePrevious 1;
BA_ "Confidence" SG_ 1344 SCCM_a065_M2RawAngleCurrent 1;
BA_ "Confidence" SG_ 1344 SCCM_a065_M2RawAnglePrevious 1;
BA_ "Confidence" SG_ 1344 SCCM_a066_M1RawAngleCurrent 1;
BA_ "Confidence" SG_ 1344 SCCM_a066_M1RawAnglePrevious 1;
BA_ "Confidence" SG_ 1344 SCCM_a066_M2RawAngleCurrent 1;
BA_ "Confidence" SG_ 1344 SCCM_a066_M2RawAnglePrevious 1;
BA_ "Confidence" SG_ 1344 SCCM_a077_M1ExpectAngleCurrent 1;
BA_ "Confidence" SG_ 1344 SCCM_a077_M1ExpectAnglePrevious 1;
BA_ "Confidence" SG_ 1344 SCCM_a077_M1AngleCurrent 1;
BA_ "Confidence" SG_ 1344 SCCM_a077_M1AnglePrevious 1;
BA_ "Confidence" SG_ 1344 SCCM_a079_ChipTemperature 1;
BA_ "Confidence" SG_ 1344 SCCM_a121_turnIndicatorStalkAngl 1;
BA_ "SystemSignalLongSymbol" SG_ 1344 SCCM_a121_turnIndicatorStalkAngl "SCCM_a121_turnIndicatorStalkAngle";
BA_ "Confidence" SG_ 1344 SCCM_a121_turnIndicatorHallAngle 1;
BA_ "Confidence" SG_ 1344 SCCM_a122_turnIndicatorSpeed 1;
BA_ "Confidence" SG_ 1344 SCCM_a123_turnIndicatorStalkAngl 1;
BA_ "SystemSignalLongSymbol" SG_ 1344 SCCM_a123_turnIndicatorStalkAngl "SCCM_a123_turnIndicatorStalkAngle";
BA_ "Confidence" SG_ 1344 SCCM_a124_turnIndicatorStalkAngl 1;
BA_ "SystemSignalLongSymbol" SG_ 1344 SCCM_a124_turnIndicatorStalkAngl "SCCM_a124_turnIndicatorStalkAngle";
BA_ "Confidence" SG_ 1344 SCCM_a125_turnIndicatorHallAngle 1;
BA_ "Confidence" SG_ 1344 SCCM_a125_turnIndicatorVectorAng 1;
BA_ "SystemSignalLongSymbol" SG_ 1344 SCCM_a125_turnIndicatorVectorAng "SCCM_a125_turnIndicatorVectorAngle";
BA_ "SystemSignalLongSymbol" SG_ 1344 SCCM_a126_turnIndicatorXVectorOu "SCCM_a126_turnIndicatorXVectorOutOfRange";
BA_ "SystemSignalLongSymbol" SG_ 1344 SCCM_a126_turnIndicatorYVectorOu "SCCM_a126_turnIndicatorYVectorOutOfRange";
BA_ "SystemSignalLongSymbol" SG_ 1344 SCCM_a126_turnIndicatorZVectorOu "SCCM_a126_turnIndicatorZVectorOutOfRange";
BA_ "SystemSignalLongSymbol" SG_ 1344 SCCM_a126_turnIndicatorResu_0001 "SCCM_a126_turnIndicatorResultantOutOfRange";
BA_ "Confidence" SG_ 1344 SCCM_a126_turnIndicatorXMagnitud 1;
BA_ "SystemSignalLongSymbol" SG_ 1344 SCCM_a126_turnIndicatorXMagnitud "SCCM_a126_turnIndicatorXMagnitude";
BA_ "Confidence" SG_ 1344 SCCM_a126_turnIndicatorYMagnitud 1;
BA_ "SystemSignalLongSymbol" SG_ 1344 SCCM_a126_turnIndicatorYMagnitud "SCCM_a126_turnIndicatorYMagnitude";
BA_ "Confidence" SG_ 1344 SCCM_a126_turnIndicatorZMagnitud 1;
BA_ "SystemSignalLongSymbol" SG_ 1344 SCCM_a126_turnIndicatorZMagnitud "SCCM_a126_turnIndicatorZMagnitude";
BA_ "Confidence" SG_ 1344 SCCM_a126_turnIndicatorResultant 1;
BA_ "SystemSignalLongSymbol" SG_ 1344 SCCM_a126_turnIndicatorResultant "SCCM_a126_turnIndicatorResultantMagnitude";
BA_ "Confidence" SG_ 1359 SCCM_matrixIndex 1;
BA_ "SystemSignalLongSymbol" SG_ 1359 SCCM_a026_parkButtonInvalidSigna "SCCM_a026_parkButtonInvalidSignal";
BA_ "SystemSignalLongSymbol" SG_ 1359 SCCM_a028_parkButtonShortToGroun "SCCM_a028_parkButtonShortToGround";
BA_ "SystemSignalLongSymbol" SG_ 1359 SCCM_a121_turnIndicatorAngleInva "SCCM_a121_turnIndicatorAngleInvalid";
BA_ "SystemSignalLongSymbol" SG_ 1359 SCCM_a122_turnIndicatorSpeedInva "SCCM_a122_turnIndicatorSpeedInvalid";
BA_ "SystemSignalLongSymbol" SG_ 1359 SCCM_a123_turnIndicatorStuckActi "SCCM_a123_turnIndicatorStuckActive";
BA_ "SystemSignalLongSymbol" SG_ 1359 SCCM_a124_turnIndicatorIdleInval "SCCM_a124_turnIndicatorIdleInvalid";
BA_ "SystemSignalLongSymbol" SG_ 1359 SCCM_a125_turnIndicatorHallAngle "SCCM_a125_turnIndicatorHallAngleMismatch";
BA_ "SystemSignalLongSymbol" SG_ 1359 SCCM_a126_turnIndicatorHallMagOu "SCCM_a126_turnIndicatorHallMagOutOfRange";
BA_ "Confidence" SG_ 816 SCCM_infoIndex 1;
BA_ "Confidence" SG_ 816 SCCM_infoBuildType 0;
BA_ "Confidence" SG_ 816 SCCM_infoBuildConfigId 0;
BA_ "Confidence" SG_ 816 SCCM_infoHardwareId 0;
BA_ "Confidence" SG_ 816 SCCM_infoComponentId 0;
BA_ "Confidence" SG_ 816 SCCM_infoPcbaId 0;
BA_ "Confidence" SG_ 816 SCCM_infoAssemblyId 0;
BA_ "Confidence" SG_ 816 SCCM_infoUsageId 0;
BA_ "Confidence" SG_ 816 SCCM_infoSubUsageId 0;
BA_ "Confidence" SG_ 816 SCCM_infoPlatformType 0;
BA_ "Confidence" SG_ 816 SCCM_infoBootSvnRev 0;
BA_ "Confidence" SG_ 816 SCCM_infoBootSvnUrlHash 0;
BA_ "Confidence" SG_ 816 SCCM_infoSubcomponent1Version 0;
BA_ "Confidence" SG_ 816 SCCM_infoAppSvnHash 0;
BA_ "Confidence" SG_ 816 SCCM_infoBootSvnHash 0;
BA_ "Confidence" SG_ 816 SCCM_infoUdsProtoVersion 0;
BA_ "Confidence" SG_ 816 SCCM_infoBootCrc 0;
BA_ "Confidence" SG_ 585 SCCM_leftStalkCrc 0;
BA_ "Confidence" SG_ 585 SCCM_leftStalkCounter 0;
BA_ "Confidence" SG_ 585 SCCM_highBeamStalkStatus 0;
BA_ "GenSigSNA" SG_ 585 SCCM_highBeamStalkStatus "3";
BA_ "Confidence" SG_ 585 SCCM_washWipeButtonStatus 0;
BA_ "GenSigSNA" SG_ 585 SCCM_washWipeButtonStatus "3";
BA_ "Confidence" SG_ 585 SCCM_turnIndicatorStalkStatus 0;
BA_ "GenSigSNA" SG_ 585 SCCM_turnIndicatorStalkStatus "9";
BA_ "Confidence" SG_ 585 SCCM_turnIndicatorStalkAngle 0;
BA_ "GenSigSNA" SG_ 585 SCCM_turnIndicatorStalkAngle "4095";
BA_ "Confidence" SG_ 553 SCCM_rightStalkCrc 0;
BA_ "Confidence" SG_ 553 SCCM_rightStalkCounter 0;
BA_ "Confidence" SG_ 553 SCCM_rightStalkStatus 0;
BA_ "GenSigSNA" SG_ 553 SCCM_rightStalkStatus "6";
BA_ "Confidence" SG_ 553 SCCM_rightStalkReserved1 0;
BA_ "Confidence" SG_ 553 SCCM_parkButtonStatus 0;
BA_ "GenSigSNA" SG_ 553 SCCM_parkButtonStatus "3";
BA_ "Confidence" SG_ 553 SCCM_rightStalkReserved2 0;
BA_ "Confidence" SG_ 297 SCCM_steeringAngleCrc 0;
BA_ "Confidence" SG_ 297 SCCM_steeringAngleCounter 0;
BA_ "Confidence" SG_ 297 SCCM_supplierID 0;
BA_ "Confidence" SG_ 297 SCCM_steeringAngleSensorStatus 0;
BA_ "Confidence" SG_ 297 SCCM_steeringAngle 0;
BA_ "GenSigSNA" SG_ 297 SCCM_steeringAngle "16383";
BA_ "Confidence" SG_ 297 SCCM_steeringAngleValidity 0;
BA_ "GenSigSNA" SG_ 297 SCCM_steeringAngleValidity "3";
BA_ "Confidence" SG_ 297 SCCM_steeringAngleSpeed 0;
BA_ "Confidence" SG_ 297 SCCM_steeringAngleSensorReservd1 0;
BA_ "Confidence" SG_ 297 SCCM_steeringAngleSensorReservd2 0;
BA_ "Confidence" SG_ 297 SCCM_steeringAngleSensorReservd3 0;
BA_ "Confidence" SG_ 1680 SCCM_functionalResponseData_0 1;
BA_ "Confidence" SG_ 1680 SCCM_functionalResponseData_1 1;
BA_ "Confidence" SG_ 1680 SCCM_functionalResponseData_2 1;
BA_ "Confidence" SG_ 1680 SCCM_functionalResponseData_3 1;
BA_ "Confidence" SG_ 1680 SCCM_functionalResponseData_4 1;
BA_ "Confidence" SG_ 1680 SCCM_functionalResponseData_5 1;
BA_ "Confidence" SG_ 1680 SCCM_functionalResponseData_6 1;
BA_ "Confidence" SG_ 1680 SCCM_functionalResponseData_7 1;
BA_ "Confidence" SG_ 1356 SCM_alertID 1;
BA_ "Confidence" SG_ 1356 SCM_alertType 1;
BA_ "Confidence" SG_ 1354 SCS_alertID 1;
BA_ "Confidence" SG_ 1354 SCS_alertType 1;
BA_ "Confidence" SG_ 1354 SCS_a044_proximityV 1;
BA_ "Confidence" SG_ 1354 SCS_a074_voltageWithRo 1;
BA_ "Confidence" SG_ 1354 SCS_a074_voltageWithoutRo 1;
BA_ "Confidence" SG_ 1531 SDCR_alertID 1;
BA_ "Confidence" SG_ 1531 SDCR_alertState 1;
BA_ "Confidence" SG_ 1531 SDCR_a001_pyroSenseV 1;
BA_ "Confidence" SG_ 1531 SDCR_a001_HVBackupSupplyV 1;
BA_ "Confidence" SG_ 1531 SDCR_a001_boostRailV 1;
BA_ "Confidence" SG_ 1531 SDCR_a001_expectedPyroV_max 1;
BA_ "Confidence" SG_ 1531 SDCR_a001_expectedPyroV_min 1;
BA_ "Confidence" SG_ 1531 SDCR_a001_fromState 1;
BA_ "Confidence" SG_ 1531 SDCR_a004_HVBackupSupplyV 1;
BA_ "Confidence" SG_ 1531 SDCR_a004_boostRailV 1;
BA_ "SystemSignalLongSymbol" SG_ 1531 SDCR_a006_triggerReason_faultCur "SDCR_a006_triggerReason_faultCurrents";
BA_ "SystemSignalLongSymbol" SG_ 1531 SDCR_a006_triggerReason_hvBadAtS "SDCR_a006_triggerReason_hvBadAtSpeed";
BA_ "SystemSignalLongSymbol" SG_ 1531 SDCR_a006_triggerReason_highBack "SDCR_a006_triggerReason_highBackEMF";
BA_ "SystemSignalLongSymbol" SG_ 1531 SDCR_a006_hvPowerNotGoodQualifie "SDCR_a006_hvPowerNotGoodQualified";
BA_ "Confidence" SG_ 1531 SDCR_a006_HVBackupSupplyV 1;
BA_ "Confidence" SG_ 1531 SDCR_a006_boostRailV 1;
BA_ "Confidence" SG_ 1531 SDCR_a006_maxAbsSpeed 1;
BA_ "Confidence" SG_ 1531 SDCR_a006_vBat 1;
BA_ "SystemSignalLongSymbol" SG_ 1531 SDCR_a007_faultReason_faultCurre "SDCR_a007_faultReason_faultCurrentsAtSpeed";
BA_ "SystemSignalLongSymbol" SG_ 1531 SDCR_a007_faultReason_unmitigate "SDCR_a007_faultReason_unmitigatedUCR";
BA_ "SystemSignalLongSymbol" SG_ 1531 SDCR_a007_faultReason_propagatin "SDCR_a007_faultReason_propagating3PS";
BA_ "Confidence" SG_ 1531 SDCR_a007_transientHandling 1;
BA_ "Confidence" SG_ 1531 SDCR_a007_maxAbsElcSpeed 1;
BA_ "Confidence" SG_ 1531 SDCR_a007_avgIa 1;
BA_ "Confidence" SG_ 1531 SDCR_a007_avgIb 1;
BA_ "Confidence" SG_ 1531 SDCR_a007_maxAbsCurrents 1;
BA_ "Confidence" SG_ 1531 SDCR_a010_boostRailV 1;
BA_ "Confidence" SG_ 1531 SDCR_a010_Vref 1;
BA_ "Confidence" SG_ 1531 SDCR_a011_IaAvg 1;
BA_ "Confidence" SG_ 1531 SDCR_a011_IbAvg 1;
BA_ "Confidence" SG_ 1531 SDCR_a012_boostRailV 1;
BA_ "Confidence" SG_ 1531 SDCR_a012_HVBackupSupplyV 1;
BA_ "Confidence" SG_ 1531 SDCR_a012_vBat 1;
BA_ "Confidence" SG_ 1531 SDCR_a013_boostRailV 1;
BA_ "Confidence" SG_ 1531 SDCR_a013_HVBackupSupplyV 1;
BA_ "Confidence" SG_ 1531 SDCR_a013_vBat 1;
BA_ "Confidence" SG_ 1531 SDCR_a014_boostRailV 1;
BA_ "Confidence" SG_ 1531 SDCR_a014_HVBackupSupplyV 1;
BA_ "Confidence" SG_ 1531 SDCR_a014_vBat 1;
BA_ "SystemSignalLongSymbol" SG_ 1531 SDCR_a015_reason_vPhaseShortedLo "SDCR_a015_reason_vPhaseShortedLow";
BA_ "SystemSignalLongSymbol" SG_ 1531 SDCR_a015_reason_vPhaseShortedHi "SDCR_a015_reason_vPhaseShortedHigh";
BA_ "Confidence" SG_ 1531 SDCR_a015_vBat 1;
BA_ "Confidence" SG_ 1531 SDCR_a015_va 1;
BA_ "Confidence" SG_ 1531 SDCR_a015_vb 1;
BA_ "Confidence" SG_ 1531 SDCR_a015_vc 1;
BA_ "SystemSignalLongSymbol" SG_ 1531 SDCR_a018_triggerReason_faultCur "SDCR_a018_triggerReason_faultCurrents";
BA_ "SystemSignalLongSymbol" SG_ 1531 SDCR_a018_triggerReason_hvBadAtS "SDCR_a018_triggerReason_hvBadAtSpeed";
BA_ "SystemSignalLongSymbol" SG_ 1531 SDCR_a018_triggerReason_highBack "SDCR_a018_triggerReason_highBackEMF";
BA_ "SystemSignalLongSymbol" SG_ 1531 SDCR_a018_hvPowerNotGoodQualifie "SDCR_a018_hvPowerNotGoodQualified";
BA_ "Confidence" SG_ 1531 SDCR_a018_HVBackupSupplyV 1;
BA_ "Confidence" SG_ 1531 SDCR_a018_boostRailV 1;
BA_ "Confidence" SG_ 1531 SDCR_a018_maxAbsSpeed 1;
BA_ "Confidence" SG_ 1531 SDCR_a018_vBat 1;
BA_ "SystemSignalLongSymbol" SG_ 1531 SDCR_a019_faultReason_faultCurre "SDCR_a019_faultReason_faultCurrentsAtSpeed";
BA_ "SystemSignalLongSymbol" SG_ 1531 SDCR_a019_faultReason_unmitigate "SDCR_a019_faultReason_unmitigatedUCR";
BA_ "SystemSignalLongSymbol" SG_ 1531 SDCR_a019_faultReason_propagatin "SDCR_a019_faultReason_propagating3PS";
BA_ "Confidence" SG_ 1531 SDCR_a019_transientHandling 1;
BA_ "Confidence" SG_ 1531 SDCR_a019_maxAbsElcSpeed 1;
BA_ "Confidence" SG_ 1531 SDCR_a019_avgIa 1;
BA_ "Confidence" SG_ 1531 SDCR_a019_avgIb 1;
BA_ "Confidence" SG_ 1531 SDCR_a019_maxAbsCurrents 1;
BA_ "Confidence" SG_ 1531 SDCR_a020_errorCode 1;
BA_ "Confidence" SG_ 1531 SDCR_a021_busBarTempC 1;
BA_ "GenSigSNA" SG_ 1531 SDCR_a021_busBarTempC "0";
BA_ "Confidence" SG_ 1531 SDCR_a021_busBarTempA 1;
BA_ "GenSigSNA" SG_ 1531 SDCR_a021_busBarTempA "0";
BA_ "Confidence" SG_ 1531 SDCR_a021_tempCVoltage 1;
BA_ "Confidence" SG_ 1531 SDCR_a021_tempAVoltage 1;
BA_ "Confidence" SG_ 1531 SDCR_a025_HVBackupSupplyV 1;
BA_ "Confidence" SG_ 1531 SDCR_a025_boostRailV 1;
BA_ "Confidence" SG_ 1531 SDCR_a029_lvState 1;
BA_ "Confidence" SG_ 1531 SDCR_a034_Ia 1;
BA_ "Confidence" SG_ 1531 SDCR_a034_Ib 1;
BA_ "Confidence" SG_ 1467 SDCR_matrixIndex 1;
BA_ "SystemSignalLongSymbol" SG_ 1467 SDCR_a004_pmRunningFdbkIrrationa "SDCR_a004_pmRunningFdbkIrrational";
BA_ "SystemSignalLongSymbol" SG_ 1467 SDCR_a019_historicalFaultCurrent "SDCR_a019_historicalFaultCurrents";
BA_ "SystemSignalLongSymbol" SG_ 1467 SDCR_a025_diSwitchingFdbkIrratio "SDCR_a025_diSwitchingFdbkIrrational";
BA_ "SystemSignalLongSymbol" SG_ 1467 SDCR_a026_faultCurrentMonitoring "SDCR_a026_faultCurrentMonitoringDisabled";
BA_ "Confidence" SG_ 1597 SDCR_infoIndex 1;
BA_ "Confidence" SG_ 1597 SDCR_infoBuildType 1;
BA_ "Confidence" SG_ 1597 SDCR_infoBuildConfigId 0;
BA_ "Confidence" SG_ 1597 SDCR_infoHardwareId 0;
BA_ "Confidence" SG_ 1597 SDCR_infoSubUsageId 0;
BA_ "Confidence" SG_ 1597 SDCR_infoBootGitHash 0;
BA_ "Confidence" SG_ 1787 SDCR_udsResponseData 1;
VAL_ 1471 RCU_alertID 58 "a058_DIbrakeTorqueCommandAndFlagMismatch" 57 "a057_PMebrCmdStateInvalid" 56 "a056_redundantControllerIsMaster" 55 "a055_IDBsimulatorPressFaulted" 54 "a054_IDBcircuitPressFaulted" 53 "a053_ESPwheelSpeedsChecksum" 52 "a052_ESPwheelSpeedsCounter" 51 "a051_ESPReRWSSLInvalid" 50 "a050_ESPReLWSSLInvalid" 49 "a049_ESPFrRWSSLInvalid" 48 "a048_ESPFrLWSSLInvalid" 47 "a047_ESPwheelSpeedsDLC" 46 "a046_brakeFluidLevelSNA" 45 "a045_VCFRONTtempInvalid" 44 "a044_VCFRONTsensorsMIA" 43 "a043_VCFRONTiBoosterLvStateInvalid" 42 "a042_DIsystemStatusChecksum" 41 "a041_DIsystemStatusCounter" 40 "a040_DIgearInvalid" 39 "a039_DIaccelPosInvalid" 38 "a038_DIsystemStatusDLC" 37 "a037_IDBinputRodStrokeInvalid" 36 "a036_IDBpspInvalid" 35 "a035_IDBpcpInvalid" 34 "a034_VCFRONTLVPowerStateCounter" 33 "a033_VCFRONTLVPowerStateChecksum" 32 "a032_VCFRONTLVPowerStateDLC" 31 "a031_PMstate2Counter" 30 "a030_PMstate2Checksum" 29 "a029_PMstate2DLC" 28 "a028_DIchassisControlCounter" 27 "a027_DIchassisCtrlChecksum" 26 "a026_DIchassisControlDLC" 25 "a025_IDBstatusCounter" 24 "a024_IDBstatusChecksum" 23 "a023_IDBstatusDLC" 22 "a022_BBstatusCounter" 21 "a021_BBstatusChecksum" 20 "a020_BBstatusDLC" 19 "a019_DItorquePathActive" 18 "a018_DItorquePathFaulted" 17 "a017_chassisBusOff" 16 "a016_partyBusOff" 15 "a015_fluidLeakDetected" 14 "a014_asicTempHigh" 13 "a013_mcuGenericFault" 12 "a012_pedalSensorNotCal" 11 "a011_idbPedalTravelMismatch" 10 "a010_pedalSensorFault" 9 "a009_brakeFluidLow" 8 "a008_pressureNotCalibrated" 7 "a007_pressureSensorFault" 6 "a006_wakeLineOpen" 5 "a005_supplyUndervoltage" 4 "a004_supplyOvervoltage" 3 "a003_pumpMotorFault" 2 "a002_solenoidValveFault" 1 "a001_valveDriverFault" 0 "ALERT_DO_NOT_USE_ZERO" ;
VAL_ 1471 RCU_alertState 1 "SET" 0 "CLEARED" ;
VAL_ 1471 RCU_a010_sensorPowerSupply 1 "NOT_OK" 0 "OK" ;
VAL_ 1471 RCU_a010_sensorHardware 1 "NOT_OK" 0 "OK" ;
VAL_ 1471 RCU_a010_sensorSignal 1 "NOT_OK" 0 "OK" ;
VAL_ 1471 RCU_a023_validityOnChassisBus 1 "NOT_OK" 0 "OK" ;
VAL_ 1471 RCU_a023_validityOnPartyBus 1 "NOT_OK" 0 "OK" ;
VAL_ 1471 RCU_a024_validityOnChassisBus 1 "NOT_OK" 0 "OK" ;
VAL_ 1471 RCU_a024_validityOnPartyBus 1 "NOT_OK" 0 "OK" ;
VAL_ 1471 RCU_a025_validityOnChassisBus 1 "NOT_OK" 0 "OK" ;
VAL_ 1471 RCU_a025_validityOnPartyBus 1 "NOT_OK" 0 "OK" ;
VAL_ 1471 RCU_a035_validityOnChassisBus 1 "NOT_OK" 0 "OK" ;
VAL_ 1471 RCU_a035_validityOnPartyBus 1 "NOT_OK" 0 "OK" ;
VAL_ 1471 RCU_a036_validityOnChassisBus 1 "NOT_OK" 0 "OK" ;
VAL_ 1471 RCU_a036_validityOnPartyBus 1 "NOT_OK" 0 "OK" ;
VAL_ 998 RCU_matrixIndex 0 "RCU_AlertMatrix0" ;
VAL_ 831 RCU_infoIndex 255 "END" 31 "SUBCOMPONENT_GITHASH" 30 "PACKAGE_SN_8_14" 29 "PACKAGE_SN_1_7" 27 "PACKAGE_PN_15_20" 26 "PACKAGE_PN_8_14" 25 "PACKAGE_PN_1_7" 23 "SUBCOMPONENT2" 22 "VARIANTCRC" 20 "UDS_PROTOCOL_BOOTCRC" 19 "VERSION_DEPRECATED" 18 "BOOTLOADER_GITHASH" 17 "APP_GITHASH" 16 "SUBCOMPONENT" 15 "BOOTLOADER_CRC" 14 "BOOTLOADER_SVN" 13 "APP_CRC" 11 "PCBAID_ASSYID_USAGEID" 10 "BUILD_HWID_COMPONENTID" 9 "DEPRECATED_9" 8 "DEPRECATED_8" 7 "DEPRECATED_7" 6 "DEPRECATED_6" 5 "DEPRECATED_5" 4 "DEPRECATED_4" 3 "DEPRECATED_3" 2 "DEPRECATED_2" 1 "DEPRECATED_1" 0 "DEPRECATED_0" ;
VAL_ 1344 SCCM_alertID 126 "a126_turnIndicatorHallMagOutOfRange" 125 "a125_turnIndicatorHallAngleMismatch" 124 "a124_turnIndicatorIdleInvalid" 123 "a123_turnIndicatorStuckActive" 122 "a122_turnIndicatorSpeedInvalid" 121 "a121_turnIndicatorAngleInvalid" 82 "a082_runtimeTestFailed" 81 "a081_startupTestFailed" 80 "a080_ADCSelfTestFailed" 79 "a079_chipTempOutOfRange" 78 "a078_ADCCalibrationError" 77 "a077_gearAngleNotPlausible" 76 "a076_memoryError_2" 75 "a075_hardwareError_2" 74 "a074_PLLLossOfLock" 73 "a073_watchdogReset" 72 "a072_spiBitErrors" 71 "a071_angleHallSensorError" 70 "a070_angleTrimMismatch" 69 "a069_calibrationMismatch" 68 "a068_CANLVPowerState_LOC" 67 "a067_CANBusOff_2" 66 "a066_angleSpeedNotPlausible" 65 "a065_angleNotPlausible" 64 "a064_angleSpeedOutOfRange_2" 63 "a063_angleOutOfRange_2" 62 "a062_voltageLow_2" 61 "a061_voltageHigh_2" 29 "a029_parkButtonMalfunction" 28 "a028_parkButtonShortToGround" 27 "a027_parkButtonOpenCircuit" 26 "a026_parkButtonInvalidSignal" 25 "a025_runTimeError" 24 "a024_gearStalkGenErr" 23 "a023_gearStalkShortCircuit" 22 "a022_gearStalkOpenCircuit" 21 "a021_gearStalkSignalInvalid" 20 "a020_angleInternalError" 19 "a019_angleOutOfRange" 18 "a018_angleSpeedOutOfRange" 17 "a017_memoryError" 16 "a016_hardwareError" 15 "a015_softwareError" 14 "a014_voltageLow" 13 "a013_voltageHigh" 12 "a012_turnGenErr" 11 "a011_turnIndHWErr" 10 "a010_turnIndShortToGnd" 9 "a009_turnIndOpen" 8 "a008_turnIndInvalidTrans" 7 "a007_turnIndComInfo" 6 "a006_tipWipeShortToGND" 5 "a005_tipWipeOpen" 4 "a004_highBeamShortToGND" 3 "a003_highBeamOpen" 2 "a002_CANTOut" 1 "a001_CANBusOff" 0 "ALERT_DO_NOT_USE_ZERO" ;
VAL_ 1344 SCCM_alertState 1 "SET" 0 "CLEARED" ;
VAL_ 1344 SCCM_a063_UntrimmedAngle 16383 "SNA" ;
VAL_ 1344 SCCM_a064_Speed 16383 "SNA" ;
VAL_ 1359 SCCM_matrixIndex 2 "AlertMatrix2" 1 "AlertMatrix1" 0 "AlertMatrix0" ;
VAL_ 816 SCCM_infoIndex 255 "END" 20 "UDS_PROTOCOL_BOOTCRC" 18 "BOOTLOADER_SVNHASH" 17 "APP_SVNHASH" 16 "SUBCOMPONENT1" 14 "BOOTLOADER_SVN" 13 "APP_CRC" 11 "PCBAID_ASSYID_USAGEID" 10 "BUILD_HWID_COMPONENTID" ;
VAL_ 816 SCCM_infoBuildType 4 "INFO_MFG_BUILD" 3 "INFO_TRACEABLE_CI_BUILD" 2 "INFO_LOCAL_BUILD" 1 "INFO_PLATFORM_BUILD" 0 "INFO_UNKNOWN_BUILD" ;
VAL_ 585 SCCM_highBeamStalkStatus 3 "SNA" 2 "PUSH" 1 "PULL" 0 "IDLE" ;
VAL_ 585 SCCM_washWipeButtonStatus 3 "SNA" 2 "2ND_DETENT" 1 "1ST_DETENT" 0 "NOT_PRESSED" ;
VAL_ 585 SCCM_turnIndicatorStalkStatus 9 "SNA" 8 "DOWN_2" 7 "DOWN_1_5" 6 "DOWN_1" 5 "DOWN_0_5" 4 "UP_2" 3 "UP_1_5" 2 "UP_1" 1 "UP_0_5" 0 "IDLE" ;
VAL_ 585 SCCM_turnIndicatorStalkAngle 4095 "SNA" ;
VAL_ 553 SCCM_rightStalkStatus 6 "SNA" 5 "INIT" 4 "DOWN_2" 3 "DOWN_1" 2 "UP_2" 1 "UP_1" 0 "IDLE" ;
VAL_ 553 SCCM_parkButtonStatus 3 "SNA" 2 "INIT" 1 "PRESSED" 0 "NOT_PRESSED" ;
VAL_ 297 SCCM_steeringAngleSensorStatus 3 "ERROR_INIT" 2 "ERROR" 1 "INIT" 0 "OK" ;
VAL_ 297 SCCM_steeringAngle 16383 "SNA" ;
VAL_ 297 SCCM_steeringAngleValidity 3 "SNA" 2 "INIT" 1 "VALID" 0 "INVALID" ;
VAL_ 1356 SCM_alertID 91 "a091_voltageRiseDetection" 78 "a078_voltageMatchTimeout" 76 "a076_bmsMIA" 74 "a074_isoVDiffHi" 44 "a044_proximityRationality" 27 "a027_externalIsolationLow" 0 "ALERT_DO_NOT_USE_ZERO" ;
VAL_ 1356 SCM_alertType 1 "SET" 0 "CLEARED" ;
VAL_ 1354 SCS_alertID 128 "a128_unused128" 127 "a127_unused127" 126 "a126_unused126" 125 "a125_unused125" 124 "a124_unused124" 123 "a123_unused123" 122 "a122_unused122" 121 "a121_unused121" 120 "a120_unused120" 119 "a119_unused119" 118 "a118_unused118" 117 "a117_unused117" 116 "a116_unused116" 115 "a115_unused115" 114 "a114_unused114" 113 "a113_unused113" 112 "a112_unused112" 111 "a111_unused111" 110 "a110_unused110" 109 "a109_unused109" 108 "a108_unused108" 107 "a107_unused107" 106 "a106_unused106" 105 "a105_unused105" 104 "a104_unused104" 103 "a103_unused103" 102 "a102_unused102" 101 "a101_unused101" 100 "a100_unused100" 99 "a099_unused99" 98 "a098_unused98" 97 "a097_unused97" 96 "a096_unused96" 95 "a095_unused95" 94 "a094_unused94" 93 "a093_unused93" 92 "a092_cabEnableDeasserted" 91 "a091_voltageRiseDetection" 90 "a090_negCordOT" 89 "a089_posCordOT" 88 "a088_negCordTempRationality" 87 "a087_posCordTempRationality" 86 "a086_lccResetDetected" 85 "a085_unused85" 84 "a084_unused84" 83 "a083_chargeCurrentLimited" 82 "a082_VbatUV" 81 "a081_rmsInputVoltageHigh" 80 "a080_lccFaulted" 79 "a079_unexpectedVbat" 78 "a078_voltageMatchTimeout" 77 "a077_unexpectedVbatBehavior" 76 "a076_bmsMIA" 75 "a075_unused75" 74 "a074_isoVDiffHi" 73 "a073_lccMIA" 72 "a072_gtwMIA" 71 "a071_chargerMIA" 70 "a070_vStageRationalityV2" 69 "a069_vStageRationalityV1" 68 "a068_vBatRationalityStage4" 67 "a067_vBatRationalityStage3" 66 "a066_vBatRationalityStage2" 65 "a065_vBatRationalityStage1" 64 "a064_vehicleCommandTimeout" 63 "a063_canRationality" 62 "a062_unused" 61 "a061_postOutOfService" 60 "a060_swHVIL" 59 "a059_memoryError" 58 "a058_adcRef" 57 "a057_watchdogReset" 56 "a056_stateTransitionDenied" 55 "a055_coolantLevelLow" 54 "a054_pumpRegulation" 53 "a053_unexpectedThermalBehavi" 52 "a052_ambientTempRationality" 51 "a051_cordTempRationality" 50 "a050_coolantTempRationality" 49 "a049_pcbaTempRationality" 48 "a048_ambientOT" 47 "a047_cordOT" 46 "a046_coolantOT" 45 "a045_pcbaOT" 44 "a044_proximityRationality" 43 "a043_pilotRationality" 42 "a042_pilotOutOfRange" 41 "a041_minus12VOutOfRange" 40 "a040_plus12VOutOfRange" 39 "a039_ibatRegulation" 38 "a038_contactorFailedOpen" 37 "a037_outputContactorWelded" 36 "a036_internalContactorWelded" 35 "a035_unexpectedVbusBehavior" 34 "a034_IBatRationality" 33 "a033_VBusRationality" 32 "a032_VBatRationality" 31 "a031_IbatOC" 30 "a030_VbusOV" 29 "a029_VbatOV" 28 "a028_isolationRationality" 27 "a027_externalIsolationLow" 26 "a026_internalIsolationLow" 25 "a025_internalIsolationFault" 24 "a024_emergencyShutdown" 21 "a021_unusedHW21" 20 "a020_unusedHW20" 19 "a019_unusedHW19" 18 "a018_unusedHW18" 17 "a017_unusedHW17" 16 "a016_unusedHW16" 15 "a015_cpldRationality" 14 "a014_coolantTempHiFoldBk" 13 "a013_cordTempHiFoldBk" 12 "a012_hwIllegalCntrCmdV2" 11 "a011_hwIllegalCntrCmdV1" 10 "a010_hwOpen_V2" 9 "a009_hwOpen_V1" 8 "a008_hwIllegalCntrShoot" 7 "a007_hwWeld_V2" 6 "a006_hwWeld_V1" 5 "a005_hwHVIL" 4 "a004_hwVbusOV" 3 "a003_hwCordOT" 2 "a002_hwIbatOC" 1 "a001_hwDSPfault" 0 "ALERT_DO_NOT_USE_ZERO" ;
VAL_ 1354 SCS_alertType 1 "SET" 0 "CLEARED" ;
VAL_ 1531 SDCR_alertID 34 "a034_phaseCurrentIrrational" 33 "a033_placeholder33" 32 "a032_placeholder32" 31 "a031_placeholder31" 30 "a030_placeholder30" 29 "a029_diMIA" 28 "a028_vcLVStateMIA" 27 "a027_diCanMIA" 26 "a026_faultCurrentMonitoringDisabled" 25 "a025_diSwitchingFdbkIrrational" 24 "a024_gtwMIA" 23 "a023_ecuLogAvailable" 22 "a022_TaskInitError" 21 "a021_busBarTempIrrational" 20 "a020_eepromSPIError" 19 "a019_historicalFaultCurrents" 18 "a018_historicalPyroTrigger" 17 "a017_adcSPIError" 16 "a016_systemReset" 15 "a015_phaseVIrrational" 14 "a014_vBusIrrational" 13 "a013_vBkupIrrational" 12 "a012_vBoostSecIrrational" 11 "a011_phaseCurrentOffset" 10 "a010_vrefIrrational" 9 "a009_uartVersionMismatch" 8 "a008_hvlinkMIA" 7 "a007_faultCurrentsDetected" 6 "a006_pyroTriggered" 5 "a005_motorSpeedIrrational" 4 "a004_pmRunningFdbkIrrational" 3 "a003_diUartMIA" 2 "a002_diPstSkipped" 1 "a001_powerOnSelfTestFailed" 0 "ALERT_DO_NOT_USE_ZERO" ;
VAL_ 1531 SDCR_alertState 1 "SET" 0 "CLEARED" ;
VAL_ 1531 SDCR_a001_fromState 7 "SKIPPED" 6 "FAILED" 5 "PASSED" 4 "TEST_PYRO_L_ON" 3 "TEST_PYRO_BOTH_OFF2" 2 "TEST_PYRO_H_ON" 1 "TEST_PYRO_BOTH_OFF1" 0 "PENDING" ;
VAL_ 1531 SDCR_a007_transientHandling 3 "3PS_WAITED" 2 "3PS_EARLY_EXIT" 1 "SKIPPED_3PS" 0 "ALL_SKIPPED" ;
VAL_ 1531 SDCR_a019_transientHandling 3 "3PS_WAITED" 2 "3PS_EARLY_EXIT" 1 "SKIPPED_3PS" 0 "ALL_SKIPPED" ;
VAL_ 1531 SDCR_a020_errorCode 201 "FAILED_WRITE_SANITY_CHECK" 200 "FAILED_READ_SANITY_CHECK" 4 "GENERIC_SPI_ERROR" 3 "MUTEX_ERROR" 2 "PAGE_ROLLOVER" 1 "ADDRESS_OUT_OF_BOUNDS" ;
VAL_ 1531 SDCR_a021_busBarTempC 0 "SNA" ;
VAL_ 1531 SDCR_a021_busBarTempA 0 "SNA" ;
VAL_ 1531 SDCR_a029_lvState 3 "FAULT" 2 "GOING_DOWN" 1 "ON" 0 "OFF" ;
VAL_ 1467 SDCR_matrixIndex 0 "SDCR_AlertMatrix0" ;
VAL_ 1597 SDCR_infoIndex 255 "END" 41 "SUBCOMPONENT14" 40 "SUBCOMPONENT13" 39 "SUBCOMPONENT12" 38 "SUBCOMPONENT11" 37 "SUBCOMPONENT10" 36 "SUBCOMPONENT9" 35 "SUBCOMPONENT8" 34 "SUBCOMPONENT7" 33 "SUBCOMPONENT6" 32 "SUBCOMPONENT5" 31 "SUBCOMPONENT4" 24 "SUBCOMPONENT3" 23 "SUBCOMPONENT2" 20 "UDS_PROTOCOL_BOOTCRC" 19 "VERSION_DEPRECATED" 18 "BOOTLOADER_GITHASH" 17 "APP_GITHASH" 16 "SUBCOMPONENT1" 15 "BOOTLOADER_CRC" 14 "BOOTLOADER_SVN" 13 "APP_CRC" 11 "PCBAID_ASSYID_USAGEID" 10 "BUILD_HWID_COMPONENTID" 9 "DEPRECATED_9" 8 "DEPRECATED_8" 7 "DEPRECATED_7" 6 "DEPRECATED_6" 5 "DEPRECATED_5" 4 "DEPRECATED_4" 3 "DEPRECATED_3" 2 "DEPRECATED_2" 1 "DEPRECATED_1" 0 "DEPRECATED_0" ;
VAL_ 1597 SDCR_infoBuildType 4 "INFO_MFG_BUILD" 3 "INFO_TRACEABLE_CI_BUILD" 2 "INFO_LOCAL_BUILD" 1 "INFO_PLATFORM_BUILD" 0 "INFO_UNKNOWN_BUILD" ;
